VERSION ""

NS_ :

BS_:

BU_: ETH

BO_ 1825 VCFRONT_debugThermal1Hz: 8 Vector__XXX
 SG_ VCFRONT_debugThermal1HzIndex M : 0|4@1+ (1,0) [0|0] "" Vector__XXX
 SG_ VCFRONT_coolantPumpTypeConfig m8 : 4|4@1+ (1,0) [0|0] "" Vector__XXX
 SG_ VCFRONT_mdotRefEvap m6 : 4|10@1+ (0.1,0) [0|0] "" Vector__XXX
 SG_ VCFRONT_modeDesiredPrevious m2 : 4|2@1+ (1,0) [0|0] "" Vector__XXX
 SG_ VCFRONT_pumpBatOverCurrentError m4 : 4|1@1+ (1,0) [0|0] "" Vector__XXX
 SG_ VCFRONT_pumpBatVsUnderVoltage m4 : 5|1@1+ (1,0) [0|0] "" Vector__XXX
 SG_ VCFRONT_modeHysteresisActive m2 : 6|1@1+ (1,0) [0|0] "" Vector__XXX
 SG_ VCFRONT_pumpBatVsOverVoltage m4 : 6|1@1+ (1,0) [0|0] "" Vector__XXX
 SG_ VCFRONT_modeSeriesAttainable m2 : 7|1@1+ (1,0) [0|0] "" Vector__XXX
 SG_ VCFRONT_pumpBatChpUnderVoltage m4 : 7|1@1+ (1,0) [0|0] "" Vector__XXX
 SG_ VCFRONT_activeLouverSpeedCmd m1 : 8|7@1+ (1,0) [0|0] "" Vector__XXX
 SG_ VCFRONT_activeSeriesReg m0 : 8|7@1+ (1,0) [0|0] "" Vector__XXX
 SG_ VCFRONT_condenserTempLimit m5 : 8|6@1+ (1,80) [0|0] "" Vector__XXX
 SG_ VCFRONT_modeParallelAttainable m2 : 8|1@1+ (1,0) [0|0] "" Vector__XXX
 SG_ VCFRONT_passiveSeriesReg m3 : 8|8@1- (1,0) [0|0] "" Vector__XXX
 SG_ VCFRONT_pumpBatVglUnderVoltage m4 : 8|1@1+ (1,0) [0|0] "" Vector__XXX
 SG_ VCFRONT_refrigerantTypeConfig m8 : 8|4@1+ (1,0) [0|0] "" Vector__XXX
 SG_ VCFRONT_subcoolCabinCondenser m7 : 8|6@1+ (1,0) [0|0] "" Vector__XXX
 SG_ VCFRONT_modeAmbientSourceAttainable m2 : 9|1@1+ (1,0) [0|0] "" Vector__XXX
 SG_ VCFRONT_pumpBatFetShortCircuit m4 : 9|1@1+ (1,0) [0|0] "" Vector__XXX
 SG_ VCFRONT_modeCop1Attainable m2 : 10|1@1+ (1,0) [0|0] "" Vector__XXX
 SG_ VCFRONT_pumpBatThOverTemperature m4 : 10|1@1+ (1,0) [0|0] "" Vector__XXX
 SG_ VCFRONT_copEvapActiveSinceLastDrive m2 : 11|1@1+ (1,0) [0|0] "" Vector__XXX
 SG_ VCFRONT_pumpBatLockedRotor m4 : 11|1@1+ (1,0) [0|0] "" Vector__XXX
 SG_ VCFRONT_compressorTypeConfig m8 : 12|4@1+ (1,0) [0|0] "" Vector__XXX
 SG_ VCFRONT_pumpBatJunctionTempWarn m4 : 12|1@1+ (1,0) [0|0] "" Vector__XXX
 SG_ VCFRONT_pumpBatJunctionOverTemp m4 : 13|1@1+ (1,0) [0|0] "" Vector__XXX
 SG_ VCFRONT_condenserActivePID m5 : 14|1@1+ (1,0) [0|0] "" Vector__XXX
 SG_ VCFRONT_mdotRefChiller m6 : 14|10@1+ (0.1,0) [0|0] "" Vector__XXX
 SG_ VCFRONT_pumpBatWatchdogTimeout m4 : 14|1@1+ (1,0) [0|0] "" Vector__XXX
 SG_ VCFRONT_activeLouverDirection m1 : 15|1@1+ (1,0) [0|0] "" Vector__XXX
 SG_ VCFRONT_condenserFeedfwdForChiller m5 : 15|1@1+ (1,0) [0|0] "" Vector__XXX
 SG_ VCFRONT_pumpBatStartUpOperation m4 : 15|1@1+ (1,0) [0|0] "" Vector__XXX
 SG_ VCFRONT_activeLouverBrakeEngaged m1 : 16|1@1+ (1,0) [0|0] "" Vector__XXX
 SG_ VCFRONT_activeParallelPTReg m0 : 16|7@1+ (1,0) [0|0] "" Vector__XXX
 SG_ VCFRONT_condenserFeedfwdForEvap m5 : 16|1@1+ (1,0) [0|0] "" Vector__XXX
 SG_ VCFRONT_passiveParallelPTReg m3 : 16|7@1+ (1,0) [0|0] "" Vector__XXX
 SG_ VCFRONT_pumpBatLossOfSpeedLock m4 : 16|1@1+ (1,0) [0|0] "" Vector__XXX
 SG_ VCFRONT_pumpBattPolePairConfig m8 : 16|4@1+ (1,0) [0|0] "" Vector__XXX
 SG_ VCFRONT_subcoolLcc m7 : 16|6@1+ (1,0) [0|0] "" Vector__XXX
 SG_ VCFRONT_burnInState m1 : 17|3@1+ (1,0) [0|0] "" Vector__XXX
 SG_ VCFRONT_condenserRegDemand m5 : 17|7@1+ (1,0) [0|0] "" Vector__XXX
 SG_ VCFRONT_pumpBatVccUnderVoltage m4 : 17|1@1+ (1,0) [0|0] "" Vector__XXX
 SG_ VCFRONT_pumpBatPwmInputFault m4 : 18|1@1+ (1,0) [0|0] "" Vector__XXX
 SG_ VCFRONT_pumpBatStatMode m4 : 19|2@1+ (1,0) [0|0] "" Vector__XXX
 SG_ VCFRONT_pumpPtPolePairConfig m8 : 20|4@1+ (1,0) [0|0] "" Vector__XXX
 SG_ VCFRONT_pumpBatStatOTPAny m4 : 21|1@1+ (1,0) [0|0] "" Vector__XXX
 SG_ VCFRONT_pumpBatStatSPIFail m4 : 22|1@1+ (1,0) [0|0] "" Vector__XXX
 SG_ VCFRONT_passiveParallelPTRegOn m3 : 23|1@1+ (1,0) [0|0] "" Vector__XXX
 SG_ VCFRONT_pumpBatStatDiagFail m4 : 23|1@1+ (1,0) [0|0] "" Vector__XXX
 SG_ VCFRONT_activeParallelBattReg m0 : 24|7@1+ (1,0) [0|0] "" Vector__XXX
 SG_ VCFRONT_condenserMinFanReq m5 : 24|7@1+ (1,0) [0|0] "" Vector__XXX
 SG_ VCFRONT_mdotRefCabinCondenser m6 : 24|10@1+ (0.1,0) [0|0] "" Vector__XXX
 SG_ VCFRONT_passiveSeriesRegMaxd m3 : 24|1@1+ (1,0) [0|0] "" Vector__XXX
 SG_ VCFRONT_pumpPtOverCurrentError m4 : 24|1@1+ (1,0) [0|0] "" Vector__XXX
 SG_ VCFRONT_superheatEvap m7 : 24|6@1+ (1,0) [0|0] "" Vector__XXX
 SG_ VCFRONT_supermanifoldTypeConfig m8 : 24|4@1+ (1,0) [0|0] "" Vector__XXX
 SG_ VCFRONT_passiveParallelPTRegMaxd m3 : 25|1@1+ (1,0) [0|0] "" Vector__XXX
 SG_ VCFRONT_pumpPtVsUnderVoltage m4 : 25|1@1+ (1,0) [0|0] "" Vector__XXX
 SG_ VCFRONT_pumpPtVsOverVoltage m4 : 26|1@1+ (1,0) [0|0] "" Vector__XXX
 SG_ VCFRONT_pumpPtChpUnderVoltage m4 : 27|1@1+ (1,0) [0|0] "" Vector__XXX
 SG_ VCFRONT_pumpPtVglUnderVoltage m4 : 28|1@1+ (1,0) [0|0] "" Vector__XXX
 SG_ VCFRONT_refrigFilterTypeConfig m8 : 28|2@1+ (1,0) [0|0] "" Vector__XXX
 SG_ VCFRONT_pumpPtFetShortCircuit m4 : 29|1@1+ (1,0) [0|0] "" Vector__XXX
 SG_ VCFRONT_pumpPtThOverTemperature m4 : 30|1@1+ (1,0) [0|0] "" Vector__XXX
 SG_ VCFRONT_refrigLccTypeConfig m8 : 30|2@1+ (1,0) [0|0] "" Vector__XXX
 SG_ VCFRONT_activeSeriesRegOn m0 : 31|1@1+ (1,0) [0|0] "" Vector__XXX
 SG_ VCFRONT_pumpPtLockedRotor m4 : 31|1@1+ (1,0) [0|0] "" Vector__XXX
 SG_ VCFRONT_activeParallelPTRegOn m0 : 32|1@1+ (1,0) [0|0] "" Vector__XXX
 SG_ VCFRONT_condenserMinLouverReq m5 : 32|7@1+ (1,0) [0|0] "" Vector__XXX
 SG_ VCFRONT_passiveDemandPumpPT m3 : 32|7@1+ (1,0) [0|0] "" Vector__XXX
 SG_ VCFRONT_pumpPtJunctionTempWarn m4 : 32|1@1+ (1,0) [0|0] "" Vector__XXX
 SG_ VCFRONT_superheatChiller m7 : 32|6@1+ (1,0) [0|0] "" Vector__XXX
 SG_ VCFRONT_activeParallelBattRegOn m0 : 33|1@1+ (1,0) [0|0] "" Vector__XXX
 SG_ VCFRONT_pumpPtJunctionOverTemp m4 : 33|1@1+ (1,0) [0|0] "" Vector__XXX
 SG_ VCFRONT_activeDemandPumpPT m0 : 34|7@1+ (1,0) [0|0] "" Vector__XXX
 SG_ VCFRONT_mdotRefLcc m6 : 34|10@1+ (0.1,0) [0|0] "" Vector__XXX
 SG_ VCFRONT_pumpPtWatchdogTimeout m4 : 34|1@1+ (1,0) [0|0] "" Vector__XXX
 SG_ VCFRONT_pumpPtStartUpOperation m4 : 35|1@1+ (1,0) [0|0] "" Vector__XXX
 SG_ VCFRONT_pumpPtLossOfSpeedLock m4 : 36|1@1+ (1,0) [0|0] "" Vector__XXX
 SG_ VCFRONT_pumpPtVccUnderVoltage m4 : 37|1@1+ (1,0) [0|0] "" Vector__XXX
 SG_ VCFRONT_pumpPtPwmInputFault m4 : 38|1@1+ (1,0) [0|0] "" Vector__XXX
 SG_ VCFRONT_pumpPtStatMode m4 : 39|2@1+ (1,0) [0|0] "" Vector__XXX
 SG_ VCFRONT_passiveDemandPumpBatt m3 : 40|7@1+ (1,0) [0|0] "" Vector__XXX
 SG_ VCFRONT_activeDemandPumpBatt m0 : 41|7@1+ (1,0) [0|0] "" Vector__XXX
 SG_ VCFRONT_pumpPtStatOTPAny m4 : 41|1@1+ (1,0) [0|0] "" Vector__XXX
 SG_ VCFRONT_pumpPtStatSPIFail m4 : 42|1@1+ (1,0) [0|0] "" Vector__XXX
 SG_ VCFRONT_pumpPtStatDiagFail m4 : 43|1@1+ (1,0) [0|0] "" Vector__XXX
 SG_ VCFRONT_fanRadOverCurrentError m4 : 44|1@1+ (1,0) [0|0] "" Vector__XXX
 SG_ VCFRONT_fanRadVsUnderVoltage m4 : 45|1@1+ (1,0) [0|0] "" Vector__XXX
 SG_ VCFRONT_fanRadVsOverVoltage m4 : 46|1@1+ (1,0) [0|0] "" Vector__XXX
 SG_ VCFRONT_fanRadChpUnderVoltage m4 : 47|1@1+ (1,0) [0|0] "" Vector__XXX
 SG_ VCFRONT_activeDemandFanRad m0 : 48|7@1+ (1,0) [0|0] "" Vector__XXX
 SG_ VCFRONT_fanRadVglUnderVoltage m4 : 48|1@1+ (1,0) [0|0] "" Vector__XXX
 SG_ VCFRONT_passiveDemandLouver m3 : 48|7@1+ (1,0) [0|0] "" Vector__XXX
 SG_ VCFRONT_fanRadFetShortCircuit m4 : 49|1@1+ (1,0) [0|0] "" Vector__XXX
 SG_ VCFRONT_fanRadThOverTemperature m4 : 50|1@1+ (1,0) [0|0] "" Vector__XXX
 SG_ VCFRONT_fanRadLockedRotor m4 : 51|1@1+ (1,0) [0|0] "" Vector__XXX
 SG_ VCFRONT_fanRadJunctionTempWarn m4 : 52|1@1+ (1,0) [0|0] "" Vector__XXX
 SG_ VCFRONT_fanRadJunctionOverTemp m4 : 53|1@1+ (1,0) [0|0] "" Vector__XXX
 SG_ VCFRONT_fanRadWatchdogTimeout m4 : 54|1@1+ (1,0) [0|0] "" Vector__XXX
 SG_ VCFRONT_activeDemandChiller m0 : 55|7@1+ (1,0) [0|0] "" Vector__XXX
 SG_ VCFRONT_fanRadStartUpOperation m4 : 55|1@1+ (1,0) [0|0] "" Vector__XXX
 SG_ VCFRONT_fanRadLossOfSpeedLock m4 : 56|1@1+ (1,0) [0|0] "" Vector__XXX
 SG_ VCFRONT_fanRadVccUnderVoltage m4 : 57|1@1+ (1,0) [0|0] "" Vector__XXX
 SG_ VCFRONT_fanRadPwmInputFault m4 : 58|1@1+ (1,0) [0|0] "" Vector__XXX
 SG_ VCFRONT_fanRadStatMode m4 : 59|2@1+ (1,0) [0|0] "" Vector__XXX
 SG_ VCFRONT_fanRadStatOTPAny m4 : 61|1@1+ (1,0) [0|0] "" Vector__XXX
 SG_ VCFRONT_fanRadStatSPIFail m4 : 62|1@1+ (1,0) [0|0] "" Vector__XXX
 SG_ VCFRONT_fanRadStatDiagFail m4 : 63|1@1+ (1,0) [0|0] "" Vector__XXX

BO_ 1828 VCFRONT_loadShedDebugStatus: 8 Vector__XXX
 SG_ VCFRONT_loadShedDebugStatusIndex M : 0|4@1+ (1,0) [0|0] "" Vector__XXX
 SG_ VCFRONT_loadShedReasonAPHeater m0 : 4|9@1+ (1,0) [0|0] "" Vector__XXX
 SG_ VCFRONT_loadShedReasonAutopilot m5 : 4|9@1+ (1,0) [0|0] "" Vector__XXX
 SG_ VCFRONT_loadShedReasonBatteryPump m1 : 4|9@1+ (1,0) [0|0] "" Vector__XXX
 SG_ VCFRONT_loadShedReasonCondenserFan m2 : 4|9@1+ (1,0) [0|0] "" Vector__XXX
 SG_ VCFRONT_loadShedReasonMCUAudio m8 : 4|9@1+ (1,0) [0|0] "" Vector__XXX
 SG_ VCFRONT_loadShedReasonMCUGraphic m7 : 4|9@1+ (1,0) [0|0] "" Vector__XXX
 SG_ VCFRONT_loadShedReasonPCS m9 : 4|9@1+ (1,0) [0|0] "" Vector__XXX
 SG_ VCFRONT_loadShedReasonPTPump m3 : 4|9@1+ (1,0) [0|0] "" Vector__XXX
 SG_ VCFRONT_loadShedReasonTAS m4 : 4|9@1+ (1,0) [0|0] "" Vector__XXX
 SG_ VCFRONT_loadShedReasonUI m6 : 4|9@1+ (1,0) [0|0] "" Vector__XXX
 SG_ VCFRONT_loadShedStsBatteryPump_duty m1 : 16|7@1+ (1,0) [0|0] "" Vector__XXX
 SG_ VCFRONT_loadShedStsCondenserFan_duty m2 : 16|7@1+ (1,0) [0|0] "" Vector__XXX
 SG_ VCFRONT_loadShedStsPTPump_duty m3 : 16|7@1+ (1,0) [0|0] "" Vector__XXX

BO_ 1829 VCBATT2_loadShedDebugStatus: 8 Vector__XXX
 SG_ VCBATT2_loadShedDebugStatusIndex M : 0|4@1+ (1,0) [0|0] "" Vector__XXX
 SG_ VCBATT2_loadShedReasonAPHeater m0 : 4|9@1+ (1,0) [0|0] "" Vector__XXX
 SG_ VCBATT2_loadShedReasonAutopilot m5 : 4|9@1+ (1,0) [0|0] "" Vector__XXX
 SG_ VCBATT2_loadShedReasonBatteryPump m1 : 4|9@1+ (1,0) [0|0] "" Vector__XXX
 SG_ VCBATT2_loadShedReasonCondenserFan m2 : 4|9@1+ (1,0) [0|0] "" Vector__XXX
 SG_ VCBATT2_loadShedReasonMCUAudio m8 : 4|9@1+ (1,0) [0|0] "" Vector__XXX
 SG_ VCBATT2_loadShedReasonMCUGraphic m7 : 4|9@1+ (1,0) [0|0] "" Vector__XXX
 SG_ VCBATT2_loadShedReasonPCS m9 : 4|9@1+ (1,0) [0|0] "" Vector__XXX
 SG_ VCBATT2_loadShedReasonPTPump m3 : 4|9@1+ (1,0) [0|0] "" Vector__XXX
 SG_ VCBATT2_loadShedReasonTAS m4 : 4|9@1+ (1,0) [0|0] "" Vector__XXX
 SG_ VCBATT2_loadShedReasonUI m6 : 4|9@1+ (1,0) [0|0] "" Vector__XXX
 SG_ VCBATT2_loadShedStsBatteryPump_duty m1 : 16|7@1+ (1,0) [0|0] "" Vector__XXX
 SG_ VCBATT2_loadShedStsCondenserFan_duty m2 : 16|7@1+ (1,0) [0|0] "" Vector__XXX
 SG_ VCBATT2_loadShedStsPTPump_duty m3 : 16|7@1+ (1,0) [0|0] "" Vector__XXX

BO_ 1830 VCLEFT_loadShedDebugStatus: 8 Vector__XXX
 SG_ VCLEFT_loadShedDebugStatusIndex M : 0|4@1+ (1,0) [0|0] "" Vector__XXX
 SG_ VCLEFT_loadShedReason12VAuxLoads m0 : 8|7@1+ (1,0) [0|0] "" Vector__XXX
 SG_ VCLEFT_loadShedReasonHVACBlower m1 : 8|7@1+ (1,0) [0|0] "" Vector__XXX
 SG_ VCLEFT_loadShedReasonLiftgate m2 : 8|7@1+ (1,0) [0|0] "" Vector__XXX
 SG_ VCLEFT_loadShedReasonMirrorHeater m3 : 8|7@1+ (1,0) [0|0] "" Vector__XXX
 SG_ VCLEFT_loadShedReasonMotorEncoders m4 : 8|7@1+ (1,0) [0|0] "" Vector__XXX
 SG_ VCLEFT_loadShedReasonSTWInOut m10 : 8|7@1+ (1,0) [0|0] "" Vector__XXX
 SG_ VCLEFT_loadShedReasonSTWUpDown m11 : 8|7@1+ (1,0) [0|0] "" Vector__XXX
 SG_ VCLEFT_loadShedReasonSeatBackrest m5 : 8|7@1+ (1,0) [0|0] "" Vector__XXX
 SG_ VCLEFT_loadShedReasonSeatHeaters m7 : 8|7@1+ (1,0) [0|0] "" Vector__XXX
 SG_ VCLEFT_loadShedReasonSeatLift m6 : 8|7@1+ (1,0) [0|0] "" Vector__XXX
 SG_ VCLEFT_loadShedReasonSeatTilt m8 : 8|7@1+ (1,0) [0|0] "" Vector__XXX
 SG_ VCLEFT_loadShedReasonSeatTrack m9 : 8|7@1+ (1,0) [0|0] "" Vector__XXX
 SG_ VCLEFT_loadShedReasonUSBPorts m12 : 8|7@1+ (1,0) [0|0] "" Vector__XXX
 SG_ VCLEFT_loadShedReasonWindowMotorsFront m13 : 8|7@1+ (1,0) [0|0] "" Vector__XXX
 SG_ VCLEFT_loadShedReasonWindowMotorsRear m14 : 8|7@1+ (1,0) [0|0] "" Vector__XXX
 SG_ VCLEFT_loadShedStsHVACBlower_duty m1 : 16|7@1+ (1,0) [0|0] "" Vector__XXX

BO_ 1831 VCRIGHT_loadShedDebugStatus: 8 Vector__XXX
 SG_ VCRIGHT_loadShedDebugStatusIndex M : 0|4@1+ (1,0) [0|0] "" Vector__XXX
 SG_ VCRIGHT_loadShedReasonMirrorHeater m0 : 8|7@1+ (1,0) [0|0] "" Vector__XXX
 SG_ VCRIGHT_loadShedReasonMotorEncoders m1 : 8|7@1+ (1,0) [0|0] "" Vector__XXX
 SG_ VCRIGHT_loadShedReasonPremAudio m2 : 8|7@1+ (1,0) [0|0] "" Vector__XXX
 SG_ VCRIGHT_loadShedReasonRearDefroster m3 : 8|7@1+ (1,0) [0|0] "" Vector__XXX
 SG_ VCRIGHT_loadShedReasonSeatBackrest m4 : 8|7@1+ (1,0) [0|0] "" Vector__XXX
 SG_ VCRIGHT_loadShedReasonSeatHeaters m5 : 8|7@1+ (1,0) [0|0] "" Vector__XXX
 SG_ VCRIGHT_loadShedReasonSeatLift m6 : 8|7@1+ (1,0) [0|0] "" Vector__XXX
 SG_ VCRIGHT_loadShedReasonSeatTilt m7 : 8|7@1+ (1,0) [0|0] "" Vector__XXX
 SG_ VCRIGHT_loadShedReasonSeatTrack m8 : 8|7@1+ (1,0) [0|0] "" Vector__XXX
 SG_ VCRIGHT_loadShedReasonUSBPorts m9 : 8|7@1+ (1,0) [0|0] "" Vector__XXX
 SG_ VCRIGHT_loadShedReasonWindowMotorsFront m10 : 8|7@1+ (1,0) [0|0] "" Vector__XXX
 SG_ VCRIGHT_loadShedReasonWindowMotorsRear m11 : 8|7@1+ (1,0) [0|0] "" Vector__XXX

BO_ 1834 BMS_serialNumber: 8 Vector__XXX
 SG_ BMS_serialNumberMultiplexer M : 0|2@1+ (1,0) [0|0] "" Vector__XXX
 SG_ BMS_packSerialBirthDateBinned m2 : 8|32@1+ (1,0) [0|0] "" Vector__XXX
 SG_ BMS_packSerialNumberByte01 m0 : 8|8@1+ (1,0) [0|0] "" Vector__XXX
 SG_ BMS_packSerialNumberByte08 m1 : 8|8@1+ (1,0) [0|0] "" Vector__XXX
 SG_ BMS_packSerialNumberByte02 m0 : 16|8@1+ (1,0) [0|0] "" Vector__XXX
 SG_ BMS_packSerialNumberByte09 m1 : 16|8@1+ (1,0) [0|0] "" Vector__XXX
 SG_ BMS_packSerialNumberByte03 m0 : 24|8@1+ (1,0) [0|0] "" Vector__XXX
 SG_ BMS_packSerialNumberByte10 m1 : 24|8@1+ (1,0) [0|0] "" Vector__XXX
 SG_ BMS_packSerialNumberByte04 m0 : 32|8@1+ (1,0) [0|0] "" Vector__XXX
 SG_ BMS_packSerialNumberByte11 m1 : 32|8@1+ (1,0) [0|0] "" Vector__XXX
 SG_ BMS_packSerialNumberByte05 m0 : 40|8@1+ (1,0) [0|0] "" Vector__XXX
 SG_ BMS_packSerialNumberByte12 m1 : 40|8@1+ (1,0) [0|0] "" Vector__XXX
 SG_ BMS_packSerialNumberByte06 m0 : 48|8@1+ (1,0) [0|0] "" Vector__XXX
 SG_ BMS_packSerialNumberByte13 m1 : 48|8@1+ (1,0) [0|0] "" Vector__XXX
 SG_ BMS_packSerialNumberByte07 m0 : 56|8@1+ (1,0) [0|0] "" Vector__XXX
 SG_ BMS_packSerialNumberByte14 m1 : 56|8@1+ (1,0) [0|0] "" Vector__XXX

BO_ 1835 XCP_tasRequest: 12 Vector__XXX
 SG_ XCP_tasRequest : 7|64@0+ (1,0) [0|0] "" Vector__XXX

BO_ 1842 XCP_bmsRequest: 12 Vector__XXX
 SG_ XCP_bmsRequestData : 7|64@0+ (1,0) [0|0] "" Vector__XXX

BO_ 1847 VCFRONT_LVBMS_info: 8 Vector__XXX
 SG_ VCFRONT_LVBMS_InfoIndex M : 0|8@1+ (1,0) [0|0] "" Vector__XXX
 SG_ VCFRONT_LVBMS_FWBuildType m3 : 8|8@1+ (1,0) [0|0] "" Vector__XXX
 SG_ VCFRONT_LVBMS_GitHash m2 : 8|16@1+ (1,0) [0|0] "" Vector__XXX
 SG_ VCFRONT_LVBMS_PcbaId m0 : 8|16@1+ (1,0) [0|0] "" Vector__XXX
 SG_ VCFRONT_LVBMS_UsageId m1 : 8|16@1+ (1,0) [0|0] "" Vector__XXX
 SG_ VCFRONT_LVBMS_serialNumber m4 : 8|24@1+ (1,0) [0|0] "" Vector__XXX
 SG_ VCFRONT_LVBMS_AppCRC m1 : 24|32@1+ (1,0) [0|0] "" Vector__XXX
 SG_ VCFRONT_LVBMS_AssemblyId m0 : 24|16@1+ (1,0) [0|0] "" Vector__XXX
 SG_ VCFRONT_LVBMS_mfgDay m4 : 32|5@1+ (1,0) [0|0] "" Vector__XXX
 SG_ VCFRONT_LVBMS_SubUsageId m0 : 40|16@1+ (1,0) [0|0] "" Vector__XXX
 SG_ VCFRONT_LVBMS_mfgMonth m4 : 40|4@1+ (1,0) [0|0] "" Vector__XXX
 SG_ VCFRONT_LVBMS_mfgYear m4 : 48|7@1+ (1,2011) [0|0] "" Vector__XXX

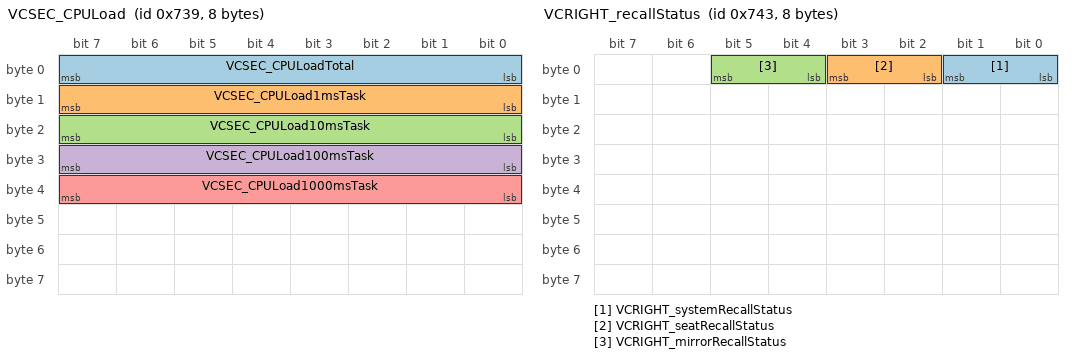
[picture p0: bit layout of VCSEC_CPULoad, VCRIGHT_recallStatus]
BO_ 1849 VCSEC_CPULoad: 8 Vector__XXX
 SG_ VCSEC_CPULoadTotal : 0|8@1+ (1,0) [0|0] "" Vector__XXX
 SG_ VCSEC_CPULoad1msTask : 8|8@1+ (1,0) [0|0] "" Vector__XXX
 SG_ VCSEC_CPULoad10msTask : 16|8@1+ (1,0) [0|0] "" Vector__XXX
 SG_ VCSEC_CPULoad100msTask : 24|8@1+ (1,0) [0|0] "" Vector__XXX
 SG_ VCSEC_CPULoad1000msTask : 32|8@1+ (1,0) [0|0] "" Vector__XXX

BO_ 1850 VC_LVBMS_brickMeasurements: 8 Vector__XXX
 SG_ VC_LVBMS_brickMeasurementsMultiplexer M : 0|6@1+ (1,0) [0|0] "" Vector__XXX
 SG_ VC_LVBMS_brickBalancingAh1 m1 : 8|24@1+ (0.001,0) [0|0] "" Vector__XXX
 SG_ VC_LVBMS_brickBalancingAh3 m2 : 8|24@1+ (0.001,0) [0|0] "" Vector__XXX
 SG_ VC_LVBMS_brickVoltage1 m0 : 8|13@1+ (0.001,0) [0|0] "" Vector__XXX
 SG_ VC_LVBMS_brickVoltage2 m0 : 24|13@1+ (0.001,0) [0|0] "" Vector__XXX
 SG_ VC_LVBMS_brickBalancingAh2 m1 : 32|24@1+ (0.001,0) [0|0] "" Vector__XXX
 SG_ VC_LVBMS_brickBalancingAh4 m2 : 32|24@1+ (0.001,0) [0|0] "" Vector__XXX
 SG_ VC_LVBMS_brickVoltage3 m0 : 37|13@1+ (0.001,0) [0|0] "" Vector__XXX
 SG_ VC_LVBMS_brickVoltage4 m0 : 50|13@1+ (0.001,0) [0|0] "" Vector__XXX
 SG_ VC_LVBMS_brickBalancingState1 m1 : 56|1@1+ (1,0) [0|0] "" Vector__XXX
 SG_ VC_LVBMS_brickBalancingState3 m2 : 56|1@1+ (1,0) [0|0] "" Vector__XXX
 SG_ VC_LVBMS_brickBalancingState2 m1 : 57|1@1+ (1,0) [0|0] "" Vector__XXX
 SG_ VC_LVBMS_brickBalancingState4 m2 : 57|1@1+ (1,0) [0|0] "" Vector__XXX

BO_ 1851 TAS_xcpResponse: 12 Vector__XXX
 SG_ TAS_xcpResponse : 7|64@0+ (1,0) [0|0] "" Vector__XXX

BO_ 1853 SDCR_debug: 8 Vector__XXX
 SG_ SDCR_debugOutputIndex M : 0|3@1+ (1,0) [0|0] "" Vector__XXX
 SG_ SDCR_cpuUsageCumulative m4 : 3|10@1+ (0.1,0) [0|0] "" Vector__XXX
 SG_ SDCR_vPhaseA m2 : 3|12@1+ (0.4,0) [0|0] "" Vector__XXX
 SG_ SDCR_busBarTempC m3 : 8|8@1+ (1,-40) [0|0] "" Vector__XXX
 SG_ SDCR_elcSpeed m1 : 8|16@1- (0.1,0) [0|0] "" Vector__XXX
 SG_ SDCR_pyroSenseV m0 : 8|8@1+ (0.02,0) [0|0] "" Vector__XXX
 SG_ SDCR_cpuUsage1MS m4 : 13|10@1+ (0.1,0) [0|0] "" Vector__XXX
 SG_ SDCR_busBarTempA m3 : 16|8@1+ (1,-40) [0|0] "" Vector__XXX
 SG_ SDCR_vPhaseB m2 : 16|12@1+ (0.4,0) [0|0] "" Vector__XXX
 SG_ SDCR_vref m0 : 16|8@1+ (0.02,0) [0|0] "" Vector__XXX
 SG_ SDCR_cpuUsage10MS m4 : 24|10@1+ (0.1,0) [0|0] "" Vector__XXX
 SG_ SDCR_lastMaxAbsSpeed m1 : 24|16@1- (0.1,0) [0|0] "" Vector__XXX
 SG_ SDCR_magI2 m0 : 24|16@1+ (34.33279926756695,0) [0|0] "" Vector__XXX
 SG_ SDCR_vPhaseC m2 : 28|12@1+ (0.4,0) [0|0] "" Vector__XXX
 SG_ SDCR_cpuUsage100MS m4 : 34|10@1+ (0.1,0) [0|0] "" Vector__XXX
 SG_ SDCR_maxSampleTime m1 : 40|12@1+ (0.1,0) [0|0] "" Vector__XXX
 SG_ SDCR_cpuUsageISR m4 : 44|10@1+ (0.1,0) [0|0] "" Vector__XXX
 SG_ SDCR_accumulatedSampleTime m1 : 52|12@1+ (0.1,0) [0|0] "" Vector__XXX

BO_ 1854 GB_vehLogData: 8 Vector__XXX
 SG_ GB_vehLogDataSelect M : 0|4@1+ (1,0) [0|0] "" Vector__XXX
 SG_ VEH_GB_Chg_Allowed m7 : 4|1@1+ (1,0) [0|0] "" Vector__XXX
 SG_ VEH_GB_Chg_ID_00_Tmt m11 : 4|2@1+ (1,0) [0|0] "" Vector__XXX
 SG_ VEH_GB_Chg_Stop_Rsn_SOC m9 : 4|2@1+ (1,0) [0|0] "" Vector__XXX
 SG_ VEH_GB_kwhChargeTotal_sent m8 : 4|1@1+ (1,0) [0|0] "" Vector__XXX
 SG_ VEH_teslaVin_muxSent m14 : 4|2@1+ (1,0) [0|0] "" Vector__XXX
 SG_ VEH_GB_Chg_ID_AA_Tmt m11 : 6|2@1+ (1,0) [0|0] "" Vector__XXX
 SG_ VEH_GB_Chg_Stop_Rsn_Pack_V m9 : 6|2@1+ (1,0) [0|0] "" Vector__XXX
 SG_ VEH_GB_BAT_Max_V_BHM m0 : 8|16@1+ (0.1,0) [0|0] "" Vector__XXX
 SG_ VEH_GB_BAT_Mfr_Name m2 : 8|32@1+ (1,0) [0|0] "" Vector__XXX
 SG_ VEH_GB_Chg_Max_I m3 : 8|16@1+ (0.1,-400) [0|0] "" Vector__XXX
 SG_ VEH_GB_Chg_Max_Output_Tmt m11 : 8|2@1+ (1,0) [0|0] "" Vector__XXX
 SG_ VEH_GB_Chg_Stop_Rsn_Cell_V m9 : 8|2@1+ (1,0) [0|0] "" Vector__XXX
 SG_ VEH_GB_Current_Demand m5 : 8|16@1+ (0.1,-400) [0|0] "" Vector__XXX
 SG_ VEH_GB_Final_SOC m10 : 8|8@1+ (1,0) [0|0] "" Vector__XXX
 SG_ VEH_GB_Meas_V m6 : 8|16@1+ (0.1,0) [0|0] "" Vector__XXX
 SG_ VEH_GB_Protocol_Ver_log m1 : 8|24@1+ (1,0) [0|0] "" Vector__XXX
 SG_ VEH_GB_Status m4 : 8|8@1+ (1,0) [0|0] "" Vector__XXX
 SG_ VEH_currentDemand_value_log m13 : 8|16@1- (1,0) [0|0] "" Vector__XXX
 SG_ VEH_teslaGbProtocolVersion_log m12 : 8|8@1+ (1,0) [0|0] "" Vector__XXX
 SG_ VEH_GB_CHG_Readiness_Tmt m11 : 10|2@1+ (1,0) [0|0] "" Vector__XXX
 SG_ VEH_GB_Chg_Stop_Rsn_CST m9 : 10|2@1+ (1,0) [0|0] "" Vector__XXX
 SG_ VEH_GB_Chg_Status_Tmt m11 : 12|2@1+ (1,0) [0|0] "" Vector__XXX
 SG_ VEH_GB_Chg_Stop_Rsn_Insul_Fault m9 : 12|2@1+ (1,0) [0|0] "" Vector__XXX
 SG_ VEH_GB_Chg_Stop_Rsn_Conn_OT_FLT m9 : 14|2@1+ (1,0) [0|0] "" Vector__XXX
 SG_ VEH_GB_Chg_Stop_Tmt m11 : 14|2@1+ (1,0) [0|0] "" Vector__XXX
 SG_ VEH_GB_Chg_Statistics_Tmt m11 : 16|2@1+ (1,0) [0|0] "" Vector__XXX
 SG_ VEH_GB_Chg_Stop_Rsn_BMS_OT_FLT m9 : 16|2@1+ (1,0) [0|0] "" Vector__XXX
 SG_ VEH_GB_Chg_Other_Tmt m11 : 18|6@1+ (1,0) [0|0] "" Vector__XXX
 SG_ VEH_GB_Chg_Stop_Rsn_Conn_FLT m9 : 18|2@1+ (1,0) [0|0] "" Vector__XXX
 SG_ VEH_GB_Chg_Stop_Rsn_Pack_OT_FLT m9 : 20|2@1+ (1,0) [0|0] "" Vector__XXX
 SG_ VEH_GB_Chg_Stop_Rsn_HVRelay_FLT m9 : 22|2@1+ (1,0) [0|0] "" Vector__XXX
 SG_ VEH_GB_BAT_SOC m3 : 24|16@1+ (0.1,0) [0|0] "" Vector__XXX
 SG_ VEH_GB_Chg_Stop_Rsn_VPt2_FLT m9 : 24|2@1+ (1,0) [0|0] "" Vector__XXX
 SG_ VEH_GB_Meas_I m6 : 24|16@1+ (0.1,-400) [0|0] "" Vector__XXX
 SG_ VEH_chargeCurrent_value_log m13 : 24|16@1- (1,0) [0|0] "" Vector__XXX
 SG_ VEH_GB_Chg_Stop_Rsn_Other_FLT m9 : 26|2@1+ (1,0) [0|0] "" Vector__XXX
 SG_ VEH_GB_Chg_Stop_Rsn_OC_ERR m9 : 28|2@1+ (1,0) [0|0] "" Vector__XXX
 SG_ VEH_GB_Chg_Stop_Rsn_V_ERR m9 : 30|2@1+ (1,0) [0|0] "" Vector__XXX
 SG_ VEH_GB_BAT_Cap_Ah m1 : 32|16@1+ (0.1,0) [0|0] "" Vector__XXX
 SG_ VEH_GB_Chg_Stop_Rsn_Param_Mismatch m9 : 32|2@1+ (1,0) [0|0] "" Vector__XXX
 SG_ VEH_GB_BAT_V m3 : 40|16@1+ (0.1,0) [0|0] "" Vector__XXX
 SG_ VEH_GB_SOC m6 : 40|8@1+ (1,0) [0|0] "" Vector__XXX
 SG_ VEH_currentDemand_exp_log m13 : 40|3@1- (1,0) [0|0] "" Vector__XXX
 SG_ VEH_chargeCurrent_exp_log m13 : 43|3@1- (1,0) [0|0] "" Vector__XXX
 SG_ VEH_GB_BAT_Max_V_BRM m1 : 48|16@1+ (0.1,0) [0|0] "" Vector__XXX
 SG_ VEH_GB_Rem_Chg_Time_Mins m6 : 48|16@1+ (1,0) [0|0] "" Vector__XXX

BO_ 1858 VCBATT1_LVBMS_statusHigh: 8 Vector__XXX
 SG_ VCBATT1_lvbmsStatusHighIndex M : 0|3@1+ (1,0) [0|0] "" Vector__XXX
 SG_ VCBATT1_LVBMS_MOSCommand m4 : 3|1@1+ (1,0) [0|0] "" Vector__XXX
 SG_ VCBATT1_LVBMS_packCurrent m0 : 3|22@1+ (0.001,-2000) [0|0] "" Vector__XXX
 SG_ VCBATT1_LVBMS_voltageTarget m3 : 3|16@1+ (0.001,0) [0|0] "" Vector__XXX
 SG_ VCBATT1_LVBMS_ClearErrorCntrCommand m4 : 4|1@1+ (1,0) [0|0] "" Vector__XXX
 SG_ VCBATT1_LVBMS_ClearHistoricFaultCommand m4 : 5|1@1+ (1,0) [0|0] "" Vector__XXX
 SG_ VCBATT1_LVBMS_ResetLVBMSCommand m4 : 6|1@1+ (1,0) [0|0] "" Vector__XXX
 SG_ VCBATT1_LVBMS_EnterHibernationCommand m4 : 7|1@1+ (1,0) [0|0] "" Vector__XXX
 SG_ VCBATT1_LVBMS_ECPAState m4 : 8|2@1+ (1,0) [0|0] "" Vector__XXX
 SG_ VCBATT1_LVBMS_sumCellVoltage m1 : 8|16@1+ (0.001,0) [0|0] "" Vector__XXX
 SG_ VCBATT1_totalLVLoadCurrent m2 : 8|14@1- (0.1,0) [0|0] "" Vector__XXX
 SG_ VCBATT1_LVBMS_MOSState m4 : 10|2@1+ (1,0) [0|0] "" Vector__XXX
 SG_ VCBATT1_LVBMS_VehicleState m4 : 12|2@1+ (1,0) [0|0] "" Vector__XXX
 SG_ VCBATT1_LVBMS_LINWakeDisabled m4 : 14|1@1+ (1,0) [0|0] "" Vector__XXX
 SG_ VCBATT1_LVBMS_chargeType m4 : 16|3@1+ (1,0) [0|0] "" Vector__XXX
 SG_ VCBATT1_LVBMS_cellAndArcProtEnabled m4 : 19|1@1+ (1,0) [0|0] "" Vector__XXX
 SG_ VCBATT1_LVBMS_currentTarget m3 : 19|18@1+ (0.001,-122) [0|0] "" Vector__XXX
 SG_ VCBATT1_LVPackChargeCurrentLimit m2 : 22|12@1+ (0.1,0) [0|0] "" Vector__XXX
 SG_ VCBATT1_LVBMS_avgBrickVoltage m4 : 24|13@1+ (0.001,0) [0|0] "" Vector__XXX
 SG_ VCBATT1_LVBMS_maxBrickVoltage m1 : 24|13@1+ (0.001,0) [0|0] "" Vector__XXX
 SG_ VCBATT1_LVBMS_packVoltage m0 : 25|16@1+ (0.001,0) [0|0] "" Vector__XXX
 SG_ VCBATT1_LVPackCurrent m2 : 34|14@1- (0.1,0) [0|0] "" Vector__XXX
 SG_ VCBATT1_LVBMS_maxAllowedChargeCurrent m3 : 37|13@1+ (0.1,0) [0|0] "" Vector__XXX
 SG_ VCBATT1_LVBMS_maxBrickVoltageIndex m1 : 40|8@1+ (1,0) [0|0] "" Vector__XXX
 SG_ VCBATT1_LVBMS_minBrickVoltage m4 : 40|13@1+ (0.001,0) [0|0] "" Vector__XXX
 SG_ VCBATT1_LVBMS_packTemperature m0 : 41|9@1+ (0.5,-50) [0|0] "" Vector__XXX
 SG_ VCBATT1_LVBMS_estimatedPackOcv m2 : 48|16@1+ (0.001,0) [0|0] "" Vector__XXX
 SG_ VCBATT1_LVBMS_MOSTemperature m0 : 50|12@1+ (0.5,-50) [0|0] "" Vector__XXX
 SG_ VCBATT1_LVBMS_maxAllowedDischargeCurrent m3 : 50|13@1+ (0.1,0) [0|0] "" Vector__XXX
 SG_ VCBATT1_LVBMS_minBrickVoltageIndex m4 : 56|8@1+ (1,0) [0|0] "" Vector__XXX

BO_ 1859 VCRIGHT_recallStatus: 8 Vector__XXX
 SG_ VCRIGHT_systemRecallStatus : 0|2@1+ (1,0) [0|0] "" Vector__XXX
 SG_ VCRIGHT_seatRecallStatus : 2|2@1+ (1,0) [0|0] "" Vector__XXX
 SG_ VCRIGHT_mirrorRecallStatus : 4|2@1+ (1,0) [0|0] "" Vector__XXX

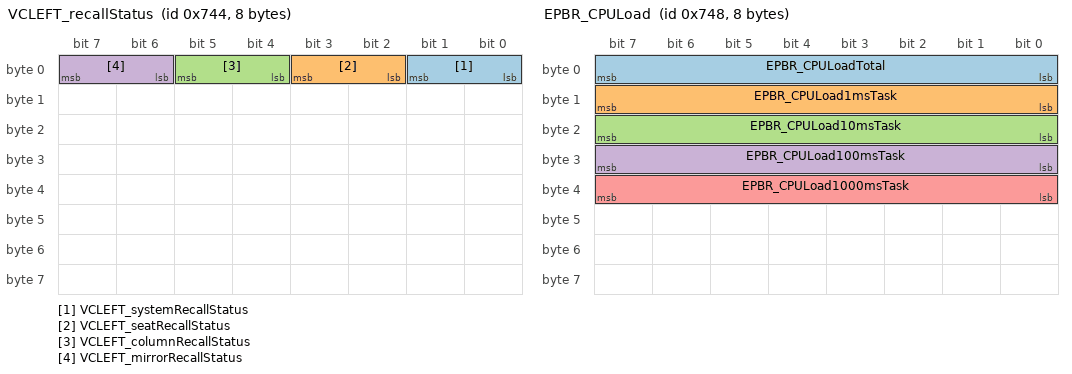
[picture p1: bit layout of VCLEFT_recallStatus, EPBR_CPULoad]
BO_ 1860 VCLEFT_recallStatus: 8 Vector__XXX
 SG_ VCLEFT_systemRecallStatus : 0|2@1+ (1,0) [0|0] "" Vector__XXX
 SG_ VCLEFT_seatRecallStatus : 2|2@1+ (1,0) [0|0] "" Vector__XXX
 SG_ VCLEFT_columnRecallStatus : 4|2@1+ (1,0) [0|0] "" Vector__XXX
 SG_ VCLEFT_mirrorRecallStatus : 6|2@1+ (1,0) [0|0] "" Vector__XXX

BO_ 1863 DBG_vdcControl: 8 Vector__XXX
 SG_ DBG_vdcDebugEnable : 0|1@1+ (1,0) [0|0] "" Vector__XXX

BO_ 1864 EPBR_CPULoad: 8 Vector__XXX
 SG_ EPBR_CPULoadTotal : 0|8@1+ (1,0) [0|0] "" Vector__XXX
 SG_ EPBR_CPULoad1msTask : 8|8@1+ (1,0) [0|0] "" Vector__XXX
 SG_ EPBR_CPULoad10msTask : 16|8@1+ (1,0) [0|0] "" Vector__XXX
 SG_ EPBR_CPULoad100msTask : 24|8@1+ (1,0) [0|0] "" Vector__XXX
 SG_ EPBR_CPULoad1000msTask : 32|8@1+ (1,0) [0|0] "" Vector__XXX

BO_ 1870 XCP_pmRequest: 12 Vector__XXX
 SG_ XCP_pmRequestData : 7|64@0+ (1,0) [0|0] "" Vector__XXX

BO_ 1871 PM_xcpResponse: 12 Vector__XXX
 SG_ PM_xcpResponseData : 7|64@0+ (1,0) [0|0] "" Vector__XXX

BO_ 1872 XCP_vcbattRequest: 8 Vector__XXX
 SG_ XCP_vcbattRequestData : 0|64@1+ (1,0) [0|0] "" Vector__XXX

BO_ 1873 XCP_vcbatt1Request: 8 Vector__XXX
 SG_ XCP_vcbatt1RequestData : 0|64@1+ (1,0) [0|0] "" Vector__XXX

BO_ 1874 BMS_debugInfo_100Hz: 8 Vector__XXX
 SG_ BMS_100HzDebug_Id M : 0|6@1+ (1,0) [0|0] "" Vector__XXX
 SG_ BMS_dbgLoadReg_output m2 : 6|11@1- (0.1,0) [0|0] "" Vector__XXX
 SG_ BMS_dbgSmWeldRequest m3 : 6|1@1+ (1,0) [0|0] "" Vector__XXX
 SG_ BMS_energyVoltageFloorReached m4 : 6|1@1+ (1,0) [0|0] "" Vector__XXX
 SG_ BMS_dbgSmChgModuleBlockingTrans m3 : 7|1@1+ (1,0) [0|0] "" Vector__XXX
 SG_ BMS_energyPowerTargetReached m4 : 7|1@1+ (1,0) [0|0] "" Vector__XXX
 SG_ BMS_brickOcvAvg m9 : 8|12@1+ (0.002,0) [0|0] "" Vector__XXX
 SG_ BMS_dbgCurrentReg_outIntegral m1 : 8|14@1- (0.1,0) [0|0] "" Vector__XXX
 SG_ BMS_dbgHvsTxErrorCount m6 : 8|8@1+ (1,0) [0|0] "" Vector__XXX
 SG_ BMS_dbgSmChargeCablePresent m3 : 8|1@1+ (1,0) [0|0] "" Vector__XXX
 SG_ BMS_dbgVoltageReg_Kp m0 : 8|9@1+ (5,0) [0|0] "" Vector__XXX
 SG_ BMS_energySimulationWalk m11 : 8|3@1+ (1,0) [0|0] "" Vector__XXX
 SG_ BMS_energySimulationWalkTime m10 : 8|14@1+ (0.1,0) [0|0] "" Vector__XXX
 SG_ BMS_energyWalkDone m4 : 8|1@1+ (1,0) [0|0] "" Vector__XXX
 SG_ BMS_energyWalkLoadedPackV m5 : 8|9@1+ (1,0) [0|0] "" Vector__XXX
 SG_ BMS_maxDeviationBrickId m12 : 8|8@1+ (1,1) [0|0] "" Vector__XXX
 SG_ BMS_measuredImpedanceNoise m13 : 8|12@1+ (0.001,0) [0|0] "" Vector__XXX
 SG_ BMS_socByDvStartPtInitialized m7 : 8|1@1+ (1,0) [0|0] "" Vector__XXX
 SG_ BMS_voltageInstabilityPresent m8 : 8|1@1+ (1,0) [0|0] "" Vector__XXX
 SG_ BMS_dbgSmChargeRequestActive m3 : 9|1@1+ (1,0) [0|0] "" Vector__XXX
 SG_ BMS_energySocLimitReached m4 : 9|1@1+ (1,0) [0|0] "" Vector__XXX
 SG_ BMS_socByDvStartCcv m7 : 9|12@1+ (0.002,0) [0|0] "" Vector__XXX
 SG_ BMS_voltageInstabilityFiltMedianCnts m8 : 9|12@1+ (0.1,0) [0|0] "" Vector__XXX
 SG_ BMS_dbgSmChargerActive m3 : 10|1@1+ (1,0) [0|0] "" Vector__XXX
 SG_ BMS_energyNotEnoughPower m4 : 10|1@1+ (1,0) [0|0] "" Vector__XXX
 SG_ BMS_dbgSmBmsWantsToCharge m3 : 11|1@1+ (1,0) [0|0] "" Vector__XXX
 SG_ BMS_energyTargetReached m4 : 11|1@1+ (1,0) [0|0] "" Vector__XXX
 SG_ BMS_dbgChargeState m3 : 12|4@1+ (1,0) [0|0] "" Vector__XXX
 SG_ BMS_energyWalkTimedOut m4 : 12|1@1+ (1,0) [0|0] "" Vector__XXX
 SG_ BMS_energyWalkId m4 : 13|3@1+ (1,0) [0|0] "" Vector__XXX
 SG_ BMS_dbgChargeNeeded m3 : 16|1@1+ (1,0) [0|0] "" Vector__XXX
 SG_ BMS_dbgHvsRxErrorCount m6 : 16|8@1+ (1,0) [0|0] "" Vector__XXX
 SG_ BMS_energyWalkTime m4 : 16|10@1+ (0.01,0) [0|0] "" Vector__XXX
 SG_ BMS_maxDeviationBrickImpedance m12 : 16|12@1+ (0.01,0) [0|0] "" Vector__XXX
 SG_ BMS_dbgOffsetReg_output m2 : 17|14@1- (0.1,0) [0|0] "" Vector__XXX
 SG_ BMS_dbgSmStateSupportRequired m3 : 17|1@1+ (1,0) [0|0] "" Vector__XXX
 SG_ BMS_dbgVoltageReg_Ki m0 : 17|11@1+ (1,0) [0|0] "" Vector__XXX
 SG_ BMS_energyWalkPackCurrent m5 : 17|15@1- (0.1,1000) [0|0] "" Vector__XXX
 SG_ BMS_dbgSmDriveActive m3 : 18|1@1+ (1,0) [0|0] "" Vector__XXX
 SG_ BMS_dbgFeimBlocking m3 : 19|1@1+ (1,0) [0|0] "" Vector__XXX
 SG_ BMS_brickOcvMax m9 : 20|12@1+ (0.002,0) [0|0] "" Vector__XXX
 SG_ BMS_dbgUdsCtrControlActive m3 : 20|1@1+ (1,0) [0|0] "" Vector__XXX
 SG_ BMS_normalizedDcrNoise m13 : 20|10@1+ (0.001,0) [0|0] "" Vector__XXX
 SG_ BMS_dbgEnoughPowerForSupport m3 : 21|1@1+ (1,0) [0|0] "" Vector__XXX
 SG_ BMS_socByDvStartCurrent m7 : 21|10@1- (1,0) [0|0] "" Vector__XXX
 SG_ BMS_voltageDiffPerSMax m8 : 21|11@1+ (0.00244140625,-2.5) [0|0] "" Vector__XXX
 SG_ BMS_chargeEnergyPackCurrent m10 : 24|13@1- (1,1000) [0|0] "" Vector__XXX
 SG_ BMS_dbgCurrentReg_outProp m1 : 24|14@1- (0.1,0) [0|0] "" Vector__XXX
 SG_ BMS_dbgHvsFaultConfinement m6 : 24|2@1+ (1,0) [0|0] "" Vector__XXX
 SG_ BMS_fcLinkLeakageTestStatus m3 : 24|3@1+ (1,0) [0|0] "" Vector__XXX
 SG_ BMS_dbgHvsBusIsOff m6 : 26|1@1+ (1,0) [0|0] "" Vector__XXX
 SG_ BMS_walkEnergy m4 : 26|11@1+ (0.1,0) [0|0] "" Vector__XXX
 SG_ BMS_dbgHvsGoToSleep m6 : 27|1@1+ (1,0) [0|0] "" Vector__XXX
 SG_ BMS_minTetheredLoadPresent m3 : 27|1@1+ (1,0) [0|0] "" Vector__XXX
 SG_ BMS_avgBrickImpedance m12 : 28|12@1+ (0.01,0) [0|0] "" Vector__XXX
 SG_ BMS_dbgVoltageReg_error m0 : 28|12@1- (0.00122,0) [0|0] "" Vector__XXX
 SG_ BMS_smHvUpRequestAllowed m3 : 28|1@1+ (1,0) [0|0] "" Vector__XXX
 SG_ BMS_fcCtrCleaningDesired m3 : 29|1@1+ (1,0) [0|0] "" Vector__XXX
 SG_ BMS_fcCtrCleaningAllowed m3 : 30|1@1+ (1,0) [0|0] "" Vector__XXX
 SG_ BMS_rawImpedanceDeviation m13 : 30|10@1+ (0.001,0) [0|0] "" Vector__XXX
 SG_ BMS_fcCtrCleaningActive m3 : 31|1@1+ (1,0) [0|0] "" Vector__XXX
 SG_ BMS_socByDvNetAh m7 : 31|9@1+ (0.002,0) [0|0] "" Vector__XXX
 SG_ BMS_brickOcvMin m9 : 32|12@1+ (0.002,0) [0|0] "" Vector__XXX
 SG_ BMS_dbgChargeNeededState m2 : 32|3@1+ (1,0) [0|0] "" Vector__XXX
 SG_ BMS_dbgHviTxErrorCount m6 : 32|8@1+ (1,0) [0|0] "" Vector__XXX
 SG_ BMS_energyWalkPackResistance m5 : 32|10@1+ (0.1,0) [0|0] "" Vector__XXX
 SG_ BMS_fcCtrCleaningPosCount m3 : 32|6@1+ (1,0) [0|0] "" Vector__XXX
 SG_ BMS_voltageInstabilityFltExcessNoise m8 : 32|12@1+ (0.1,0) [0|0] "" Vector__XXX
 SG_ BMS_dbgMaxDcCurrentAvailable m2 : 35|11@1+ (0.5,0) [0|0] "" Vector__XXX
 SG_ BMS_energyMaxBrickTemp m10 : 37|9@1+ (0.25,-25) [0|0] "" Vector__XXX
 SG_ BMS_energyWalkAhRemaining m4 : 37|12@1+ (0.1,0) [0|0] "" Vector__XXX
 SG_ BMS_dbgCurrentReg_error m1 : 40|12@1- (0.1,0) [0|0] "" Vector__XXX
 SG_ BMS_dbgHviRxErrorCount m6 : 40|8@1+ (1,0) [0|0] "" Vector__XXX
 SG_ BMS_dbgPeakRegenCurrentLimitMode m7 : 40|4@1+ (1,0) [0|0] "" Vector__XXX
 SG_ BMS_dbgVoltageReg_output m0 : 40|12@1- (0.5,0) [0|0] "" Vector__XXX
 SG_ BMS_fcCtrCleaningNegCount m3 : 40|6@1+ (1,0) [0|0] "" Vector__XXX
 SG_ BMS_missingCellExcessCurrentGain m13 : 40|8@1+ (0.05,0) [0|0] "" Vector__XXX
 SG_ BMS_snapshot1MaxVoltage m12 : 40|10@1+ (0.005,0) [0|0] "" Vector__XXX
 SG_ BMS_brickOcvSum m9 : 44|10@1+ (0.5,0) [0|0] "" Vector__XXX
 SG_ BMS_dbgDischargeCurrentLimitMode m7 : 44|4@1+ (1,0) [0|0] "" Vector__XXX
 SG_ BMS_voltageInstabilityMaxRawCnts m8 : 44|12@1+ (1,0) [0|0] "" Vector__XXX
 SG_ BMS_brickVoltagesClean m3 : 46|1@1+ (1,0) [0|0] "" Vector__XXX
 SG_ BMS_dbgCurrentReg_targetI m2 : 46|11@1+ (0.5,0) [0|0] "" Vector__XXX
 SG_ BMS_energyMinBrickTemp m10 : 46|9@1+ (0.25,-25) [0|0] "" Vector__XXX
 SG_ BMS_chargeSourcePresent m3 : 47|1@1+ (1,0) [0|0] "" Vector__XXX
 SG_ BMS_dbgHviFaultConfinement m6 : 48|2@1+ (1,0) [0|0] "" Vector__XXX
 SG_ BMS_energyWalkPackTemp m5 : 48|8@1- (1,40) [0|0] "" Vector__XXX
 SG_ BMS_missingCellImpedanceDeviation m13 : 48|10@1+ (0.001,0) [0|0] "" Vector__XXX
 SG_ BMS_energyWalkPackSoc m4 : 49|10@1+ (0.1,0) [0|0] "" Vector__XXX
 SG_ BMS_dbgHviBusIsOff m6 : 50|1@1+ (1,0) [0|0] "" Vector__XXX
 SG_ BMS_impedanceDevDeltaCurrent m12 : 50|12@1+ (1,-3000) [0|0] "" Vector__XXX
 SG_ BMS_instantPowerDissipation m9 : 54|10@1+ (0.25,0) [0|0] "" Vector__XXX
 SG_ BMS_energyCoolantOutletTemp m10 : 56|8@1+ (1,-50) [0|0] "" Vector__XXX
 SG_ BMS_voltageInstabilityMaxBrickVNumber m8 : 56|7@1+ (1,0) [0|0] "" Vector__XXX
 SG_ BMS_dbgCpUserChargeStatus m2 : 57|3@1+ (1,0) [0|0] "" Vector__XXX
 SG_ BMS_energyCounter m4 : 59|4@1+ (1,0) [0|0] "" Vector__XXX

BO_ 1875 XCP_vcrightRequest: 12 Vector__XXX
 SG_ XCP_vcrightRequestData : 7|64@0+ (1,0) [0|0] "" Vector__XXX

BO_ 1876 XCP_vcfrontRequest: 12 Vector__XXX
 SG_ XCP_vcfrontRequestData : 7|64@0+ (1,0) [0|0] "" Vector__XXX

BO_ 1877 XCP_vcsecRequest: 12 Vector__XXX
 SG_ XCP_vcsecRequestData : 7|64@0+ (1,0) [0|0] "" Vector__XXX

BO_ 1878 XCP_vcleftRequest: 12 Vector__XXX
 SG_ XCP_vcleftRequestData : 7|64@0+ (1,0) [0|0] "" Vector__XXX

BO_ 1879 DIF_debug: 8 Vector__XXX
 SG_ DIF_debugSelector M : 0|8@1+ (1,0) [0|0] "" Vector__XXX
 SG_ DIF_cpu10HzMin m66 : 8|8@1+ (0.4,0) [0|0] "" Vector__XXX
 SG_ DIF_cpu1HzMin m128 : 8|8@1+ (0.4,0) [0|0] "" Vector__XXX
 SG_ DIF_cpu1kHzMin m67 : 8|8@1+ (0.4,0) [0|0] "" Vector__XXX
 SG_ DIF_dcCapTemp m64 : 8|8@1+ (1,-40) [0|0] "" Vector__XXX
 SG_ DIF_gainScale m37 : 8|8@1+ (0.01,0) [0|0] "" Vector__XXX
 SG_ DIF_hwFaultCount m69 : 8|4@1+ (1,0) [0|0] "" Vector__XXX
 SG_ DIF_latchFeedback m50 : 8|1@1+ (1,0) [0|0] "" Vector__XXX
 SG_ DIF_lmScale m36 : 8|8@1+ (0.004,0) [0|0] "" Vector__XXX
 SG_ DIF_motorIA m32 : 8|16@1+ (0.1,0) [0|0] "" Vector__XXX
 SG_ DIF_offsetA m44 : 8|6@1- (0.763,0) [0|0] "" Vector__XXX
 SG_ DIF_oilPumpMotorSpeed m46 : 8|8@1+ (40,0) [0|0] "" Vector__XXX
 SG_ DIF_phaseOutBusbarTemp m70 : 8|8@1+ (1,-40) [0|0] "" Vector__XXX
 SG_ DIF_resolverOffsetCos m48 : 8|8@1+ (0.015,0) [0|0] "" Vector__XXX
 SG_ DIF_rotorOffsetEst m43 : 8|12@1- (0.01,0) [0|0] "" Vector__XXX
 SG_ DIF_rsScale m34 : 8|8@1+ (0.01,0) [0|0] "" Vector__XXX
 SG_ DIF_soptTimeToTrip m49 : 8|8@1+ (0.05,0) [0|0] "" Vector__XXX
 SG_ DIF_statorEndWindingTemp m72 : 8|8@1+ (1,-40) [0|0] "" Vector__XXX
 SG_ DIF_statorIDref m33 : 8|16@1- (0.1,0) [0|0] "" Vector__XXX
 SG_ DIF_systemStack m68 : 8|8@1+ (0.4,0) [0|0] "" Vector__XXX
 SG_ DIF_tqSatThermal m39 : 8|8@1+ (0.4,0) [0|0] "" Vector__XXX
 SG_ DIF_tqScaleDifferential m35 : 8|8@1+ (0.4,0) [0|0] "" Vector__XXX
 SG_ DIF_mechssLatchesActive m50 : 9|1@1+ (1,0) [0|0] "" Vector__XXX
 SG_ DIF_usmState m38 : 12|3@1+ (1,0) [0|0] "" Vector__XXX
 SG_ DIF_busbarTemp m64 : 16|8@1+ (1,-40) [0|0] "" Vector__XXX
 SG_ DIF_cpu10HzAvg m66 : 16|8@1+ (0.4,0) [0|0] "" Vector__XXX
 SG_ DIF_cpu1HzAvg m128 : 16|8@1+ (0.4,0) [0|0] "" Vector__XXX
 SG_ DIF_cpu1kHzAvg m67 : 16|8@1+ (0.4,0) [0|0] "" Vector__XXX
 SG_ DIF_cpuIDWord0 m131 : 16|16@1+ (1,0) [0|0] "" Vector__XXX
 SG_ DIF_cpuIDWord1 m132 : 16|16@1+ (1,0) [0|0] "" Vector__XXX
 SG_ DIF_idleStack m68 : 16|8@1+ (0.4,0) [0|0] "" Vector__XXX
 SG_ DIF_lvBoostedRail m50 : 16|8@1+ (0.08,0) [0|0] "" Vector__XXX
 SG_ DIF_offsetB m44 : 16|6@1- (0.763,0) [0|0] "" Vector__XXX
 SG_ DIF_oilPumpPhaseVoltage m46 : 16|8@1+ (0.3,0) [0|0] "" Vector__XXX
 SG_ DIF_peakIQref m38 : 16|16@1+ (0.1,0) [0|0] "" Vector__XXX
 SG_ DIF_phaseOutBusbarWeldTemp m70 : 16|8@1+ (1,-40) [0|0] "" Vector__XXX
 SG_ DIF_resolverCosRmsSquared m52 : 16|8@1+ (0.005,0) [0|0] "" Vector__XXX
 SG_ DIF_resolverOffsetSin m48 : 16|8@1+ (0.015,0) [0|0] "" Vector__XXX
 SG_ DIF_rotorFlux m47 : 16|16@1+ (0.0001,0) [0|0] "" Vector__XXX
 SG_ DIF_rotorMaxMagnetTemp m72 : 16|8@1+ (1,-40) [0|0] "" Vector__XXX
 SG_ DIF_soptTripDelay m49 : 16|8@1+ (0.05,0) [0|0] "" Vector__XXX
 SG_ DIF_statorFluxRef m35 : 16|16@1+ (0.0001,0) [0|0] "" Vector__XXX
 SG_ DIF_statorIQref m34 : 16|16@1- (0.1,0) [0|0] "" Vector__XXX
 SG_ DIF_statorVDFiltered m63 : 16|16@1- (4e-05,0) [0|0] "" Vector__XXX
 SG_ DIF_statorVQ m36 : 16|16@1- (4e-05,0) [0|0] "" Vector__XXX
 SG_ DIF_tcMaxRequest m40 : 16|8@1+ (5,0) [0|0] "" Vector__XXX
 SG_ DIF_rotorOffsetMean m43 : 20|12@1- (0.01,0) [0|0] "" Vector__XXX
 SG_ DIF_activeDischargeRail m50 : 24|8@1+ (0.3,0) [0|0] "" Vector__XXX
 SG_ DIF_cpu100HzMin m66 : 24|8@1+ (0.4,0) [0|0] "" Vector__XXX
 SG_ DIF_cpu20kHzMin m67 : 24|8@1+ (0.4,0) [0|0] "" Vector__XXX
 SG_ DIF_decodeHardwareStack m68 : 24|8@1+ (0.4,0) [0|0] "" Vector__XXX
 SG_ DIF_lightSenseV m72 : 24|6@1+ (0.1,0) [0|0] "" Vector__XXX
 SG_ DIF_llsScale m42 : 24|8@1+ (0.004,0) [0|0] "" Vector__XXX
 SG_ DIF_motorIB m32 : 24|16@1+ (0.1,0) [0|0] "" Vector__XXX
 SG_ DIF_oilPumpPressureEstimateMax m46 : 24|8@1+ (2,0) [0|0] "" Vector__XXX
 SG_ DIF_pcsTemp m64 : 24|8@1+ (1,-40) [0|0] "" Vector__XXX
 SG_ DIF_phaseOutLugTemp m70 : 24|8@1+ (1,-40) [0|0] "" Vector__XXX
 SG_ DIF_resolverPhaseOffset m48 : 24|8@1+ (0.4,0) [0|0] "" Vector__XXX
 SG_ DIF_resolverSinRmsSquared m52 : 24|8@1+ (0.005,0) [0|0] "" Vector__XXX
 SG_ DIF_soptTimeToOff m49 : 24|11@1+ (0.05,0) [0|0] "" Vector__XXX
 SG_ DIF_statorIDfdb m33 : 24|16@1- (0.1,0) [0|0] "" Vector__XXX
 SG_ DIF_tcMinRequest m40 : 24|8@1+ (5,0) [0|0] "" Vector__XXX
 SG_ DIF_pyroSenseV m72 : 30|8@1+ (0.02,0) [0|0] "" Vector__XXX
 SG_ DIF_cpu100HzAvg m66 : 32|8@1+ (0.4,0) [0|0] "" Vector__XXX
 SG_ DIF_cpu20kHzAvg m67 : 32|8@1+ (0.4,0) [0|0] "" Vector__XXX
 SG_ DIF_cpuIDWord2 m132 : 32|16@1+ (1,0) [0|0] "" Vector__XXX
 SG_ DIF_crc m131 : 32|32@1+ (1,0) [0|0] "" Vector__XXX
 SG_ DIF_dcCableHeat m47 : 32|16@1+ (0.001,0) [0|0] "" Vector__XXX
 SG_ DIF_dcLinkCapTemp m70 : 32|8@1+ (1,-40) [0|0] "" Vector__XXX
 SG_ DIF_driveUnitOdometer m69 : 32|32@1+ (10,0) [0|0] "" Vector__XXX
 SG_ DIF_eepromStack m68 : 32|8@1+ (0.4,0) [0|0] "" Vector__XXX
 SG_ DIF_llrScale m42 : 32|8@1+ (0.015,0) [0|0] "" Vector__XXX
 SG_ DIF_loadAngleMargin m37 : 32|16@1- (0.0003,0) [0|0] "" Vector__XXX
 SG_ DIF_motorIAavg m38 : 32|16@1- (0.1,0) [0|0] "" Vector__XXX
 SG_ DIF_oilPumpPressureExpectedMin m46 : 32|8@1+ (2,0) [0|0] "" Vector__XXX
 SG_ DIF_preregulatorRail m50 : 32|8@1+ (0.15,0) [0|0] "" Vector__XXX
 SG_ DIF_resolverCommonGain m48 : 32|8@1+ (0.025,0) [0|0] "" Vector__XXX
 SG_ DIF_resolverCosFiltered m52 : 32|8@1- (0.01,0) [0|0] "" Vector__XXX
 SG_ DIF_statorFluxFdb m35 : 32|16@1+ (0.0001,0) [0|0] "" Vector__XXX
 SG_ DIF_statorIQfdb m34 : 32|16@1- (0.1,0) [0|0] "" Vector__XXX
 SG_ DIF_statorTemp1 m64 : 32|8@1+ (1,-40) [0|0] "" Vector__XXX
 SG_ DIF_statorVD m36 : 32|16@1- (4e-05,0) [0|0] "" Vector__XXX
 SG_ DIF_statorVQFiltered m63 : 32|16@1- (4e-05,0) [0|0] "" Vector__XXX
 SG_ DIF_tqSatMotorVoltage m39 : 32|8@1+ (0.4,0) [0|0] "" Vector__XXX
 SG_ DIF_wasteCurrentLimit m41 : 32|16@1+ (0.1,0) [0|0] "" Vector__XXX
 SG_ DIF_controlStack m67 : 40|8@1+ (0.4,0) [0|0] "" Vector__XXX
 SG_ DIF_cpu10msMin m66 : 40|8@1+ (0.4,0) [0|0] "" Vector__XXX
 SG_ DIF_hvDcCableTemp m70 : 40|8@1+ (1,-40) [0|0] "" Vector__XXX
 SG_ DIF_loadAngle m42 : 40|16@1- (0.0003,0) [0|0] "" Vector__XXX
 SG_ DIF_motorIC m32 : 40|16@1+ (0.1,0) [0|0] "" Vector__XXX
 SG_ DIF_resolverReady m48 : 40|1@1+ (1,0) [0|0] "" Vector__XXX
 SG_ DIF_resolverSinFiltered m52 : 40|8@1- (0.01,0) [0|0] "" Vector__XXX
 SG_ DIF_soptMaxCurrentMagSqrd m49 : 40|16@1+ (100,0) [0|0] "" Vector__XXX
 SG_ DIF_statorTemp2 m64 : 40|8@1+ (1,-40) [0|0] "" Vector__XXX
 SG_ DIF_torquePerAmp m33 : 40|16@1+ (0.0001,0) [0|0] "" Vector__XXX
 SG_ DIF_tqSatMotorCurrent m39 : 40|8@1+ (0.4,0) [0|0] "" Vector__XXX
 SG_ DIF_udsStack m68 : 40|8@1+ (0.4,0) [0|0] "" Vector__XXX
 SG_ DIF_resolverNoCarrier m48 : 41|1@1+ (1,0) [0|0] "" Vector__XXX
 SG_ DIF_resolverNoPhaseLock m48 : 42|1@1+ (1,0) [0|0] "" Vector__XXX
 SG_ DIF_resolverClaMIA m48 : 43|1@1+ (1,0) [0|0] "" Vector__XXX
 SG_ DIF_statorSlotWindingTemp m72 : 46|8@1+ (1,-40) [0|0] "" Vector__XXX
 SG_ DIF_cpuIDWord3 m132 : 48|16@1+ (1,0) [0|0] "" Vector__XXX
 SG_ DIF_internalAngleFilt m37 : 48|16@1+ (0.0003,0) [0|0] "" Vector__XXX
 SG_ DIF_magnetTempEst m47 : 48|8@1+ (1,-40) [0|0] "" Vector__XXX
 SG_ DIF_module10HzStack m66 : 48|8@1+ (0.4,0) [0|0] "" Vector__XXX
 SG_ DIF_motorIBavg m38 : 48|16@1- (0.1,0) [0|0] "" Vector__XXX
 SG_ DIF_motorV m34 : 48|16@1+ (2e-05,0) [0|0] "" Vector__XXX
 SG_ DIF_negDcBusbarTemp m70 : 48|8@1+ (1,-40) [0|0] "" Vector__XXX
 SG_ DIF_peakFlux m36 : 48|16@1+ (0.0001,0) [0|0] "" Vector__XXX
 SG_ DIF_phaseImbalanceFactor m35 : 48|16@1+ (0.0001,0) [0|0] "" Vector__XXX
 SG_ DIF_pwmState m63 : 48|2@1+ (1,0) [0|0] "" Vector__XXX
 SG_ DIF_resolverErrorRmsSquared m52 : 48|8@1+ (0.005,0) [0|0] "" Vector__XXX
 SG_ DIF_tqScaleMaxMotorSpeed m40 : 48|8@1+ (0.4,0) [0|0] "" Vector__XXX
 SG_ DIF_xcpStack m68 : 48|8@1+ (0.4,0) [0|0] "" Vector__XXX
 SG_ DIF_intervalMaxHvBusV m72 : 54|10@1+ (1,0) [0|0] "" Vector__XXX
 SG_ DIF_immobilizerStack m68 : 56|8@1+ (0.4,0) [0|0] "" Vector__XXX
 SG_ DIF_posDcBusbarTemp m70 : 56|8@1+ (1,-40) [0|0] "" Vector__XXX

BO_ 1881 XCP_vcfront1Request: 8 Vector__XXX
 SG_ XCP_vcfront1RequestData : 0|64@1+ (1,0) [0|0] "" Vector__XXX

BO_ 1882 XCP_vcfront2Request: 8 Vector__XXX
 SG_ XCP_vcfront2RequestData : 0|64@1+ (1,0) [0|0] "" Vector__XXX

BO_ 1883 XCP_vcbatt2Request: 8 Vector__XXX
 SG_ XCP_vcbatt2RequestData : 0|64@1+ (1,0) [0|0] "" Vector__XXX

BO_ 1885 CP_loggingFast: 8 Vector__XXX
 SG_ CP_loggingFastSelect M : 0|4@1+ (1,0) [0|0] "" Vector__XXX
 SG_ CP_UHF_controlState m2 : 4|4@1+ (1,0) [0|0] "" Vector__XXX
 SG_ CP_doorPresenceSensorV m3 : 4|12@1+ (0.001221,0) [0|0] "" Vector__XXX
 SG_ CP_inductiveSensor_raw m0 : 4|28@1+ (1,0) [0|0] "" Vector__XXX
 SG_ CP_latchLastEngageRequestMaxV m4 : 4|10@1+ (0.017595307917888565,0) [0|0] "" Vector__XXX
 SG_ CP_latchPot m1 : 4|12@1+ (0.025,0) [0|0] "" Vector__XXX
 SG_ CP_v2xState m5 : 4|3@1+ (1,0) [0|0] "" Vector__XXX
 SG_ CP_proximityV m2 : 8|16@1+ (0.0001,0) [0|0] "" Vector__XXX
 SG_ CP_v2xCommsState m5 : 8|3@1+ (1,0) [0|0] "" Vector__XXX
 SG_ CP_v2xRetryAttempts m5 : 11|4@1+ (1,0) [0|0] "" Vector__XXX
 SG_ CP_latchLastEngageRequestMaxI m4 : 14|10@1+ (0.004887585532746823,0) [0|0] "" Vector__XXX
 SG_ CP_activeV2xBlocker m5 : 16|5@1+ (1,0) [0|0] "" Vector__XXX
 SG_ CP_doorLastRequestMaxI m1 : 16|12@1+ (0.0025,0) [0|0] "" Vector__XXX
 SG_ CP_doorOpenRequest m3 : 16|4@1+ (1,0) [0|0] "" Vector__XXX
 SG_ CP_doorOpenEndOfDriveReason m3 : 20|3@1+ (1,0) [0|0] "" Vector__XXX
 SG_ CP_lastV2xShutdownTrigger m5 : 21|5@1+ (1,0) [0|0] "" Vector__XXX
 SG_ CP_coverClosed m3 : 23|1@1+ (1,0) [0|0] "" Vector__XXX
 SG_ CP_doorCloseEndOfDriveReason m3 : 24|3@1+ (1,0) [0|0] "" Vector__XXX
 SG_ CP_latchLastDisengageRequestMaxV m4 : 24|10@1+ (0.017595307917888565,0) [0|0] "" Vector__XXX
 SG_ CP_proximityV_GBCC1 m2 : 24|14@1+ (0.001,0) [0|0] "" Vector__XXX
 SG_ CP_doorCloseRequest m3 : 27|5@1+ (1,0) [0|0] "" Vector__XXX
 SG_ CP_doorLastRequestMaxV m1 : 28|10@1+ (0.017595307917888565,0) [0|0] "" Vector__XXX
 SG_ CP_doorOpenActuationTime m0 : 32|14@1+ (1,0) [0|0] "" Vector__XXX
 SG_ CP_latchDisengagingTime m3 : 32|10@1+ (1,0) [0|0] "" Vector__XXX
 SG_ CP_latchLastDisengageRequestMaxI m4 : 34|10@1+ (0.004887585532746823,0) [0|0] "" Vector__XXX
 SG_ CP_digitalCommsAttempts m5 : 37|3@1+ (1,0) [0|0] "" Vector__XXX
 SG_ CP_pilotPulseWidth m1 : 38|12@1+ (1,0) [0|0] "" Vector__XXX
 SG_ CP_proximityV_GBCC2 m2 : 38|14@1+ (0.001,0) [0|0] "" Vector__XXX
 SG_ CP_evseGridFormRequestVersion m5 : 40|2@1+ (1,0) [0|0] "" Vector__XXX
 SG_ CP_evseGridFormState m5 : 42|3@1+ (1,0) [0|0] "" Vector__XXX
 SG_ CP_latchEngagingTime m3 : 42|10@1+ (1,0) [0|0] "" Vector__XXX
 SG_ CP_latchLastEngageMaxVelocity m4 : 44|10@1- (8.013698630136986,0) [0|0] "" Vector__XXX
 SG_ CP_evsePilotPowerNeeded m5 : 45|1@1+ (1,0) [0|0] "" Vector__XXX
 SG_ CP_doorCloseActuationTime m0 : 46|14@1+ (1,0) [0|0] "" Vector__XXX
 SG_ CP_v2xAccessoryUpdateWithoutExternalPower m5 : 46|1@1+ (1,0) [0|0] "" Vector__XXX
 SG_ CP_doorPotObserverEstimated m5 : 47|12@1+ (0.025,0) [0|0] "" Vector__XXX
 SG_ CP_pilotPeriod m1 : 50|12@1+ (1,0) [0|0] "" Vector__XXX
 SG_ CP_doorPot m2 : 52|12@1+ (0.025,0) [0|0] "" Vector__XXX
 SG_ CP_latchDisengagingStopReason m3 : 52|3@1+ (1,0) [0|0] "" Vector__XXX
 SG_ CP_latchLastDisengageMaxVelocity m4 : 54|10@1- (8.013698630136986,0) [0|0] "" Vector__XXX
 SG_ CP_latchEngagingStopReason m3 : 55|3@1+ (1,0) [0|0] "" Vector__XXX
 SG_ CP_pilotUnlatchRequestActive m3 : 58|1@1+ (1,0) [0|0] "" Vector__XXX
 SG_ CP_doorIdDetectionState m3 : 59|2@1+ (1,0) [0|0] "" Vector__XXX
 SG_ CP_doorObserverEstimationIsActive m5 : 59|1@1+ (1,0) [0|0] "" Vector__XXX
 SG_ CP_chargeCableSecured m0 : 60|1@1+ (1,0) [0|0] "" Vector__XXX
 SG_ CP_doorPositionSource m5 : 60|2@1+ (1,0) [0|0] "" Vector__XXX
 SG_ CP_chargeCablePresent m0 : 61|1@1+ (1,0) [0|0] "" Vector__XXX
 SG_ CP_doorIdDetectedBin m3 : 61|2@1+ (1,0) [0|0] "" Vector__XXX
 SG_ CP_latchCheckAvailable m0 : 62|1@1+ (1,0) [0|0] "" Vector__XXX
 SG_ CP_proxConn1Sense m1 : 62|1@1+ (1,0) [0|0] "" Vector__XXX
 SG_ CP_proxEn m1 : 63|1@1+ (1,0) [0|0] "" Vector__XXX
 SG_ CP_semiV2LatchNonLinear m3 : 63|1@1+ (1,0) [0|0] "" Vector__XXX

BO_ 1886 CHADA_status_2: 8 Vector__XXX
 SG_ CA_status2DataSelect M : 0|7@1+ (1,0) [0|0] "" Vector__XXX
 SG_ CA_status2DummySig : 7|1@1+ (1,0) [0|0] "" Vector__XXX
 SG_ CA_EVSE_Ext_Avail_I_Out m4 : 8|16@1+ (1,0) [0|0] "" Vector__XXX
 SG_ CA_EVSE_Threshold_V m1 : 8|16@1+ (1,0) [0|0] "" Vector__XXX
 SG_ CA_VEH_Ext_Protocol_Ver m0 : 8|8@1+ (1,0) [0|0] "" Vector__XXX
 SG_ CA_vehConnTempDegC m2 : 8|16@1- (0.00457770657,0) [0|0] "" Vector__XXX
 SG_ CA_vehConnTempV m3 : 8|16@1+ (5.035477e-05,0) [0|0] "" Vector__XXX
 SG_ CA_EVSE_Ext_Protocol_Ver m0 : 16|8@1+ (1,0) [0|0] "" Vector__XXX
 SG_ CA_EVSE_Avail_V_Out m1 : 24|16@1+ (1,0) [0|0] "" Vector__XXX
 SG_ CA_EVSE_Eff_Avail_I_Out m4 : 24|16@1+ (1,0) [0|0] "" Vector__XXX
 SG_ CA_FC_protocolVersion m0 : 24|8@1+ (1,0) [0|0] "" Vector__XXX
 SG_ CA_evseConnTempDegC m2 : 24|16@1- (0.00457770657,0) [0|0] "" Vector__XXX
 SG_ CA_evseConnTempV m3 : 24|16@1+ (5.035477e-05,0) [0|0] "" Vector__XXX
 SG_ CA_BMS_protocolVersion m0 : 32|8@1+ (1,0) [0|0] "" Vector__XXX
 SG_ CA_EVSE_Avail_I_Out m1 : 40|8@1+ (1,0) [0|0] "" Vector__XXX
 SG_ CA_VEH_BAT_V_Target m0 : 40|16@1+ (1,0) [0|0] "" Vector__XXX
 SG_ CA_pcbaTempDegC m2 : 40|16@1- (0.01007110813,25) [0|0] "" Vector__XXX
 SG_ CA_pcbaTempV m3 : 40|16@1+ (5.035477e-05,0) [0|0] "" Vector__XXX
 SG_ CA_flybackVoltageLimit m1 : 48|16@1+ (0.01283327338,0) [0|0] "" Vector__XXX
 SG_ CA_VEH_BAT_SOC m0 : 56|8@1+ (0.39215686275,0) [0|0] "" Vector__XXX
 SG_ CA_disableVehicleLimiting m2 : 56|1@1+ (1,0) [0|0] "" Vector__XXX

BO_ 1889 PMF_debug: 8 Vector__XXX
 SG_ PMF_debugSelector M : 0|8@1+ (1,0) [0|0] "" Vector__XXX
 SG_ PMF_Ia m3 : 8|16@1- (0.0939,0) [0|0] "" Vector__XXX
 SG_ PMF_cpu100HzAvg m65 : 8|8@1+ (0.4,0) [0|0] "" Vector__XXX
 SG_ PMF_cpu10kHzMin m66 : 8|8@1+ (0.4,0) [0|0] "" Vector__XXX
 SG_ PMF_cpu1kHzMax m64 : 8|8@1+ (0.4,0) [0|0] "" Vector__XXX
 SG_ PMF_idleStackSize m67 : 8|16@1+ (1,0) [0|0] "" Vector__XXX
 SG_ PMF_offsetIa m5 : 8|12@1- (0.1,0) [0|0] "" Vector__XXX
 SG_ PMF_resolverPhaseAngle m17 : 8|9@1+ (0.001537,0) [0|0] "" Vector__XXX
 SG_ PMF_resolverSpeedError m16 : 8|16@1- (0.75,0) [0|0] "" Vector__XXX
 SG_ PMF_slipFrequency m4 : 8|16@1- (0.005,0) [0|0] "" Vector__XXX
 SG_ PMF_sysStackSize m70 : 8|16@1+ (1,0) [0|0] "" Vector__XXX
 SG_ PMF_torqueDecelWindow m2 : 8|13@1- (2,0) [0|0] "" Vector__XXX
 SG_ PMF_torqueSignError m1 : 8|13@1- (2,0) [0|0] "" Vector__XXX
 SG_ PMF_udsStackSize m68 : 8|16@1+ (1,0) [0|0] "" Vector__XXX
 SG_ PMF_xcpStackSize m69 : 8|16@1+ (1,0) [0|0] "" Vector__XXX
 SG_ PMF_cpu10HzMax m65 : 16|8@1+ (0.4,0) [0|0] "" Vector__XXX
 SG_ PMF_cpu20kHzAvg m64 : 16|8@1+ (0.4,0) [0|0] "" Vector__XXX
 SG_ PMF_resolverCommonGain m17 : 17|7@1+ (0.063,0) [0|0] "" Vector__XXX
 SG_ PMF_offsetIb m5 : 20|12@1- (0.1,0) [0|0] "" Vector__XXX
 SG_ PMF_Ib m3 : 24|16@1- (0.0939,0) [0|0] "" Vector__XXX
 SG_ PMF_cpu10HzAvg m65 : 24|8@1+ (0.4,0) [0|0] "" Vector__XXX
 SG_ PMF_cpu1kHzMin m64 : 24|8@1+ (0.4,0) [0|0] "" Vector__XXX
 SG_ PMF_idleStackMax m67 : 24|16@1+ (1,0) [0|0] "" Vector__XXX
 SG_ PMF_resolverExcitationGain m17 : 24|7@1+ (0.063,0) [0|0] "" Vector__XXX
 SG_ PMF_sysStackMax m70 : 24|16@1+ (1,0) [0|0] "" Vector__XXX
 SG_ PMF_torqueAccelWindow m1 : 24|13@1- (2,0) [0|0] "" Vector__XXX
 SG_ PMF_torqueDecelAvg m2 : 24|13@1- (2,0) [0|0] "" Vector__XXX
 SG_ PMF_udsStackMax m68 : 24|16@1+ (1,0) [0|0] "" Vector__XXX
 SG_ PMF_xcpStackMax m69 : 24|16@1+ (1,0) [0|0] "" Vector__XXX
 SG_ PMF_cpu10HzMin m65 : 32|8@1+ (0.4,0) [0|0] "" Vector__XXX
 SG_ PMF_cpu10kHzAvg m64 : 32|8@1+ (0.4,0) [0|0] "" Vector__XXX
 SG_ PMF_resolverOffsetCos m17 : 32|6@1+ (0.053,0) [0|0] "" Vector__XXX
 SG_ PMF_cpu100HzMax m64 : 40|8@1+ (0.4,0) [0|0] "" Vector__XXX
 SG_ PMF_cpu20kHzMax m65 : 40|8@1+ (0.4,0) [0|0] "" Vector__XXX
 SG_ PMF_iDQmagnitude m3 : 40|16@1- (0.0939,0) [0|0] "" Vector__XXX
 SG_ PMF_motorRPM m4 : 40|16@1- (1,0) [0|0] "" Vector__XXX
 SG_ PMF_resolverOffsetSin m17 : 40|6@1+ (0.053,0) [0|0] "" Vector__XXX
 SG_ PMF_torqueAccelAvg m1 : 40|13@1- (2,0) [0|0] "" Vector__XXX
 SG_ PMF_torqueReversalWindow m2 : 40|13@1- (2,0) [0|0] "" Vector__XXX
 SG_ PMF_switchingActive m5 : 46|1@1+ (1,0) [0|0] "" Vector__XXX
 SG_ PMF_torqueOutOfMap m5 : 47|1@1+ (1,0) [0|0] "" Vector__XXX
 SG_ PMF_cpu1kHzAvg m64 : 48|8@1+ (0.4,0) [0|0] "" Vector__XXX
 SG_ PMF_cpu20kHzMin m65 : 48|8@1+ (0.4,0) [0|0] "" Vector__XXX
 SG_ PMF_resolverOffsetExt m17 : 48|6@1+ (0.053,0) [0|0] "" Vector__XXX
 SG_ PMF_resolverNoCarrier m17 : 54|1@1+ (1,0) [0|0] "" Vector__XXX
 SG_ PMF_resolverPhaseOutOfSpec m17 : 55|1@1+ (1,0) [0|0] "" Vector__XXX
 SG_ PMF_cpu100HzMin m64 : 56|8@1+ (0.4,0) [0|0] "" Vector__XXX
 SG_ PMF_cpu10kHzMax m65 : 56|8@1+ (0.4,0) [0|0] "" Vector__XXX
 SG_ PMF_lmSatCoeff m3 : 56|8@1+ (0.00391,0) [0|0] "" Vector__XXX
 SG_ PMF_resolverClaMIA m17 : 56|1@1+ (1,0) [0|0] "" Vector__XXX
 SG_ PMF_statorT m4 : 56|8@1+ (1,-40) [0|0] "" Vector__XXX
 SG_ PMF_resolverDiMIA m17 : 57|1@1+ (1,0) [0|0] "" Vector__XXX

BO_ 1890 VCLEFT_xcpResponse: 8 Vector__XXX
 SG_ VCLEFT_xcpResponseData : 0|64@1+ (1,0) [0|0] "" Vector__XXX

BO_ 1891 VCRIGHT_xcpResponse: 8 Vector__XXX
 SG_ VCRIGHT_xcpResponseData : 0|64@1+ (1,0) [0|0] "" Vector__XXX

BO_ 1892 VCFRONT_xcpResponse: 8 Vector__XXX
 SG_ VCFRONT_xcpResponseData : 0|64@1+ (1,0) [0|0] "" Vector__XXX

BO_ 1894 DIF_dlogData: 8 Vector__XXX
 SG_ DIF_dlogData : 0|64@1+ (1,0) [0|0] "" Vector__XXX

BO_ 1896 VCBATT_xcpResponse: 8 Vector__XXX
 SG_ VCBATT_xcpResponseData : 0|64@1+ (1,0) [0|0] "" Vector__XXX

BO_ 1897 VCBATT1_xcpResponse: 8 Vector__XXX
 SG_ VCBATT1_xcpResponseData : 0|64@1+ (1,0) [0|0] "" Vector__XXX

BO_ 1898 VCFRONT1_xcpResponse: 8 Vector__XXX
 SG_ VCFRONT1_xcpResponseData : 0|64@1+ (1,0) [0|0] "" Vector__XXX

BO_ 1899 VCFRONT2_xcpResponse: 8 Vector__XXX
 SG_ VCFRONT2_xcpResponseData : 0|64@1+ (1,0) [0|0] "" Vector__XXX

BO_ 1904 VCBATT2_xcpResponse: 8 Vector__XXX
 SG_ VCBATT2_xcpResponseData : 0|64@1+ (1,0) [0|0] "" Vector__XXX

BO_ 1910 XCP_difRequest: 12 Vector__XXX
 SG_ XCP_difRequestData : 7|64@0+ (1,0) [0|0] "" Vector__XXX

BO_ 1911 XCP_diRequest: 12 Vector__XXX
 SG_ XCP_diRequestData : 7|64@0+ (1,0) [0|0] "" Vector__XXX

BO_ 1914 HVP_log1hz: 8 Vector__XXX
 SG_ HVP_log1HzIndex M : 0|3@1+ (1,0) [0|0] "" Vector__XXX
 SG_ HVP_bmbAsicType m0 : 3|2@1+ (1,0) [0|0] "" Vector__XXX
 SG_ HVP_hvilCalType m1 : 3|2@1+ (1,0) [0|0] "" Vector__XXX
 SG_ HVP_gpioPcsDcdcPwmEnable m1 : 5|1@1+ (1,0) [0|0] "" Vector__XXX
 SG_ HVP_gpioPcsChargePwmEnable m1 : 6|1@1+ (1,0) [0|0] "" Vector__XXX
 SG_ HVP_gpioPcsEnable m1 : 7|1@1+ (1,0) [0|0] "" Vector__XXX
 SG_ HVP_shuntAsicChipWaferNumber m1 : 8|8@1+ (1,0) [0|0] "" Vector__XXX
 SG_ HVP_shuntCurrentAuxLog m0 : 8|24@1- (0.001,0) [0|0] "" Vector__XXX
 SG_ HVP_energyReserveMin m1 : 16|16@1- (0.001,0) [0|0] "" Vector__XXX
 SG_ HVP_energyReserveMax m1 : 32|16@1- (0.001,0) [0|0] "" Vector__XXX
 SG_ HVP_pyroSquibResistance m0 : 32|16@1+ (0.001,0) [0|0] "" Vector__XXX
 SG_ HVP_energyReserveAvg m1 : 48|16@1- (0.001,0) [0|0] "" Vector__XXX
 SG_ HVP_shuntAsicChipXCoordinate m0 : 48|8@1+ (1,0) [0|0] "" Vector__XXX
 SG_ HVP_shuntAsicChipYCoordinate m0 : 56|8@1+ (1,0) [0|0] "" Vector__XXX

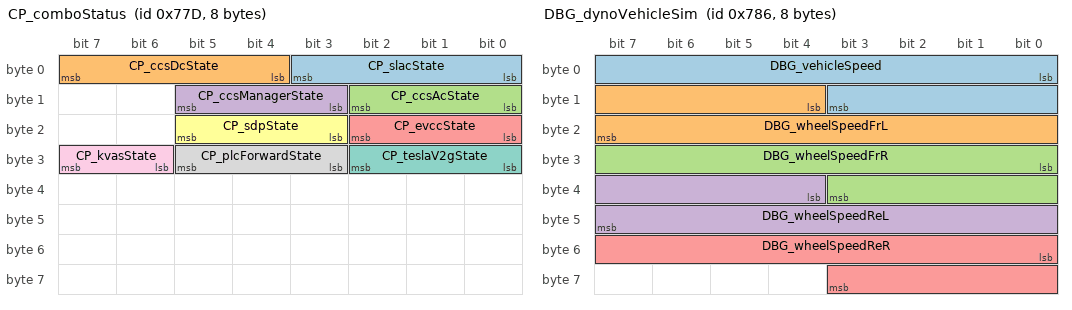
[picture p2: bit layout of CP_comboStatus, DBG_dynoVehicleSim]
BO_ 1917 CP_comboStatus: 8 Vector__XXX
 SG_ CP_slacState : 0|4@1+ (1,0) [0|0] "" Vector__XXX
 SG_ CP_ccsDcState : 4|4@1+ (1,0) [0|0] "" Vector__XXX
 SG_ CP_ccsAcState : 8|3@1+ (1,0) [0|0] "" Vector__XXX
 SG_ CP_ccsManagerState : 11|3@1+ (1,0) [0|0] "" Vector__XXX
 SG_ CP_evccState : 16|3@1+ (1,0) [0|0] "" Vector__XXX
 SG_ CP_sdpState : 19|3@1+ (1,0) [0|0] "" Vector__XXX
 SG_ CP_teslaV2gState : 24|3@1+ (1,0) [0|0] "" Vector__XXX
 SG_ CP_plcForwardState : 27|3@1+ (1,0) [0|0] "" Vector__XXX
 SG_ CP_kvasState : 30|2@1+ (1,0) [0|0] "" Vector__XXX

BO_ 1922 BMS_log3: 8 Vector__XXX
 SG_ BMS_log3MuxId M : 0|8@1+ (1,0) [0|0] "" Vector__XXX
 SG_ BMS_dSocAlphaBrick1 m0 : 8|14@1- (0.0030517578125,0) [0|0] "" Vector__XXX
 SG_ BMS_dSocAlphaBrick10 m9 : 8|14@1- (0.0030517578125,0) [0|0] "" Vector__XXX
 SG_ BMS_dSocAlphaBrick100 m99 : 8|14@1- (0.0030517578125,0) [0|0] "" Vector__XXX
 SG_ BMS_dSocAlphaBrick101 m100 : 8|14@1- (0.0030517578125,0) [0|0] "" Vector__XXX
 SG_ BMS_dSocAlphaBrick102 m101 : 8|14@1- (0.0030517578125,0) [0|0] "" Vector__XXX
 SG_ BMS_dSocAlphaBrick103 m102 : 8|14@1- (0.0030517578125,0) [0|0] "" Vector__XXX
 SG_ BMS_dSocAlphaBrick104 m103 : 8|14@1- (0.0030517578125,0) [0|0] "" Vector__XXX
 SG_ BMS_dSocAlphaBrick105 m104 : 8|14@1- (0.0030517578125,0) [0|0] "" Vector__XXX
 SG_ BMS_dSocAlphaBrick106 m105 : 8|14@1- (0.0030517578125,0) [0|0] "" Vector__XXX
 SG_ BMS_dSocAlphaBrick107 m106 : 8|14@1- (0.0030517578125,0) [0|0] "" Vector__XXX
 SG_ BMS_dSocAlphaBrick108 m107 : 8|14@1- (0.0030517578125,0) [0|0] "" Vector__XXX
 SG_ BMS_dSocAlphaBrick11 m10 : 8|14@1- (0.0030517578125,0) [0|0] "" Vector__XXX
 SG_ BMS_dSocAlphaBrick12 m11 : 8|14@1- (0.0030517578125,0) [0|0] "" Vector__XXX
 SG_ BMS_dSocAlphaBrick13 m12 : 8|14@1- (0.0030517578125,0) [0|0] "" Vector__XXX
 SG_ BMS_dSocAlphaBrick14 m13 : 8|14@1- (0.0030517578125,0) [0|0] "" Vector__XXX
 SG_ BMS_dSocAlphaBrick15 m14 : 8|14@1- (0.0030517578125,0) [0|0] "" Vector__XXX
 SG_ BMS_dSocAlphaBrick16 m15 : 8|14@1- (0.0030517578125,0) [0|0] "" Vector__XXX
 SG_ BMS_dSocAlphaBrick17 m16 : 8|14@1- (0.0030517578125,0) [0|0] "" Vector__XXX
 SG_ BMS_dSocAlphaBrick18 m17 : 8|14@1- (0.0030517578125,0) [0|0] "" Vector__XXX
 SG_ BMS_dSocAlphaBrick19 m18 : 8|14@1- (0.0030517578125,0) [0|0] "" Vector__XXX
 SG_ BMS_dSocAlphaBrick2 m1 : 8|14@1- (0.0030517578125,0) [0|0] "" Vector__XXX
 SG_ BMS_dSocAlphaBrick20 m19 : 8|14@1- (0.0030517578125,0) [0|0] "" Vector__XXX
 SG_ BMS_dSocAlphaBrick21 m20 : 8|14@1- (0.0030517578125,0) [0|0] "" Vector__XXX
 SG_ BMS_dSocAlphaBrick22 m21 : 8|14@1- (0.0030517578125,0) [0|0] "" Vector__XXX
 SG_ BMS_dSocAlphaBrick23 m22 : 8|14@1- (0.0030517578125,0) [0|0] "" Vector__XXX
 SG_ BMS_dSocAlphaBrick24 m23 : 8|14@1- (0.0030517578125,0) [0|0] "" Vector__XXX
 SG_ BMS_dSocAlphaBrick25 m24 : 8|14@1- (0.0030517578125,0) [0|0] "" Vector__XXX
 SG_ BMS_dSocAlphaBrick26 m25 : 8|14@1- (0.0030517578125,0) [0|0] "" Vector__XXX
 SG_ BMS_dSocAlphaBrick27 m26 : 8|14@1- (0.0030517578125,0) [0|0] "" Vector__XXX
 SG_ BMS_dSocAlphaBrick28 m27 : 8|14@1- (0.0030517578125,0) [0|0] "" Vector__XXX
 SG_ BMS_dSocAlphaBrick29 m28 : 8|14@1- (0.0030517578125,0) [0|0] "" Vector__XXX
 SG_ BMS_dSocAlphaBrick3 m2 : 8|14@1- (0.0030517578125,0) [0|0] "" Vector__XXX
 SG_ BMS_dSocAlphaBrick30 m29 : 8|14@1- (0.0030517578125,0) [0|0] "" Vector__XXX
 SG_ BMS_dSocAlphaBrick31 m30 : 8|14@1- (0.0030517578125,0) [0|0] "" Vector__XXX
 SG_ BMS_dSocAlphaBrick32 m31 : 8|14@1- (0.0030517578125,0) [0|0] "" Vector__XXX
 SG_ BMS_dSocAlphaBrick33 m32 : 8|14@1- (0.0030517578125,0) [0|0] "" Vector__XXX
 SG_ BMS_dSocAlphaBrick34 m33 : 8|14@1- (0.0030517578125,0) [0|0] "" Vector__XXX
 SG_ BMS_dSocAlphaBrick35 m34 : 8|14@1- (0.0030517578125,0) [0|0] "" Vector__XXX
 SG_ BMS_dSocAlphaBrick36 m35 : 8|14@1- (0.0030517578125,0) [0|0] "" Vector__XXX
 SG_ BMS_dSocAlphaBrick37 m36 : 8|14@1- (0.0030517578125,0) [0|0] "" Vector__XXX
 SG_ BMS_dSocAlphaBrick38 m37 : 8|14@1- (0.0030517578125,0) [0|0] "" Vector__XXX
 SG_ BMS_dSocAlphaBrick39 m38 : 8|14@1- (0.0030517578125,0) [0|0] "" Vector__XXX
 SG_ BMS_dSocAlphaBrick4 m3 : 8|14@1- (0.0030517578125,0) [0|0] "" Vector__XXX
 SG_ BMS_dSocAlphaBrick40 m39 : 8|14@1- (0.0030517578125,0) [0|0] "" Vector__XXX
 SG_ BMS_dSocAlphaBrick41 m40 : 8|14@1- (0.0030517578125,0) [0|0] "" Vector__XXX
 SG_ BMS_dSocAlphaBrick42 m41 : 8|14@1- (0.0030517578125,0) [0|0] "" Vector__XXX
 SG_ BMS_dSocAlphaBrick43 m42 : 8|14@1- (0.0030517578125,0) [0|0] "" Vector__XXX
 SG_ BMS_dSocAlphaBrick44 m43 : 8|14@1- (0.0030517578125,0) [0|0] "" Vector__XXX
 SG_ BMS_dSocAlphaBrick45 m44 : 8|14@1- (0.0030517578125,0) [0|0] "" Vector__XXX
 SG_ BMS_dSocAlphaBrick46 m45 : 8|14@1- (0.0030517578125,0) [0|0] "" Vector__XXX
 SG_ BMS_dSocAlphaBrick47 m46 : 8|14@1- (0.0030517578125,0) [0|0] "" Vector__XXX
 SG_ BMS_dSocAlphaBrick48 m47 : 8|14@1- (0.0030517578125,0) [0|0] "" Vector__XXX
 SG_ BMS_dSocAlphaBrick49 m48 : 8|14@1- (0.0030517578125,0) [0|0] "" Vector__XXX
 SG_ BMS_dSocAlphaBrick5 m4 : 8|14@1- (0.0030517578125,0) [0|0] "" Vector__XXX
 SG_ BMS_dSocAlphaBrick50 m49 : 8|14@1- (0.0030517578125,0) [0|0] "" Vector__XXX
 SG_ BMS_dSocAlphaBrick51 m50 : 8|14@1- (0.0030517578125,0) [0|0] "" Vector__XXX
 SG_ BMS_dSocAlphaBrick52 m51 : 8|14@1- (0.0030517578125,0) [0|0] "" Vector__XXX
 SG_ BMS_dSocAlphaBrick53 m52 : 8|14@1- (0.0030517578125,0) [0|0] "" Vector__XXX
 SG_ BMS_dSocAlphaBrick54 m53 : 8|14@1- (0.0030517578125,0) [0|0] "" Vector__XXX
 SG_ BMS_dSocAlphaBrick55 m54 : 8|14@1- (0.0030517578125,0) [0|0] "" Vector__XXX
 SG_ BMS_dSocAlphaBrick56 m55 : 8|14@1- (0.0030517578125,0) [0|0] "" Vector__XXX
 SG_ BMS_dSocAlphaBrick57 m56 : 8|14@1- (0.0030517578125,0) [0|0] "" Vector__XXX
 SG_ BMS_dSocAlphaBrick58 m57 : 8|14@1- (0.0030517578125,0) [0|0] "" Vector__XXX
 SG_ BMS_dSocAlphaBrick59 m58 : 8|14@1- (0.0030517578125,0) [0|0] "" Vector__XXX
 SG_ BMS_dSocAlphaBrick6 m5 : 8|14@1- (0.0030517578125,0) [0|0] "" Vector__XXX
 SG_ BMS_dSocAlphaBrick60 m59 : 8|14@1- (0.0030517578125,0) [0|0] "" Vector__XXX
 SG_ BMS_dSocAlphaBrick61 m60 : 8|14@1- (0.0030517578125,0) [0|0] "" Vector__XXX
 SG_ BMS_dSocAlphaBrick62 m61 : 8|14@1- (0.0030517578125,0) [0|0] "" Vector__XXX
 SG_ BMS_dSocAlphaBrick63 m62 : 8|14@1- (0.0030517578125,0) [0|0] "" Vector__XXX
 SG_ BMS_dSocAlphaBrick64 m63 : 8|14@1- (0.0030517578125,0) [0|0] "" Vector__XXX
 SG_ BMS_dSocAlphaBrick65 m64 : 8|14@1- (0.0030517578125,0) [0|0] "" Vector__XXX
 SG_ BMS_dSocAlphaBrick66 m65 : 8|14@1- (0.0030517578125,0) [0|0] "" Vector__XXX
 SG_ BMS_dSocAlphaBrick67 m66 : 8|14@1- (0.0030517578125,0) [0|0] "" Vector__XXX
 SG_ BMS_dSocAlphaBrick68 m67 : 8|14@1- (0.0030517578125,0) [0|0] "" Vector__XXX
 SG_ BMS_dSocAlphaBrick69 m68 : 8|14@1- (0.0030517578125,0) [0|0] "" Vector__XXX
 SG_ BMS_dSocAlphaBrick7 m6 : 8|14@1- (0.0030517578125,0) [0|0] "" Vector__XXX
 SG_ BMS_dSocAlphaBrick70 m69 : 8|14@1- (0.0030517578125,0) [0|0] "" Vector__XXX
 SG_ BMS_dSocAlphaBrick71 m70 : 8|14@1- (0.0030517578125,0) [0|0] "" Vector__XXX
 SG_ BMS_dSocAlphaBrick72 m71 : 8|14@1- (0.0030517578125,0) [0|0] "" Vector__XXX
 SG_ BMS_dSocAlphaBrick73 m72 : 8|14@1- (0.0030517578125,0) [0|0] "" Vector__XXX
 SG_ BMS_dSocAlphaBrick74 m73 : 8|14@1- (0.0030517578125,0) [0|0] "" Vector__XXX
 SG_ BMS_dSocAlphaBrick75 m74 : 8|14@1- (0.0030517578125,0) [0|0] "" Vector__XXX
 SG_ BMS_dSocAlphaBrick76 m75 : 8|14@1- (0.0030517578125,0) [0|0] "" Vector__XXX
 SG_ BMS_dSocAlphaBrick77 m76 : 8|14@1- (0.0030517578125,0) [0|0] "" Vector__XXX
 SG_ BMS_dSocAlphaBrick78 m77 : 8|14@1- (0.0030517578125,0) [0|0] "" Vector__XXX
 SG_ BMS_dSocAlphaBrick79 m78 : 8|14@1- (0.0030517578125,0) [0|0] "" Vector__XXX
 SG_ BMS_dSocAlphaBrick8 m7 : 8|14@1- (0.0030517578125,0) [0|0] "" Vector__XXX
 SG_ BMS_dSocAlphaBrick80 m79 : 8|14@1- (0.0030517578125,0) [0|0] "" Vector__XXX
 SG_ BMS_dSocAlphaBrick81 m80 : 8|14@1- (0.0030517578125,0) [0|0] "" Vector__XXX
 SG_ BMS_dSocAlphaBrick82 m81 : 8|14@1- (0.0030517578125,0) [0|0] "" Vector__XXX
 SG_ BMS_dSocAlphaBrick83 m82 : 8|14@1- (0.0030517578125,0) [0|0] "" Vector__XXX
 SG_ BMS_dSocAlphaBrick84 m83 : 8|14@1- (0.0030517578125,0) [0|0] "" Vector__XXX
 SG_ BMS_dSocAlphaBrick85 m84 : 8|14@1- (0.0030517578125,0) [0|0] "" Vector__XXX
 SG_ BMS_dSocAlphaBrick86 m85 : 8|14@1- (0.0030517578125,0) [0|0] "" Vector__XXX
 SG_ BMS_dSocAlphaBrick87 m86 : 8|14@1- (0.0030517578125,0) [0|0] "" Vector__XXX
 SG_ BMS_dSocAlphaBrick88 m87 : 8|14@1- (0.0030517578125,0) [0|0] "" Vector__XXX
 SG_ BMS_dSocAlphaBrick89 m88 : 8|14@1- (0.0030517578125,0) [0|0] "" Vector__XXX
 SG_ BMS_dSocAlphaBrick9 m8 : 8|14@1- (0.0030517578125,0) [0|0] "" Vector__XXX
 SG_ BMS_dSocAlphaBrick90 m89 : 8|14@1- (0.0030517578125,0) [0|0] "" Vector__XXX
 SG_ BMS_dSocAlphaBrick91 m90 : 8|14@1- (0.0030517578125,0) [0|0] "" Vector__XXX
 SG_ BMS_dSocAlphaBrick92 m91 : 8|14@1- (0.0030517578125,0) [0|0] "" Vector__XXX
 SG_ BMS_dSocAlphaBrick93 m92 : 8|14@1- (0.0030517578125,0) [0|0] "" Vector__XXX
 SG_ BMS_dSocAlphaBrick94 m93 : 8|14@1- (0.0030517578125,0) [0|0] "" Vector__XXX
 SG_ BMS_dSocAlphaBrick95 m94 : 8|14@1- (0.0030517578125,0) [0|0] "" Vector__XXX
 SG_ BMS_dSocAlphaBrick96 m95 : 8|14@1- (0.0030517578125,0) [0|0] "" Vector__XXX
 SG_ BMS_dSocAlphaBrick97 m96 : 8|14@1- (0.0030517578125,0) [0|0] "" Vector__XXX
 SG_ BMS_dSocAlphaBrick98 m97 : 8|14@1- (0.0030517578125,0) [0|0] "" Vector__XXX
 SG_ BMS_dSocAlphaBrick99 m98 : 8|14@1- (0.0030517578125,0) [0|0] "" Vector__XXX
 SG_ BMS_cacBrick1 m0 : 22|13@1+ (0.1,0) [0|0] "" Vector__XXX
 SG_ BMS_cacBrick10 m9 : 22|13@1+ (0.1,0) [0|0] "" Vector__XXX
 SG_ BMS_cacBrick100 m99 : 22|13@1+ (0.1,0) [0|0] "" Vector__XXX
 SG_ BMS_cacBrick101 m100 : 22|13@1+ (0.1,0) [0|0] "" Vector__XXX
 SG_ BMS_cacBrick102 m101 : 22|13@1+ (0.1,0) [0|0] "" Vector__XXX
 SG_ BMS_cacBrick103 m102 : 22|13@1+ (0.1,0) [0|0] "" Vector__XXX
 SG_ BMS_cacBrick104 m103 : 22|13@1+ (0.1,0) [0|0] "" Vector__XXX
 SG_ BMS_cacBrick105 m104 : 22|13@1+ (0.1,0) [0|0] "" Vector__XXX
 SG_ BMS_cacBrick106 m105 : 22|13@1+ (0.1,0) [0|0] "" Vector__XXX
 SG_ BMS_cacBrick107 m106 : 22|13@1+ (0.1,0) [0|0] "" Vector__XXX
 SG_ BMS_cacBrick108 m107 : 22|13@1+ (0.1,0) [0|0] "" Vector__XXX
 SG_ BMS_cacBrick11 m10 : 22|13@1+ (0.1,0) [0|0] "" Vector__XXX
 SG_ BMS_cacBrick12 m11 : 22|13@1+ (0.1,0) [0|0] "" Vector__XXX
 SG_ BMS_cacBrick13 m12 : 22|13@1+ (0.1,0) [0|0] "" Vector__XXX
 SG_ BMS_cacBrick14 m13 : 22|13@1+ (0.1,0) [0|0] "" Vector__XXX
 SG_ BMS_cacBrick15 m14 : 22|13@1+ (0.1,0) [0|0] "" Vector__XXX
 SG_ BMS_cacBrick16 m15 : 22|13@1+ (0.1,0) [0|0] "" Vector__XXX
 SG_ BMS_cacBrick17 m16 : 22|13@1+ (0.1,0) [0|0] "" Vector__XXX
 SG_ BMS_cacBrick18 m17 : 22|13@1+ (0.1,0) [0|0] "" Vector__XXX
 SG_ BMS_cacBrick19 m18 : 22|13@1+ (0.1,0) [0|0] "" Vector__XXX
 SG_ BMS_cacBrick2 m1 : 22|13@1+ (0.1,0) [0|0] "" Vector__XXX
 SG_ BMS_cacBrick20 m19 : 22|13@1+ (0.1,0) [0|0] "" Vector__XXX
 SG_ BMS_cacBrick21 m20 : 22|13@1+ (0.1,0) [0|0] "" Vector__XXX
 SG_ BMS_cacBrick22 m21 : 22|13@1+ (0.1,0) [0|0] "" Vector__XXX
 SG_ BMS_cacBrick23 m22 : 22|13@1+ (0.1,0) [0|0] "" Vector__XXX
 SG_ BMS_cacBrick24 m23 : 22|13@1+ (0.1,0) [0|0] "" Vector__XXX
 SG_ BMS_cacBrick25 m24 : 22|13@1+ (0.1,0) [0|0] "" Vector__XXX
 SG_ BMS_cacBrick26 m25 : 22|13@1+ (0.1,0) [0|0] "" Vector__XXX
 SG_ BMS_cacBrick27 m26 : 22|13@1+ (0.1,0) [0|0] "" Vector__XXX
 SG_ BMS_cacBrick28 m27 : 22|13@1+ (0.1,0) [0|0] "" Vector__XXX
 SG_ BMS_cacBrick29 m28 : 22|13@1+ (0.1,0) [0|0] "" Vector__XXX
 SG_ BMS_cacBrick3 m2 : 22|13@1+ (0.1,0) [0|0] "" Vector__XXX
 SG_ BMS_cacBrick30 m29 : 22|13@1+ (0.1,0) [0|0] "" Vector__XXX
 SG_ BMS_cacBrick31 m30 : 22|13@1+ (0.1,0) [0|0] "" Vector__XXX
 SG_ BMS_cacBrick32 m31 : 22|13@1+ (0.1,0) [0|0] "" Vector__XXX
 SG_ BMS_cacBrick33 m32 : 22|13@1+ (0.1,0) [0|0] "" Vector__XXX
 SG_ BMS_cacBrick34 m33 : 22|13@1+ (0.1,0) [0|0] "" Vector__XXX
 SG_ BMS_cacBrick35 m34 : 22|13@1+ (0.1,0) [0|0] "" Vector__XXX
 SG_ BMS_cacBrick36 m35 : 22|13@1+ (0.1,0) [0|0] "" Vector__XXX
 SG_ BMS_cacBrick37 m36 : 22|13@1+ (0.1,0) [0|0] "" Vector__XXX
 SG_ BMS_cacBrick38 m37 : 22|13@1+ (0.1,0) [0|0] "" Vector__XXX
 SG_ BMS_cacBrick39 m38 : 22|13@1+ (0.1,0) [0|0] "" Vector__XXX
 SG_ BMS_cacBrick4 m3 : 22|13@1+ (0.1,0) [0|0] "" Vector__XXX
 SG_ BMS_cacBrick40 m39 : 22|13@1+ (0.1,0) [0|0] "" Vector__XXX
 SG_ BMS_cacBrick41 m40 : 22|13@1+ (0.1,0) [0|0] "" Vector__XXX
 SG_ BMS_cacBrick42 m41 : 22|13@1+ (0.1,0) [0|0] "" Vector__XXX
 SG_ BMS_cacBrick43 m42 : 22|13@1+ (0.1,0) [0|0] "" Vector__XXX
 SG_ BMS_cacBrick44 m43 : 22|13@1+ (0.1,0) [0|0] "" Vector__XXX
 SG_ BMS_cacBrick45 m44 : 22|13@1+ (0.1,0) [0|0] "" Vector__XXX
 SG_ BMS_cacBrick46 m45 : 22|13@1+ (0.1,0) [0|0] "" Vector__XXX
 SG_ BMS_cacBrick47 m46 : 22|13@1+ (0.1,0) [0|0] "" Vector__XXX
 SG_ BMS_cacBrick48 m47 : 22|13@1+ (0.1,0) [0|0] "" Vector__XXX
 SG_ BMS_cacBrick49 m48 : 22|13@1+ (0.1,0) [0|0] "" Vector__XXX
 SG_ BMS_cacBrick5 m4 : 22|13@1+ (0.1,0) [0|0] "" Vector__XXX
 SG_ BMS_cacBrick50 m49 : 22|13@1+ (0.1,0) [0|0] "" Vector__XXX
 SG_ BMS_cacBrick51 m50 : 22|13@1+ (0.1,0) [0|0] "" Vector__XXX
 SG_ BMS_cacBrick52 m51 : 22|13@1+ (0.1,0) [0|0] "" Vector__XXX
 SG_ BMS_cacBrick53 m52 : 22|13@1+ (0.1,0) [0|0] "" Vector__XXX
 SG_ BMS_cacBrick54 m53 : 22|13@1+ (0.1,0) [0|0] "" Vector__XXX
 SG_ BMS_cacBrick55 m54 : 22|13@1+ (0.1,0) [0|0] "" Vector__XXX
 SG_ BMS_cacBrick56 m55 : 22|13@1+ (0.1,0) [0|0] "" Vector__XXX
 SG_ BMS_cacBrick57 m56 : 22|13@1+ (0.1,0) [0|0] "" Vector__XXX
 SG_ BMS_cacBrick58 m57 : 22|13@1+ (0.1,0) [0|0] "" Vector__XXX
 SG_ BMS_cacBrick59 m58 : 22|13@1+ (0.1,0) [0|0] "" Vector__XXX
 SG_ BMS_cacBrick6 m5 : 22|13@1+ (0.1,0) [0|0] "" Vector__XXX
 SG_ BMS_cacBrick60 m59 : 22|13@1+ (0.1,0) [0|0] "" Vector__XXX
 SG_ BMS_cacBrick61 m60 : 22|13@1+ (0.1,0) [0|0] "" Vector__XXX
 SG_ BMS_cacBrick62 m61 : 22|13@1+ (0.1,0) [0|0] "" Vector__XXX
 SG_ BMS_cacBrick63 m62 : 22|13@1+ (0.1,0) [0|0] "" Vector__XXX
 SG_ BMS_cacBrick64 m63 : 22|13@1+ (0.1,0) [0|0] "" Vector__XXX
 SG_ BMS_cacBrick65 m64 : 22|13@1+ (0.1,0) [0|0] "" Vector__XXX
 SG_ BMS_cacBrick66 m65 : 22|13@1+ (0.1,0) [0|0] "" Vector__XXX
 SG_ BMS_cacBrick67 m66 : 22|13@1+ (0.1,0) [0|0] "" Vector__XXX
 SG_ BMS_cacBrick68 m67 : 22|13@1+ (0.1,0) [0|0] "" Vector__XXX
 SG_ BMS_cacBrick69 m68 : 22|13@1+ (0.1,0) [0|0] "" Vector__XXX
 SG_ BMS_cacBrick7 m6 : 22|13@1+ (0.1,0) [0|0] "" Vector__XXX
 SG_ BMS_cacBrick70 m69 : 22|13@1+ (0.1,0) [0|0] "" Vector__XXX
 SG_ BMS_cacBrick71 m70 : 22|13@1+ (0.1,0) [0|0] "" Vector__XXX
 SG_ BMS_cacBrick72 m71 : 22|13@1+ (0.1,0) [0|0] "" Vector__XXX
 SG_ BMS_cacBrick73 m72 : 22|13@1+ (0.1,0) [0|0] "" Vector__XXX
 SG_ BMS_cacBrick74 m73 : 22|13@1+ (0.1,0) [0|0] "" Vector__XXX
 SG_ BMS_cacBrick75 m74 : 22|13@1+ (0.1,0) [0|0] "" Vector__XXX
 SG_ BMS_cacBrick76 m75 : 22|13@1+ (0.1,0) [0|0] "" Vector__XXX
 SG_ BMS_cacBrick77 m76 : 22|13@1+ (0.1,0) [0|0] "" Vector__XXX
 SG_ BMS_cacBrick78 m77 : 22|13@1+ (0.1,0) [0|0] "" Vector__XXX
 SG_ BMS_cacBrick79 m78 : 22|13@1+ (0.1,0) [0|0] "" Vector__XXX
 SG_ BMS_cacBrick8 m7 : 22|13@1+ (0.1,0) [0|0] "" Vector__XXX
 SG_ BMS_cacBrick80 m79 : 22|13@1+ (0.1,0) [0|0] "" Vector__XXX
 SG_ BMS_cacBrick81 m80 : 22|13@1+ (0.1,0) [0|0] "" Vector__XXX
 SG_ BMS_cacBrick82 m81 : 22|13@1+ (0.1,0) [0|0] "" Vector__XXX
 SG_ BMS_cacBrick83 m82 : 22|13@1+ (0.1,0) [0|0] "" Vector__XXX
 SG_ BMS_cacBrick84 m83 : 22|13@1+ (0.1,0) [0|0] "" Vector__XXX
 SG_ BMS_cacBrick85 m84 : 22|13@1+ (0.1,0) [0|0] "" Vector__XXX
 SG_ BMS_cacBrick86 m85 : 22|13@1+ (0.1,0) [0|0] "" Vector__XXX
 SG_ BMS_cacBrick87 m86 : 22|13@1+ (0.1,0) [0|0] "" Vector__XXX
 SG_ BMS_cacBrick88 m87 : 22|13@1+ (0.1,0) [0|0] "" Vector__XXX
 SG_ BMS_cacBrick89 m88 : 22|13@1+ (0.1,0) [0|0] "" Vector__XXX
 SG_ BMS_cacBrick9 m8 : 22|13@1+ (0.1,0) [0|0] "" Vector__XXX
 SG_ BMS_cacBrick90 m89 : 22|13@1+ (0.1,0) [0|0] "" Vector__XXX
 SG_ BMS_cacBrick91 m90 : 22|13@1+ (0.1,0) [0|0] "" Vector__XXX
 SG_ BMS_cacBrick92 m91 : 22|13@1+ (0.1,0) [0|0] "" Vector__XXX
 SG_ BMS_cacBrick93 m92 : 22|13@1+ (0.1,0) [0|0] "" Vector__XXX
 SG_ BMS_cacBrick94 m93 : 22|13@1+ (0.1,0) [0|0] "" Vector__XXX
 SG_ BMS_cacBrick95 m94 : 22|13@1+ (0.1,0) [0|0] "" Vector__XXX
 SG_ BMS_cacBrick96 m95 : 22|13@1+ (0.1,0) [0|0] "" Vector__XXX
 SG_ BMS_cacBrick97 m96 : 22|13@1+ (0.1,0) [0|0] "" Vector__XXX
 SG_ BMS_cacBrick98 m97 : 22|13@1+ (0.1,0) [0|0] "" Vector__XXX
 SG_ BMS_cacBrick99 m98 : 22|13@1+ (0.1,0) [0|0] "" Vector__XXX
 SG_ BMS_cacLowerBoundBrick1 m0 : 35|13@1+ (0.1,0) [0|0] "" Vector__XXX
 SG_ BMS_cacLowerBoundBrick10 m9 : 35|13@1+ (0.1,0) [0|0] "" Vector__XXX
 SG_ BMS_cacLowerBoundBrick100 m99 : 35|13@1+ (0.1,0) [0|0] "" Vector__XXX
 SG_ BMS_cacLowerBoundBrick101 m100 : 35|13@1+ (0.1,0) [0|0] "" Vector__XXX
 SG_ BMS_cacLowerBoundBrick102 m101 : 35|13@1+ (0.1,0) [0|0] "" Vector__XXX
 SG_ BMS_cacLowerBoundBrick103 m102 : 35|13@1+ (0.1,0) [0|0] "" Vector__XXX
 SG_ BMS_cacLowerBoundBrick104 m103 : 35|13@1+ (0.1,0) [0|0] "" Vector__XXX
 SG_ BMS_cacLowerBoundBrick105 m104 : 35|13@1+ (0.1,0) [0|0] "" Vector__XXX
 SG_ BMS_cacLowerBoundBrick106 m105 : 35|13@1+ (0.1,0) [0|0] "" Vector__XXX
 SG_ BMS_cacLowerBoundBrick107 m106 : 35|13@1+ (0.1,0) [0|0] "" Vector__XXX
 SG_ BMS_cacLowerBoundBrick108 m107 : 35|13@1+ (0.1,0) [0|0] "" Vector__XXX
 SG_ BMS_cacLowerBoundBrick11 m10 : 35|13@1+ (0.1,0) [0|0] "" Vector__XXX
 SG_ BMS_cacLowerBoundBrick12 m11 : 35|13@1+ (0.1,0) [0|0] "" Vector__XXX
 SG_ BMS_cacLowerBoundBrick13 m12 : 35|13@1+ (0.1,0) [0|0] "" Vector__XXX
 SG_ BMS_cacLowerBoundBrick14 m13 : 35|13@1+ (0.1,0) [0|0] "" Vector__XXX
 SG_ BMS_cacLowerBoundBrick15 m14 : 35|13@1+ (0.1,0) [0|0] "" Vector__XXX
 SG_ BMS_cacLowerBoundBrick16 m15 : 35|13@1+ (0.1,0) [0|0] "" Vector__XXX
 SG_ BMS_cacLowerBoundBrick17 m16 : 35|13@1+ (0.1,0) [0|0] "" Vector__XXX
 SG_ BMS_cacLowerBoundBrick18 m17 : 35|13@1+ (0.1,0) [0|0] "" Vector__XXX
 SG_ BMS_cacLowerBoundBrick19 m18 : 35|13@1+ (0.1,0) [0|0] "" Vector__XXX
 SG_ BMS_cacLowerBoundBrick2 m1 : 35|13@1+ (0.1,0) [0|0] "" Vector__XXX
 SG_ BMS_cacLowerBoundBrick20 m19 : 35|13@1+ (0.1,0) [0|0] "" Vector__XXX
 SG_ BMS_cacLowerBoundBrick21 m20 : 35|13@1+ (0.1,0) [0|0] "" Vector__XXX
 SG_ BMS_cacLowerBoundBrick22 m21 : 35|13@1+ (0.1,0) [0|0] "" Vector__XXX
 SG_ BMS_cacLowerBoundBrick23 m22 : 35|13@1+ (0.1,0) [0|0] "" Vector__XXX
 SG_ BMS_cacLowerBoundBrick24 m23 : 35|13@1+ (0.1,0) [0|0] "" Vector__XXX
 SG_ BMS_cacLowerBoundBrick25 m24 : 35|13@1+ (0.1,0) [0|0] "" Vector__XXX
 SG_ BMS_cacLowerBoundBrick26 m25 : 35|13@1+ (0.1,0) [0|0] "" Vector__XXX
 SG_ BMS_cacLowerBoundBrick27 m26 : 35|13@1+ (0.1,0) [0|0] "" Vector__XXX
 SG_ BMS_cacLowerBoundBrick28 m27 : 35|13@1+ (0.1,0) [0|0] "" Vector__XXX
 SG_ BMS_cacLowerBoundBrick29 m28 : 35|13@1+ (0.1,0) [0|0] "" Vector__XXX
 SG_ BMS_cacLowerBoundBrick3 m2 : 35|13@1+ (0.1,0) [0|0] "" Vector__XXX
 SG_ BMS_cacLowerBoundBrick30 m29 : 35|13@1+ (0.1,0) [0|0] "" Vector__XXX
 SG_ BMS_cacLowerBoundBrick31 m30 : 35|13@1+ (0.1,0) [0|0] "" Vector__XXX
 SG_ BMS_cacLowerBoundBrick32 m31 : 35|13@1+ (0.1,0) [0|0] "" Vector__XXX
 SG_ BMS_cacLowerBoundBrick33 m32 : 35|13@1+ (0.1,0) [0|0] "" Vector__XXX
 SG_ BMS_cacLowerBoundBrick34 m33 : 35|13@1+ (0.1,0) [0|0] "" Vector__XXX
 SG_ BMS_cacLowerBoundBrick35 m34 : 35|13@1+ (0.1,0) [0|0] "" Vector__XXX
 SG_ BMS_cacLowerBoundBrick36 m35 : 35|13@1+ (0.1,0) [0|0] "" Vector__XXX
 SG_ BMS_cacLowerBoundBrick37 m36 : 35|13@1+ (0.1,0) [0|0] "" Vector__XXX
 SG_ BMS_cacLowerBoundBrick38 m37 : 35|13@1+ (0.1,0) [0|0] "" Vector__XXX
 SG_ BMS_cacLowerBoundBrick39 m38 : 35|13@1+ (0.1,0) [0|0] "" Vector__XXX
 SG_ BMS_cacLowerBoundBrick4 m3 : 35|13@1+ (0.1,0) [0|0] "" Vector__XXX
 SG_ BMS_cacLowerBoundBrick40 m39 : 35|13@1+ (0.1,0) [0|0] "" Vector__XXX
 SG_ BMS_cacLowerBoundBrick41 m40 : 35|13@1+ (0.1,0) [0|0] "" Vector__XXX
 SG_ BMS_cacLowerBoundBrick42 m41 : 35|13@1+ (0.1,0) [0|0] "" Vector__XXX
 SG_ BMS_cacLowerBoundBrick43 m42 : 35|13@1+ (0.1,0) [0|0] "" Vector__XXX
 SG_ BMS_cacLowerBoundBrick44 m43 : 35|13@1+ (0.1,0) [0|0] "" Vector__XXX
 SG_ BMS_cacLowerBoundBrick45 m44 : 35|13@1+ (0.1,0) [0|0] "" Vector__XXX
 SG_ BMS_cacLowerBoundBrick46 m45 : 35|13@1+ (0.1,0) [0|0] "" Vector__XXX
 SG_ BMS_cacLowerBoundBrick47 m46 : 35|13@1+ (0.1,0) [0|0] "" Vector__XXX
 SG_ BMS_cacLowerBoundBrick48 m47 : 35|13@1+ (0.1,0) [0|0] "" Vector__XXX
 SG_ BMS_cacLowerBoundBrick49 m48 : 35|13@1+ (0.1,0) [0|0] "" Vector__XXX
 SG_ BMS_cacLowerBoundBrick5 m4 : 35|13@1+ (0.1,0) [0|0] "" Vector__XXX
 SG_ BMS_cacLowerBoundBrick50 m49 : 35|13@1+ (0.1,0) [0|0] "" Vector__XXX
 SG_ BMS_cacLowerBoundBrick51 m50 : 35|13@1+ (0.1,0) [0|0] "" Vector__XXX
 SG_ BMS_cacLowerBoundBrick52 m51 : 35|13@1+ (0.1,0) [0|0] "" Vector__XXX
 SG_ BMS_cacLowerBoundBrick53 m52 : 35|13@1+ (0.1,0) [0|0] "" Vector__XXX
 SG_ BMS_cacLowerBoundBrick54 m53 : 35|13@1+ (0.1,0) [0|0] "" Vector__XXX
 SG_ BMS_cacLowerBoundBrick55 m54 : 35|13@1+ (0.1,0) [0|0] "" Vector__XXX
 SG_ BMS_cacLowerBoundBrick56 m55 : 35|13@1+ (0.1,0) [0|0] "" Vector__XXX
 SG_ BMS_cacLowerBoundBrick57 m56 : 35|13@1+ (0.1,0) [0|0] "" Vector__XXX
 SG_ BMS_cacLowerBoundBrick58 m57 : 35|13@1+ (0.1,0) [0|0] "" Vector__XXX
 SG_ BMS_cacLowerBoundBrick59 m58 : 35|13@1+ (0.1,0) [0|0] "" Vector__XXX
 SG_ BMS_cacLowerBoundBrick6 m5 : 35|13@1+ (0.1,0) [0|0] "" Vector__XXX
 SG_ BMS_cacLowerBoundBrick60 m59 : 35|13@1+ (0.1,0) [0|0] "" Vector__XXX
 SG_ BMS_cacLowerBoundBrick61 m60 : 35|13@1+ (0.1,0) [0|0] "" Vector__XXX
 SG_ BMS_cacLowerBoundBrick62 m61 : 35|13@1+ (0.1,0) [0|0] "" Vector__XXX
 SG_ BMS_cacLowerBoundBrick63 m62 : 35|13@1+ (0.1,0) [0|0] "" Vector__XXX
 SG_ BMS_cacLowerBoundBrick64 m63 : 35|13@1+ (0.1,0) [0|0] "" Vector__XXX
 SG_ BMS_cacLowerBoundBrick65 m64 : 35|13@1+ (0.1,0) [0|0] "" Vector__XXX
 SG_ BMS_cacLowerBoundBrick66 m65 : 35|13@1+ (0.1,0) [0|0] "" Vector__XXX
 SG_ BMS_cacLowerBoundBrick67 m66 : 35|13@1+ (0.1,0) [0|0] "" Vector__XXX
 SG_ BMS_cacLowerBoundBrick68 m67 : 35|13@1+ (0.1,0) [0|0] "" Vector__XXX
 SG_ BMS_cacLowerBoundBrick69 m68 : 35|13@1+ (0.1,0) [0|0] "" Vector__XXX
 SG_ BMS_cacLowerBoundBrick7 m6 : 35|13@1+ (0.1,0) [0|0] "" Vector__XXX
 SG_ BMS_cacLowerBoundBrick70 m69 : 35|13@1+ (0.1,0) [0|0] "" Vector__XXX
 SG_ BMS_cacLowerBoundBrick71 m70 : 35|13@1+ (0.1,0) [0|0] "" Vector__XXX
 SG_ BMS_cacLowerBoundBrick72 m71 : 35|13@1+ (0.1,0) [0|0] "" Vector__XXX
 SG_ BMS_cacLowerBoundBrick73 m72 : 35|13@1+ (0.1,0) [0|0] "" Vector__XXX
 SG_ BMS_cacLowerBoundBrick74 m73 : 35|13@1+ (0.1,0) [0|0] "" Vector__XXX
 SG_ BMS_cacLowerBoundBrick75 m74 : 35|13@1+ (0.1,0) [0|0] "" Vector__XXX
 SG_ BMS_cacLowerBoundBrick76 m75 : 35|13@1+ (0.1,0) [0|0] "" Vector__XXX
 SG_ BMS_cacLowerBoundBrick77 m76 : 35|13@1+ (0.1,0) [0|0] "" Vector__XXX
 SG_ BMS_cacLowerBoundBrick78 m77 : 35|13@1+ (0.1,0) [0|0] "" Vector__XXX
 SG_ BMS_cacLowerBoundBrick79 m78 : 35|13@1+ (0.1,0) [0|0] "" Vector__XXX
 SG_ BMS_cacLowerBoundBrick8 m7 : 35|13@1+ (0.1,0) [0|0] "" Vector__XXX
 SG_ BMS_cacLowerBoundBrick80 m79 : 35|13@1+ (0.1,0) [0|0] "" Vector__XXX
 SG_ BMS_cacLowerBoundBrick81 m80 : 35|13@1+ (0.1,0) [0|0] "" Vector__XXX
 SG_ BMS_cacLowerBoundBrick82 m81 : 35|13@1+ (0.1,0) [0|0] "" Vector__XXX
 SG_ BMS_cacLowerBoundBrick83 m82 : 35|13@1+ (0.1,0) [0|0] "" Vector__XXX
 SG_ BMS_cacLowerBoundBrick84 m83 : 35|13@1+ (0.1,0) [0|0] "" Vector__XXX
 SG_ BMS_cacLowerBoundBrick85 m84 : 35|13@1+ (0.1,0) [0|0] "" Vector__XXX
 SG_ BMS_cacLowerBoundBrick86 m85 : 35|13@1+ (0.1,0) [0|0] "" Vector__XXX
 SG_ BMS_cacLowerBoundBrick87 m86 : 35|13@1+ (0.1,0) [0|0] "" Vector__XXX
 SG_ BMS_cacLowerBoundBrick88 m87 : 35|13@1+ (0.1,0) [0|0] "" Vector__XXX
 SG_ BMS_cacLowerBoundBrick89 m88 : 35|13@1+ (0.1,0) [0|0] "" Vector__XXX
 SG_ BMS_cacLowerBoundBrick9 m8 : 35|13@1+ (0.1,0) [0|0] "" Vector__XXX
 SG_ BMS_cacLowerBoundBrick90 m89 : 35|13@1+ (0.1,0) [0|0] "" Vector__XXX
 SG_ BMS_cacLowerBoundBrick91 m90 : 35|13@1+ (0.1,0) [0|0] "" Vector__XXX
 SG_ BMS_cacLowerBoundBrick92 m91 : 35|13@1+ (0.1,0) [0|0] "" Vector__XXX
 SG_ BMS_cacLowerBoundBrick93 m92 : 35|13@1+ (0.1,0) [0|0] "" Vector__XXX
 SG_ BMS_cacLowerBoundBrick94 m93 : 35|13@1+ (0.1,0) [0|0] "" Vector__XXX
 SG_ BMS_cacLowerBoundBrick95 m94 : 35|13@1+ (0.1,0) [0|0] "" Vector__XXX
 SG_ BMS_cacLowerBoundBrick96 m95 : 35|13@1+ (0.1,0) [0|0] "" Vector__XXX
 SG_ BMS_cacLowerBoundBrick97 m96 : 35|13@1+ (0.1,0) [0|0] "" Vector__XXX
 SG_ BMS_cacLowerBoundBrick98 m97 : 35|13@1+ (0.1,0) [0|0] "" Vector__XXX
 SG_ BMS_cacLowerBoundBrick99 m98 : 35|13@1+ (0.1,0) [0|0] "" Vector__XXX
 SG_ BMS_cacRawEstimateBrick1 m0 : 48|13@1+ (0.1,0) [0|0] "" Vector__XXX
 SG_ BMS_cacRawEstimateBrick10 m9 : 48|13@1+ (0.1,0) [0|0] "" Vector__XXX
 SG_ BMS_cacRawEstimateBrick100 m99 : 48|13@1+ (0.1,0) [0|0] "" Vector__XXX
 SG_ BMS_cacRawEstimateBrick101 m100 : 48|13@1+ (0.1,0) [0|0] "" Vector__XXX
 SG_ BMS_cacRawEstimateBrick102 m101 : 48|13@1+ (0.1,0) [0|0] "" Vector__XXX
 SG_ BMS_cacRawEstimateBrick103 m102 : 48|13@1+ (0.1,0) [0|0] "" Vector__XXX
 SG_ BMS_cacRawEstimateBrick104 m103 : 48|13@1+ (0.1,0) [0|0] "" Vector__XXX
 SG_ BMS_cacRawEstimateBrick105 m104 : 48|13@1+ (0.1,0) [0|0] "" Vector__XXX
 SG_ BMS_cacRawEstimateBrick106 m105 : 48|13@1+ (0.1,0) [0|0] "" Vector__XXX
 SG_ BMS_cacRawEstimateBrick107 m106 : 48|13@1+ (0.1,0) [0|0] "" Vector__XXX
 SG_ BMS_cacRawEstimateBrick108 m107 : 48|13@1+ (0.1,0) [0|0] "" Vector__XXX
 SG_ BMS_cacRawEstimateBrick11 m10 : 48|13@1+ (0.1,0) [0|0] "" Vector__XXX
 SG_ BMS_cacRawEstimateBrick12 m11 : 48|13@1+ (0.1,0) [0|0] "" Vector__XXX
 SG_ BMS_cacRawEstimateBrick13 m12 : 48|13@1+ (0.1,0) [0|0] "" Vector__XXX
 SG_ BMS_cacRawEstimateBrick14 m13 : 48|13@1+ (0.1,0) [0|0] "" Vector__XXX
 SG_ BMS_cacRawEstimateBrick15 m14 : 48|13@1+ (0.1,0) [0|0] "" Vector__XXX
 SG_ BMS_cacRawEstimateBrick16 m15 : 48|13@1+ (0.1,0) [0|0] "" Vector__XXX
 SG_ BMS_cacRawEstimateBrick17 m16 : 48|13@1+ (0.1,0) [0|0] "" Vector__XXX
 SG_ BMS_cacRawEstimateBrick18 m17 : 48|13@1+ (0.1,0) [0|0] "" Vector__XXX
 SG_ BMS_cacRawEstimateBrick19 m18 : 48|13@1+ (0.1,0) [0|0] "" Vector__XXX
 SG_ BMS_cacRawEstimateBrick2 m1 : 48|13@1+ (0.1,0) [0|0] "" Vector__XXX
 SG_ BMS_cacRawEstimateBrick20 m19 : 48|13@1+ (0.1,0) [0|0] "" Vector__XXX
 SG_ BMS_cacRawEstimateBrick21 m20 : 48|13@1+ (0.1,0) [0|0] "" Vector__XXX
 SG_ BMS_cacRawEstimateBrick22 m21 : 48|13@1+ (0.1,0) [0|0] "" Vector__XXX
 SG_ BMS_cacRawEstimateBrick23 m22 : 48|13@1+ (0.1,0) [0|0] "" Vector__XXX
 SG_ BMS_cacRawEstimateBrick24 m23 : 48|13@1+ (0.1,0) [0|0] "" Vector__XXX
 SG_ BMS_cacRawEstimateBrick25 m24 : 48|13@1+ (0.1,0) [0|0] "" Vector__XXX
 SG_ BMS_cacRawEstimateBrick26 m25 : 48|13@1+ (0.1,0) [0|0] "" Vector__XXX
 SG_ BMS_cacRawEstimateBrick27 m26 : 48|13@1+ (0.1,0) [0|0] "" Vector__XXX
 SG_ BMS_cacRawEstimateBrick28 m27 : 48|13@1+ (0.1,0) [0|0] "" Vector__XXX
 SG_ BMS_cacRawEstimateBrick29 m28 : 48|13@1+ (0.1,0) [0|0] "" Vector__XXX
 SG_ BMS_cacRawEstimateBrick3 m2 : 48|13@1+ (0.1,0) [0|0] "" Vector__XXX
 SG_ BMS_cacRawEstimateBrick30 m29 : 48|13@1+ (0.1,0) [0|0] "" Vector__XXX
 SG_ BMS_cacRawEstimateBrick31 m30 : 48|13@1+ (0.1,0) [0|0] "" Vector__XXX
 SG_ BMS_cacRawEstimateBrick32 m31 : 48|13@1+ (0.1,0) [0|0] "" Vector__XXX
 SG_ BMS_cacRawEstimateBrick33 m32 : 48|13@1+ (0.1,0) [0|0] "" Vector__XXX
 SG_ BMS_cacRawEstimateBrick34 m33 : 48|13@1+ (0.1,0) [0|0] "" Vector__XXX
 SG_ BMS_cacRawEstimateBrick35 m34 : 48|13@1+ (0.1,0) [0|0] "" Vector__XXX
 SG_ BMS_cacRawEstimateBrick36 m35 : 48|13@1+ (0.1,0) [0|0] "" Vector__XXX
 SG_ BMS_cacRawEstimateBrick37 m36 : 48|13@1+ (0.1,0) [0|0] "" Vector__XXX
 SG_ BMS_cacRawEstimateBrick38 m37 : 48|13@1+ (0.1,0) [0|0] "" Vector__XXX
 SG_ BMS_cacRawEstimateBrick39 m38 : 48|13@1+ (0.1,0) [0|0] "" Vector__XXX
 SG_ BMS_cacRawEstimateBrick4 m3 : 48|13@1+ (0.1,0) [0|0] "" Vector__XXX
 SG_ BMS_cacRawEstimateBrick40 m39 : 48|13@1+ (0.1,0) [0|0] "" Vector__XXX
 SG_ BMS_cacRawEstimateBrick41 m40 : 48|13@1+ (0.1,0) [0|0] "" Vector__XXX
 SG_ BMS_cacRawEstimateBrick42 m41 : 48|13@1+ (0.1,0) [0|0] "" Vector__XXX
 SG_ BMS_cacRawEstimateBrick43 m42 : 48|13@1+ (0.1,0) [0|0] "" Vector__XXX
 SG_ BMS_cacRawEstimateBrick44 m43 : 48|13@1+ (0.1,0) [0|0] "" Vector__XXX
 SG_ BMS_cacRawEstimateBrick45 m44 : 48|13@1+ (0.1,0) [0|0] "" Vector__XXX
 SG_ BMS_cacRawEstimateBrick46 m45 : 48|13@1+ (0.1,0) [0|0] "" Vector__XXX
 SG_ BMS_cacRawEstimateBrick47 m46 : 48|13@1+ (0.1,0) [0|0] "" Vector__XXX
 SG_ BMS_cacRawEstimateBrick48 m47 : 48|13@1+ (0.1,0) [0|0] "" Vector__XXX
 SG_ BMS_cacRawEstimateBrick49 m48 : 48|13@1+ (0.1,0) [0|0] "" Vector__XXX
 SG_ BMS_cacRawEstimateBrick5 m4 : 48|13@1+ (0.1,0) [0|0] "" Vector__XXX
 SG_ BMS_cacRawEstimateBrick50 m49 : 48|13@1+ (0.1,0) [0|0] "" Vector__XXX
 SG_ BMS_cacRawEstimateBrick51 m50 : 48|13@1+ (0.1,0) [0|0] "" Vector__XXX
 SG_ BMS_cacRawEstimateBrick52 m51 : 48|13@1+ (0.1,0) [0|0] "" Vector__XXX
 SG_ BMS_cacRawEstimateBrick53 m52 : 48|13@1+ (0.1,0) [0|0] "" Vector__XXX
 SG_ BMS_cacRawEstimateBrick54 m53 : 48|13@1+ (0.1,0) [0|0] "" Vector__XXX
 SG_ BMS_cacRawEstimateBrick55 m54 : 48|13@1+ (0.1,0) [0|0] "" Vector__XXX
 SG_ BMS_cacRawEstimateBrick56 m55 : 48|13@1+ (0.1,0) [0|0] "" Vector__XXX
 SG_ BMS_cacRawEstimateBrick57 m56 : 48|13@1+ (0.1,0) [0|0] "" Vector__XXX
 SG_ BMS_cacRawEstimateBrick58 m57 : 48|13@1+ (0.1,0) [0|0] "" Vector__XXX
 SG_ BMS_cacRawEstimateBrick59 m58 : 48|13@1+ (0.1,0) [0|0] "" Vector__XXX
 SG_ BMS_cacRawEstimateBrick6 m5 : 48|13@1+ (0.1,0) [0|0] "" Vector__XXX
 SG_ BMS_cacRawEstimateBrick60 m59 : 48|13@1+ (0.1,0) [0|0] "" Vector__XXX
 SG_ BMS_cacRawEstimateBrick61 m60 : 48|13@1+ (0.1,0) [0|0] "" Vector__XXX
 SG_ BMS_cacRawEstimateBrick62 m61 : 48|13@1+ (0.1,0) [0|0] "" Vector__XXX
 SG_ BMS_cacRawEstimateBrick63 m62 : 48|13@1+ (0.1,0) [0|0] "" Vector__XXX
 SG_ BMS_cacRawEstimateBrick64 m63 : 48|13@1+ (0.1,0) [0|0] "" Vector__XXX
 SG_ BMS_cacRawEstimateBrick65 m64 : 48|13@1+ (0.1,0) [0|0] "" Vector__XXX
 SG_ BMS_cacRawEstimateBrick66 m65 : 48|13@1+ (0.1,0) [0|0] "" Vector__XXX
 SG_ BMS_cacRawEstimateBrick67 m66 : 48|13@1+ (0.1,0) [0|0] "" Vector__XXX
 SG_ BMS_cacRawEstimateBrick68 m67 : 48|13@1+ (0.1,0) [0|0] "" Vector__XXX
 SG_ BMS_cacRawEstimateBrick69 m68 : 48|13@1+ (0.1,0) [0|0] "" Vector__XXX
 SG_ BMS_cacRawEstimateBrick7 m6 : 48|13@1+ (0.1,0) [0|0] "" Vector__XXX
 SG_ BMS_cacRawEstimateBrick70 m69 : 48|13@1+ (0.1,0) [0|0] "" Vector__XXX
 SG_ BMS_cacRawEstimateBrick71 m70 : 48|13@1+ (0.1,0) [0|0] "" Vector__XXX
 SG_ BMS_cacRawEstimateBrick72 m71 : 48|13@1+ (0.1,0) [0|0] "" Vector__XXX
 SG_ BMS_cacRawEstimateBrick73 m72 : 48|13@1+ (0.1,0) [0|0] "" Vector__XXX
 SG_ BMS_cacRawEstimateBrick74 m73 : 48|13@1+ (0.1,0) [0|0] "" Vector__XXX
 SG_ BMS_cacRawEstimateBrick75 m74 : 48|13@1+ (0.1,0) [0|0] "" Vector__XXX
 SG_ BMS_cacRawEstimateBrick76 m75 : 48|13@1+ (0.1,0) [0|0] "" Vector__XXX
 SG_ BMS_cacRawEstimateBrick77 m76 : 48|13@1+ (0.1,0) [0|0] "" Vector__XXX
 SG_ BMS_cacRawEstimateBrick78 m77 : 48|13@1+ (0.1,0) [0|0] "" Vector__XXX
 SG_ BMS_cacRawEstimateBrick79 m78 : 48|13@1+ (0.1,0) [0|0] "" Vector__XXX
 SG_ BMS_cacRawEstimateBrick8 m7 : 48|13@1+ (0.1,0) [0|0] "" Vector__XXX
 SG_ BMS_cacRawEstimateBrick80 m79 : 48|13@1+ (0.1,0) [0|0] "" Vector__XXX
 SG_ BMS_cacRawEstimateBrick81 m80 : 48|13@1+ (0.1,0) [0|0] "" Vector__XXX
 SG_ BMS_cacRawEstimateBrick82 m81 : 48|13@1+ (0.1,0) [0|0] "" Vector__XXX
 SG_ BMS_cacRawEstimateBrick83 m82 : 48|13@1+ (0.1,0) [0|0] "" Vector__XXX
 SG_ BMS_cacRawEstimateBrick84 m83 : 48|13@1+ (0.1,0) [0|0] "" Vector__XXX
 SG_ BMS_cacRawEstimateBrick85 m84 : 48|13@1+ (0.1,0) [0|0] "" Vector__XXX
 SG_ BMS_cacRawEstimateBrick86 m85 : 48|13@1+ (0.1,0) [0|0] "" Vector__XXX
 SG_ BMS_cacRawEstimateBrick87 m86 : 48|13@1+ (0.1,0) [0|0] "" Vector__XXX
 SG_ BMS_cacRawEstimateBrick88 m87 : 48|13@1+ (0.1,0) [0|0] "" Vector__XXX
 SG_ BMS_cacRawEstimateBrick89 m88 : 48|13@1+ (0.1,0) [0|0] "" Vector__XXX
 SG_ BMS_cacRawEstimateBrick9 m8 : 48|13@1+ (0.1,0) [0|0] "" Vector__XXX
 SG_ BMS_cacRawEstimateBrick90 m89 : 48|13@1+ (0.1,0) [0|0] "" Vector__XXX
 SG_ BMS_cacRawEstimateBrick91 m90 : 48|13@1+ (0.1,0) [0|0] "" Vector__XXX
 SG_ BMS_cacRawEstimateBrick92 m91 : 48|13@1+ (0.1,0) [0|0] "" Vector__XXX
 SG_ BMS_cacRawEstimateBrick93 m92 : 48|13@1+ (0.1,0) [0|0] "" Vector__XXX
 SG_ BMS_cacRawEstimateBrick94 m93 : 48|13@1+ (0.1,0) [0|0] "" Vector__XXX
 SG_ BMS_cacRawEstimateBrick95 m94 : 48|13@1+ (0.1,0) [0|0] "" Vector__XXX
 SG_ BMS_cacRawEstimateBrick96 m95 : 48|13@1+ (0.1,0) [0|0] "" Vector__XXX
 SG_ BMS_cacRawEstimateBrick97 m96 : 48|13@1+ (0.1,0) [0|0] "" Vector__XXX
 SG_ BMS_cacRawEstimateBrick98 m97 : 48|13@1+ (0.1,0) [0|0] "" Vector__XXX
 SG_ BMS_cacRawEstimateBrick99 m98 : 48|13@1+ (0.1,0) [0|0] "" Vector__XXX

BO_ 1924 XCP_pmfRequest: 12 Vector__XXX
 SG_ XCP_pmfRequestData : 7|64@0+ (1,0) [0|0] "" Vector__XXX

BO_ 1926 DBG_dynoVehicleSim: 8 Vector__XXX
 SG_ DBG_vehicleSpeed : 0|12@1+ (0.08,-40) [0|0] "" Vector__XXX
 SG_ DBG_wheelSpeedFrL : 12|12@1+ (0.08,-40) [0|0] "" Vector__XXX
 SG_ DBG_wheelSpeedFrR : 24|12@1+ (0.08,-40) [0|0] "" Vector__XXX
 SG_ DBG_wheelSpeedReL : 36|12@1+ (0.08,-40) [0|0] "" Vector__XXX
 SG_ DBG_wheelSpeedReR : 48|12@1+ (0.08,-40) [0|0] "" Vector__XXX

BO_ 1928 EPBL_debugOutput: 8 Vector__XXX
 SG_ EPBL_debugOutputIndex M : 0|2@1+ (1,0) [0|0] "" Vector__XXX
 SG_ EPBL_12VFilt_SW m0 : 2|9@1+ (0.043549408784,0) [0|0] "" Vector__XXX
 SG_ EPBL_limpToDecelTimer m2 : 2|10@1+ (1,0) [0|0] "" Vector__XXX
 SG_ EPBL_pid_uP m1 : 2|10@1- (0.2,0) [0|0] "" Vector__XXX
 SG_ EPBL_nvFilt m0 : 11|9@1+ (0.043549408784,0) [0|0] "" Vector__XXX
 SG_ EPBL_emergencyOperationMode m2 : 12|2@1+ (1,0) [0|0] "" Vector__XXX
 SG_ EPBL_pid_uI m1 : 12|10@1- (0.2,0) [0|0] "" Vector__XXX
 SG_ EPBL_dynamicManagerReady m2 : 14|1@1+ (1,0) [0|0] "" Vector__XXX
 SG_ EPBL_driverLockedOut m2 : 15|1@1+ (1,0) [0|0] "" Vector__XXX
 SG_ EPBL_currentOffset m2 : 16|12@1+ (0.016997132,-37.55274262) [0|0] "" Vector__XXX
 SG_ EPBL_pvFilt m0 : 20|9@1+ (0.043549408784,0) [0|0] "" Vector__XXX
 SG_ EPBL_pid_duty m1 : 22|10@1- (0.2,0) [0|0] "" Vector__XXX
 SG_ EPBL_filteredCurrentPeak m2 : 28|12@1+ (0.01,0) [0|0] "" Vector__XXX
 SG_ EPBL_caliperState m0 : 29|3@1+ (1,0) [0|0] "" Vector__XXX
 SG_ EPBL_nFault m0 : 32|1@1+ (1,0) [0|0] "" Vector__XXX
 SG_ EPBL_ramp m1 : 32|8@1+ (0.392157,0) [0|0] "" Vector__XXX
 SG_ EPBL_oocViolation m0 : 33|1@1+ (1,0) [0|0] "" Vector__XXX
 SG_ EPBL_atEndStop m0 : 34|1@1+ (1,0) [0|0] "" Vector__XXX
 SG_ EPBL_currentVariance m0 : 35|14@1- (0.0007629394535064697,0) [0|0] "" Vector__XXX
 SG_ EPBL_lockoutOutputDI m2 : 40|1@1+ (1,0) [0|0] "" Vector__XXX
 SG_ EPBL_pid_error m1 : 40|12@1+ (0.016997132,-37.55274262) [0|0] "" Vector__XXX
 SG_ EPBL_lockoutCommandDI m2 : 41|1@1+ (1,0) [0|0] "" Vector__XXX
 SG_ EPBL_brakeDiscWipeAccumul m2 : 48|8@1+ (1,0) [0|0] "" Vector__XXX
 SG_ EPBL_lockoutUnlockCount m0 : 49|6@1+ (1,0) [0|0] "" Vector__XXX
 SG_ EPBL_12VFilt m1 : 52|9@1+ (0.043549408784,0) [0|0] "" Vector__XXX
 SG_ EPBL_esmCaliperRequest m0 : 55|3@1+ (1,0) [0|0] "" Vector__XXX
 SG_ EPBL_brakePressHeld m0 : 58|1@1+ (1,0) [0|0] "" Vector__XXX
 SG_ EPBL_epbOpenUnableToPark m0 : 59|1@1+ (1,0) [0|0] "" Vector__XXX
 SG_ EPBL_slopeParkable m0 : 60|1@1+ (1,0) [0|0] "" Vector__XXX
 SG_ EPBL_driverIsLeavingDisabled m0 : 61|1@1+ (1,0) [0|0] "" Vector__XXX
 SG_ EPBL_uiNotAvailable m0 : 62|1@1+ (1,0) [0|0] "" Vector__XXX

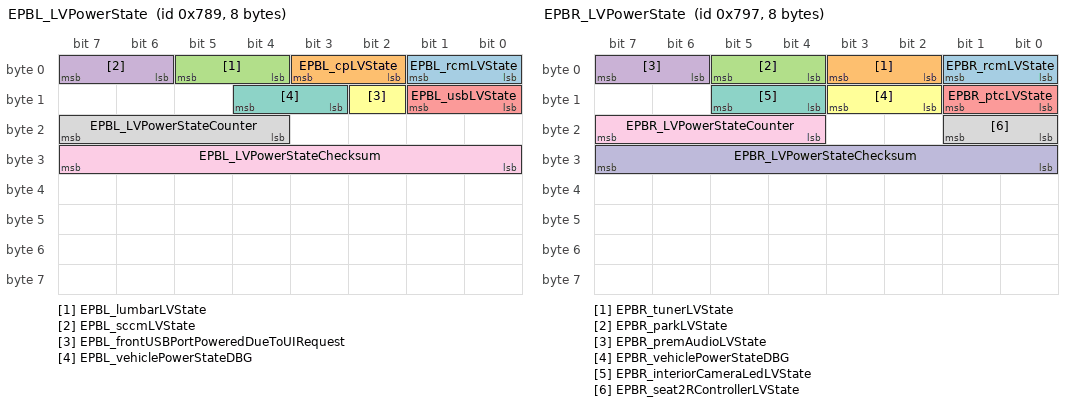
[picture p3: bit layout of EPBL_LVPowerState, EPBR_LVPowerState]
BO_ 1929 EPBL_LVPowerState: 8 Vector__XXX
 SG_ EPBL_rcmLVState : 0|2@1+ (1,0) [0|0] "" Vector__XXX
 SG_ EPBL_cpLVState : 2|2@1+ (1,0) [0|0] "" Vector__XXX
 SG_ EPBL_lumbarLVState : 4|2@1+ (1,0) [0|0] "" Vector__XXX
 SG_ EPBL_sccmLVState : 6|2@1+ (1,0) [0|0] "" Vector__XXX
 SG_ EPBL_usbLVState : 8|2@1+ (1,0) [0|0] "" Vector__XXX
 SG_ EPBL_frontUSBPortPoweredDueToUIRequest : 10|1@1+ (1,0) [0|0] "" Vector__XXX
 SG_ EPBL_vehiclePowerStateDBG : 11|2@1+ (1,0) [0|0] "" Vector__XXX
 SG_ EPBL_LVPowerStateCounter : 20|4@1+ (1,0) [0|0] "" Vector__XXX
 SG_ EPBL_LVPowerStateChecksum : 24|8@1+ (1,0) [0|0] "" Vector__XXX

BO_ 1930 HVP_pyroDeviceDbg: 8 Vector__XXX
 SG_ HVP_pyroStatus : 0|2@1+ (1,0) [0|0] "" Vector__XXX
 SG_ HVP_pyroTestRefCurrentFailed : 2|1@1+ (1,0) [0|0] "" Vector__XXX
 SG_ HVP_pyroTestSquibResFailed : 3|1@1+ (1,0) [0|0] "" Vector__XXX
 SG_ HVP_pyroTestErFailed : 4|1@1+ (1,0) [0|0] "" Vector__XXX
 SG_ HVP_pyroTestVstFailed : 5|1@1+ (1,0) [0|0] "" Vector__XXX
 SG_ HVP_pyroTestHighSideSwitchFailed : 6|1@1+ (1,0) [0|0] "" Vector__XXX
 SG_ HVP_pyroTestLowSideSwitchFailed : 7|1@1+ (1,0) [0|0] "" Vector__XXX
 SG_ HVP_pyroTestPyroLeakFailed : 8|1@1+ (1,0) [0|0] "" Vector__XXX
 SG_ HVP_pyroSquibFired : 9|1@1+ (1,0) [0|0] "" Vector__XXX
 SG_ HVP_pyroFiringHandle : 10|4@1+ (1,0) [0|0] "" Vector__XXX
 SG_ HVP_pyroAoutMultiplexer M : 16|3@1+ (1,0) [0|0] "" Vector__XXX
 SG_ HVP_pyroAoutEr1 m1 : 32|16@1+ (0.001,0) [0|0] "" Vector__XXX
 SG_ HVP_pyroAoutHighsideSwitchIgh1 m5 : 32|16@1+ (0.001,0) [0|0] "" Vector__XXX
 SG_ HVP_pyroAoutLeakIgh1 m2 : 32|16@1+ (0.001,0) [0|0] "" Vector__XXX
 SG_ HVP_pyroAoutLowsideSwitchIgl1 m6 : 32|16@1+ (0.001,0) [0|0] "" Vector__XXX
 SG_ HVP_pyroAoutRm m3 : 32|16@1+ (0.001,0) [0|0] "" Vector__XXX
 SG_ HVP_pyroAoutSquibResIgh1 m4 : 32|16@1+ (0.001,0) [0|0] "" Vector__XXX
 SG_ HVP_pyroAoutVst1 m0 : 32|16@1+ (0.001,0) [0|0] "" Vector__XXX
 SG_ HVP_pyroAoutEr2 m1 : 48|16@1+ (0.001,0) [0|0] "" Vector__XXX
 SG_ HVP_pyroAoutGnd m5 : 48|16@1+ (0.001,0) [0|0] "" Vector__XXX
 SG_ HVP_pyroAoutLeakIgl1 m2 : 48|16@1+ (0.001,0) [0|0] "" Vector__XXX
 SG_ HVP_pyroAoutRref m3 : 48|16@1+ (0.001,0) [0|0] "" Vector__XXX
 SG_ HVP_pyroAoutSquibResIgl1 m4 : 48|16@1+ (0.001,0) [0|0] "" Vector__XXX
 SG_ HVP_pyroAoutVst2 m0 : 48|16@1+ (0.001,0) [0|0] "" Vector__XXX

BO_ 1931 EPBL_xcpResponse: 12 Vector__XXX
 SG_ EPBL_xcpResponse : 7|64@0+ (1,0) [0|0] "" Vector__XXX

BO_ 1932 EPBR_xcpResponse: 12 Vector__XXX
 SG_ EPBR_xcpResponse : 7|64@0+ (1,0) [0|0] "" Vector__XXX

BO_ 1940 PMF_xcpResponse: 12 Vector__XXX
 SG_ PMF_xcpResponseData : 7|64@0+ (1,0) [0|0] "" Vector__XXX

BO_ 1942 DIF_xcpResponse: 12 Vector__XXX
 SG_ DIF_xcpResponseData : 7|64@0+ (1,0) [0|0] "" Vector__XXX

BO_ 1943 EPBR_LVPowerState: 8 Vector__XXX
 SG_ EPBR_rcmLVState : 0|2@1+ (1,0) [0|0] "" Vector__XXX
 SG_ EPBR_tunerLVState : 2|2@1+ (1,0) [0|0] "" Vector__XXX
 SG_ EPBR_parkLVState : 4|2@1+ (1,0) [0|0] "" Vector__XXX
 SG_ EPBR_premAudioLVState : 6|2@1+ (1,0) [0|0] "" Vector__XXX
 SG_ EPBR_ptcLVState : 8|2@1+ (1,0) [0|0] "" Vector__XXX
 SG_ EPBR_vehiclePowerStateDBG : 10|2@1+ (1,0) [0|0] "" Vector__XXX
 SG_ EPBR_interiorCameraLedLVState : 12|2@1+ (1,0) [0|0] "" Vector__XXX
 SG_ EPBR_seat2RControllerLVState : 16|2@1+ (1,0) [0|0] "" Vector__XXX
 SG_ EPBR_LVPowerStateCounter : 20|4@1+ (1,0) [0|0] "" Vector__XXX
 SG_ EPBR_LVPowerStateChecksum : 24|8@1+ (1,0) [0|0] "" Vector__XXX

BO_ 1944 EPBL_remoteADC: 8 Vector__XXX
 SG_ EPBL_remoteADCIndex M : 0|3@1+ (1,0) [0|0] "" Vector__XXX
 SG_ EPBL_PCBATemp m4 : 3|10@1+ (0.0009775171065493646,0) [0|0] "" Vector__XXX
 SG_ EPBL_efuseContinousMonitor m1 : 3|10@1+ (0.017595307917888565,0) [0|0] "" Vector__XXX
 SG_ EPBL_frontCushionTemp m3 : 3|10@1+ (0.0009775171065493646,0) [0|0] "" Vector__XXX
 SG_ EPBL_seatFrontBackRestUpMonitor m2 : 3|10@1+ (0.017595307917888565,0) [0|0] "" Vector__XXX
 SG_ EPBL_trailerAuxMonitor m6 : 3|10@1+ (0.017595307917888565,0) [0|0] "" Vector__XXX
 SG_ EPBL_windowLiftFrontUpMonitor m0 : 3|10@1+ (0.017595307917888565,0) [0|0] "" Vector__XXX
 SG_ EPBL_2ndRowRightCushionTemp m3 : 13|10@1+ (0.0009775171065493646,0) [0|0] "" Vector__XXX
 SG_ EPBL_BLEMonitor m4 : 13|10@1+ (0.017595307917888565,0) [0|0] "" Vector__XXX
 SG_ EPBL_efuseNonContinuousMonitor m1 : 13|10@1+ (0.017595307917888565,0) [0|0] "" Vector__XXX
 SG_ EPBL_mirrorDimMonitor m2 : 13|10@1+ (0.004887585532746823,0) [0|0] "" Vector__XXX
 SG_ EPBL_windowLiftRearDownMonitor m0 : 13|10@1+ (0.017595307917888565,0) [0|0] "" Vector__XXX
 SG_ EPBL_2ndRowCenterCushionTemp m3 : 24|10@1+ (0.0009775171065493646,0) [0|0] "" Vector__XXX
 SG_ EPBL_accessoryFeedAlwaysOnMonitor m2 : 24|10@1+ (0.017595307917888565,0) [0|0] "" Vector__XXX
 SG_ EPBL_liftGateStrutCloseMonitor m1 : 24|10@1+ (0.017595307917888565,0) [0|0] "" Vector__XXX
 SG_ EPBL_seatFrontLiftUpMonitor m0 : 24|10@1+ (0.017595307917888565,0) [0|0] "" Vector__XXX
 SG_ EPBL_securityControllerMonitor m4 : 24|10@1+ (0.017595307917888565,0) [0|0] "" Vector__XXX
 SG_ EPBL_2ndRowLeftCushionTemp m3 : 34|10@1+ (0.0009775171065493646,0) [0|0] "" Vector__XXX
 SG_ EPBL_chargePortMonitor m4 : 34|10@1+ (0.017595307917888565,0) [0|0] "" Vector__XXX
 SG_ EPBL_liftGateStrutOpenMonitor m1 : 34|10@1+ (0.017595307917888565,0) [0|0] "" Vector__XXX
 SG_ EPBL_seatFrontTiltUpMonitor m0 : 34|10@1+ (0.017595307917888565,0) [0|0] "" Vector__XXX
 SG_ EPBL_steeringColumnUpMonitor m2 : 34|10@1+ (0.017595307917888565,0) [0|0] "" Vector__XXX
 SG_ EPBL_remoteADCCounter : 52|4@1+ (1,0) [0|0] "" Vector__XXX
 SG_ EPBL_remoteADCChecksum : 56|8@1+ (1,0) [0|0] "" Vector__XXX

BO_ 1945 DI_xcpResponse: 12 Vector__XXX
 SG_ DI_xcpResponseData : 7|64@0+ (1,0) [0|0] "" Vector__XXX

BO_ 1947 XCP_epblRequest: 12 Vector__XXX
 SG_ XCP_epblRequest : 7|64@0+ (1,0) [0|0] "" Vector__XXX

BO_ 1948 XCP_epbrRequest: 12 Vector__XXX
 SG_ XCP_epbrRequest : 7|64@0+ (1,0) [0|0] "" Vector__XXX

BO_ 1949 V2G_evseLogData: 8 Vector__XXX
 SG_ V2G_evseLogDataSelect M : 0|5@1+ (1,0) [0|0] "" Vector__XXX
 SG_ V2G_currDemRes_isoState_val m13 : 5|1@1+ (1,0) [0|0] "" Vector__XXX
 SG_ V2G_currDemRes_respCode m11 : 5|5@1+ (1,0) [0|0] "" Vector__XXX
 SG_ V2G_suppAppProtocolRes_respCode m0 : 5|2@1+ (1,0) [0|0] "" Vector__XXX
 SG_ V2G_cableCheckRes_respCode m8 : 8|5@1+ (1,0) [0|0] "" Vector__XXX
 SG_ V2G_chargingStatusRes_respCode m12 : 8|5@1+ (1,0) [0|0] "" Vector__XXX
 SG_ V2G_chgParamRes_respCode m7 : 8|5@1+ (1,0) [0|0] "" Vector__XXX
 SG_ V2G_contractAuthRes_respCode m6 : 8|5@1+ (1,0) [0|0] "" Vector__XXX
 SG_ V2G_paymentDetailsRes_respCode m5 : 8|5@1+ (1,0) [0|0] "" Vector__XXX
 SG_ V2G_powerDelEndRes_respCode m13 : 8|5@1+ (1,0) [0|0] "" Vector__XXX
 SG_ V2G_powerDelStartRes_respCode m10 : 8|5@1+ (1,0) [0|0] "" Vector__XXX
 SG_ V2G_prechargeRes_respCode m9 : 8|5@1+ (1,0) [0|0] "" Vector__XXX
 SG_ V2G_serviceDetailRes_respCode m3 : 8|5@1+ (1,0) [0|0] "" Vector__XXX
 SG_ V2G_serviceDiscoveryRes_respCode m2 : 8|5@1+ (1,0) [0|0] "" Vector__XXX
 SG_ V2G_servicePaymntSelRes_respCode m4 : 8|5@1+ (1,0) [0|0] "" Vector__XXX
 SG_ V2G_sessionSetupRes_respCode m1 : 8|5@1+ (1,0) [0|0] "" Vector__XXX
 SG_ V2G_sessionStopRes_respCode m14 : 8|5@1+ (1,0) [0|0] "" Vector__XXX
 SG_ V2G_suppAppProtocolRes_schemaId m0 : 8|8@1+ (1,0) [0|0] "" Vector__XXX
 SG_ V2G_currDemRes_evseStatus m11 : 10|4@1+ (1,0) [0|0] "" Vector__XXX
 SG_ V2G_cableCheckRes_finished m8 : 13|1@1+ (1,0) [0|0] "" Vector__XXX
 SG_ V2G_chgParamRes_finished m7 : 13|1@1+ (1,0) [0|0] "" Vector__XXX
 SG_ V2G_contractAuthRes_finished m6 : 13|1@1+ (1,0) [0|0] "" Vector__XXX
 SG_ V2G_serviceDiscRes_extPayAvail m2 : 13|1@1+ (1,0) [0|0] "" Vector__XXX
 SG_ V2G_chgParamRes_evseStatus m7 : 14|4@1+ (1,0) [0|0] "" Vector__XXX
 SG_ V2G_currDemRes_outputV m11 : 14|10@1+ (1.171875,0) [0|0] "" Vector__XXX
 SG_ V2G_serviceDiscRes_pncAvail m2 : 14|1@1+ (1,0) [0|0] "" Vector__XXX
 SG_ V2G_serviceDiscRes_evChgAvail m2 : 15|1@1+ (1,0) [0|0] "" Vector__XXX
 SG_ V2G_cableCheckRes_evseStatus m8 : 16|4@1+ (1,0) [0|0] "" Vector__XXX
 SG_ V2G_chargingStatusRes_maxI m12 : 16|7@1+ (1,0) [0|0] "" Vector__XXX
 SG_ V2G_powerDelEndRes_evseStatus m13 : 16|4@1+ (1,0) [0|0] "" Vector__XXX
 SG_ V2G_powerDelStartRes_evseStatus m10 : 16|4@1+ (1,0) [0|0] "" Vector__XXX
 SG_ V2G_prechargeRes_evseStatus m9 : 16|4@1+ (1,0) [0|0] "" Vector__XXX
 SG_ V2G_serviceDiscRes_dcExtended m2 : 16|1@1+ (1,0) [0|0] "" Vector__XXX
 SG_ V2G_chgParamRes_evseMaxILim m7 : 18|8@1+ (7.032,0) [0|0] "" Vector__XXX
 SG_ V2G_cableCheckRes_isoState m8 : 20|3@1+ (1,0) [0|0] "" Vector__XXX
 SG_ V2G_prechargeRes_outputV m9 : 20|10@1+ (1.171875,0) [0|0] "" Vector__XXX
 SG_ V2G_pwrDelEndRes_isoState m13 : 20|3@1+ (1,0) [0|0] "" Vector__XXX
 SG_ V2G_pwrDelStartRes_isoState m10 : 20|3@1+ (1,0) [0|0] "" Vector__XXX
 SG_ V2G_cableCheckRes_isoState_val m8 : 23|1@1+ (1,0) [0|0] "" Vector__XXX
 SG_ V2G_chargingStatusRes_maxI_val m12 : 23|1@1+ (1,0) [0|0] "" Vector__XXX
 SG_ V2G_pwrDelEndRes_isoState_val m13 : 23|1@1+ (1,0) [0|0] "" Vector__XXX
 SG_ V2G_pwrDelStartRes_isoState_val m10 : 23|1@1+ (1,0) [0|0] "" Vector__XXX
 SG_ V2G_chargingStatusRes_rcd m12 : 24|1@1+ (1,0) [0|0] "" Vector__XXX
 SG_ V2G_currDemRes_outputI m11 : 24|10@1+ (1.7578125,0) [0|0] "" Vector__XXX
 SG_ V2G_chgParamRes_evseMaxVLim m7 : 26|8@1+ (4.688,0) [0|0] "" Vector__XXX
 SG_ V2G_prechargeRes_isoState m9 : 32|3@1+ (1,0) [0|0] "" Vector__XXX
 SG_ V2G_chgParamRes_evseMinILim m7 : 34|8@1+ (7.032,0) [0|0] "" Vector__XXX
 SG_ V2G_currDemRes_evseMaxILim m11 : 34|8@1+ (7.032,0) [0|0] "" Vector__XXX
 SG_ V2G_prechargeRes_isoState_val m9 : 35|1@1+ (1,0) [0|0] "" Vector__XXX
 SG_ V2G_chgParamRes_evseMinVLim m7 : 42|8@1+ (4.688,0) [0|0] "" Vector__XXX
 SG_ V2G_currDemRes_evseMaxILim_val m11 : 42|1@1+ (1,0) [0|0] "" Vector__XXX
 SG_ V2G_currDemRes_evseMaxVLim m11 : 43|8@1+ (4.688,0) [0|0] "" Vector__XXX
 SG_ V2G_chgParamRes_evseMaxPowerLim m7 : 50|8@1+ (5.9766,0) [0|0] "" Vector__XXX
 SG_ V2G_currDemRes_evseMaxVLim_val m11 : 51|1@1+ (1,0) [0|0] "" Vector__XXX
 SG_ V2G_currDemRes_evseMaxPowerLim m11 : 52|8@1+ (5.9766,0) [0|0] "" Vector__XXX
 SG_ V2G_chgParamRes_evseMaxPower_val m7 : 58|1@1+ (1,0) [0|0] "" Vector__XXX
 SG_ V2G_chgParamRes_isoState m7 : 59|3@1+ (1,0) [0|0] "" Vector__XXX
 SG_ V2G_currDemRes_evseMaxPower_val m11 : 60|1@1+ (1,0) [0|0] "" Vector__XXX
 SG_ V2G_currDemRes_isoState m11 : 61|3@1+ (1,0) [0|0] "" Vector__XXX
 SG_ V2G_chgParamRes_isoState_val m7 : 62|1@1+ (1,0) [0|0] "" Vector__XXX

BO_ 1951 ADSP_audioVisualizer: 8 Vector__XXX
 SG_ ADSP_audioVisualizerBrightness : 0|8@1+ (1,0) [0|0] "" Vector__XXX

BO_ 1960 EPBR_debugOutput: 8 Vector__XXX
 SG_ EPBR_debugOutputIndex M : 0|2@1+ (1,0) [0|0] "" Vector__XXX
 SG_ EPBR_12VFilt_SW m0 : 2|9@1+ (0.043549408784,0) [0|0] "" Vector__XXX
 SG_ EPBR_limpToDecelTimer m2 : 2|10@1+ (1,0) [0|0] "" Vector__XXX
 SG_ EPBR_pid_uP m1 : 2|10@1- (0.2,0) [0|0] "" Vector__XXX
 SG_ EPBR_nvFilt m0 : 11|9@1+ (0.043549408784,0) [0|0] "" Vector__XXX
 SG_ EPBR_emergencyOperationMode m2 : 12|2@1+ (1,0) [0|0] "" Vector__XXX
 SG_ EPBR_pid_uI m1 : 12|10@1- (0.2,0) [0|0] "" Vector__XXX
 SG_ EPBR_dynamicManagerReady m2 : 14|1@1+ (1,0) [0|0] "" Vector__XXX
 SG_ EPBR_driverLockedOut m2 : 15|1@1+ (1,0) [0|0] "" Vector__XXX
 SG_ EPBR_currentOffset m2 : 16|12@1+ (0.016997132,-37.55274262) [0|0] "" Vector__XXX
 SG_ EPBR_pvFilt m0 : 20|9@1+ (0.043549408784,0) [0|0] "" Vector__XXX
 SG_ EPBR_pid_duty m1 : 22|10@1- (0.2,0) [0|0] "" Vector__XXX
 SG_ EPBR_filteredCurrentPeak m2 : 28|12@1+ (0.01,0) [0|0] "" Vector__XXX
 SG_ EPBR_caliperState m0 : 29|3@1+ (1,0) [0|0] "" Vector__XXX
 SG_ EPBR_nFault m0 : 32|1@1+ (1,0) [0|0] "" Vector__XXX
 SG_ EPBR_ramp m1 : 32|8@1+ (0.392157,0) [0|0] "" Vector__XXX
 SG_ EPBR_oocViolation m0 : 33|1@1+ (1,0) [0|0] "" Vector__XXX
 SG_ EPBR_atEndStop m0 : 34|1@1+ (1,0) [0|0] "" Vector__XXX
 SG_ EPBR_currentVariance m0 : 35|14@1- (0.0007629394535064697,0) [0|0] "" Vector__XXX
 SG_ EPBR_lockoutOutContactor m2 : 40|1@1+ (1,0) [0|0] "" Vector__XXX
 SG_ EPBR_pid_error m1 : 40|12@1+ (0.016997132,-37.55274262) [0|0] "" Vector__XXX
 SG_ EPBR_lockoutCmdContactor m2 : 41|1@1+ (1,0) [0|0] "" Vector__XXX
 SG_ EPBR_lockoutOutputHVC m2 : 42|1@1+ (1,0) [0|0] "" Vector__XXX
 SG_ EPBR_lockoutCommandHVC m2 : 43|1@1+ (1,0) [0|0] "" Vector__XXX
 SG_ EPBR_brakeDiscWipeAccumul m2 : 48|8@1+ (1,0) [0|0] "" Vector__XXX
 SG_ EPBR_lockoutUnlockCount m0 : 49|6@1+ (1,0) [0|0] "" Vector__XXX
 SG_ EPBR_12VFilt m1 : 52|9@1+ (0.043549408784,0) [0|0] "" Vector__XXX
 SG_ EPBR_esmCaliperRequest m0 : 55|3@1+ (1,0) [0|0] "" Vector__XXX
 SG_ EPBR_brakePressHeld m0 : 58|1@1+ (1,0) [0|0] "" Vector__XXX
 SG_ EPBR_epbOpenUnableToPark m0 : 59|1@1+ (1,0) [0|0] "" Vector__XXX
 SG_ EPBR_slopeParkable m0 : 60|1@1+ (1,0) [0|0] "" Vector__XXX
 SG_ EPBR_driverIsLeavingDisabled m0 : 61|1@1+ (1,0) [0|0] "" Vector__XXX
 SG_ EPBR_uiNotAvailable m0 : 62|1@1+ (1,0) [0|0] "" Vector__XXX

BO_ 1962 HVP_debugMessage: 8 Vector__XXX
 SG_ HVP_debugMessageMultiplexer M : 0|4@1+ (1,0) [0|0] "" Vector__XXX
 SG_ HVP_bmbStaleFrameRate m8 : 4|10@1+ (0.1,0) [0|0] "" Vector__XXX
 SG_ HVP_ecuLogUploadRequest m1 : 4|2@1+ (1,0) [0|0] "" Vector__XXX
 SG_ HVP_fcContCoilCurrent m4 : 4|12@1+ (0.1,0) [0|0] "" Vector__XXX
 SG_ HVP_gpioPassivePyroDepl m0 : 4|1@1+ (1,0) [0|0] "" Vector__XXX
 SG_ HVP_packContVoltage m2 : 4|12@1+ (0.1,0) [0|0] "" Vector__XXX
 SG_ HVP_passivePyroRefVoltageMax m5 : 4|10@1+ (0.001,0.7) [0|0] "" Vector__XXX
 SG_ HVP_shuntAuxCurrentDbg m6 : 4|16@1- (0.1,0) [0|0] "" Vector__XXX
 SG_ HVP_shuntCompensationMode m3 : 4|2@1+ (1,0) [0|0] "" Vector__XXX
 SG_ HVP_gpioPyroIsoEn m0 : 5|1@1+ (1,0) [0|0] "" Vector__XXX
 SG_ HVP_gpioCpFaultIn m0 : 6|1@1+ (1,0) [0|0] "" Vector__XXX
 SG_ HVP_gpioPackContPowerEn m0 : 7|1@1+ (1,0) [0|0] "" Vector__XXX
 SG_ HVP_100HzTask_avgExecTime m11 : 8|16@1+ (10,0) [0|0] "" Vector__XXX
 SG_ HVP_10HzTask_maxExecTime m10 : 8|16@1+ (10,0) [0|0] "" Vector__XXX
 SG_ HVP_1HzTask_maxExecTime m9 : 8|16@1+ (10,0) [0|0] "" Vector__XXX
 SG_ HVP_bmbStaleFrameCount m12 : 8|16@1+ (1,0) [0|0] "" Vector__XXX
 SG_ HVP_dcLinkNegativeV m3 : 8|16@1- (0.1,0) [0|0] "" Vector__XXX
 SG_ HVP_dcLinkVoltage m1 : 8|16@1- (0.1,0) [0|0] "" Vector__XXX
 SG_ HVP_gpioHvCablesOk m0 : 8|1@1+ (1,0) [0|0] "" Vector__XXX
 SG_ HVP_shuntCurrentRawDbg m7 : 8|16@1- (0.1,0) [0|0] "" Vector__XXX
 SG_ HVP_gpioHvpSelfEnable m0 : 9|1@1+ (1,0) [0|0] "" Vector__XXX
 SG_ HVP_gpioLed m0 : 10|1@1+ (1,0) [0|0] "" Vector__XXX
 SG_ HVP_gpioCrashSignal m0 : 11|1@1+ (1,0) [0|0] "" Vector__XXX
 SG_ HVP_gpioShuntDataReady m0 : 12|1@1+ (1,0) [0|0] "" Vector__XXX
 SG_ HVP_gpioFcContPosAux m0 : 13|1@1+ (1,0) [0|0] "" Vector__XXX
 SG_ HVP_bmbCrcFailedFrameRate m8 : 14|10@1+ (0.1,0) [0|0] "" Vector__XXX
 SG_ HVP_gpioFcContNegAux m0 : 14|1@1+ (1,0) [0|0] "" Vector__XXX
 SG_ HVP_passivePyroRefVoltageMin m5 : 14|10@1+ (0.001,0.7) [0|0] "" Vector__XXX
 SG_ HVP_gpioBmsEout m0 : 15|1@1+ (1,0) [0|0] "" Vector__XXX
 SG_ HVP_fcContVoltage m4 : 16|12@1+ (0.1,0) [0|0] "" Vector__XXX
 SG_ HVP_gpioCpFaultOut m0 : 16|1@1+ (1,0) [0|0] "" Vector__XXX
 SG_ HVP_packNegativeV m2 : 16|16@1- (0.1,0) [0|0] "" Vector__XXX
 SG_ HVP_gpioPyroPor m0 : 17|1@1+ (1,0) [0|0] "" Vector__XXX
 SG_ HVP_gpioShuntEn m0 : 18|1@1+ (1,0) [0|0] "" Vector__XXX
 SG_ HVP_gpioHvpVerEn m0 : 19|1@1+ (1,0) [0|0] "" Vector__XXX
 SG_ HVP_gpioFcContFlywheelEnable m0 : 20|1@1+ (1,0) [0|0] "" Vector__XXX
 SG_ HVP_shuntBarTempDbg m6 : 20|16@1- (0.01,0) [0|0] "" Vector__XXX
 SG_ HVP_gpioCpLatchEnable m0 : 21|1@1+ (1,0) [0|0] "" Vector__XXX
 SG_ HVP_gpioFcContPowerEnable m0 : 22|1@1+ (1,0) [0|0] "" Vector__XXX
 SG_ HVP_gpioHvilEnable m0 : 23|1@1+ (1,0) [0|0] "" Vector__XXX
 SG_ HVP_10HzTask_avgExecTime m10 : 24|16@1+ (10,0) [0|0] "" Vector__XXX
 SG_ HVP_1HzTask_avgExecTime m9 : 24|16@1+ (10,0) [0|0] "" Vector__XXX
 SG_ HVP_1kHzTask_cpuUsage m11 : 24|7@1+ (1,0) [0|0] "" Vector__XXX
 SG_ HVP_bmbCrcFailedFrameCount m12 : 24|16@1+ (1,0) [0|0] "" Vector__XXX
 SG_ HVP_bmbSnaFrameRate m8 : 24|10@1+ (0.1,0) [0|0] "" Vector__XXX
 SG_ HVP_dcLinkPositiveV m3 : 24|16@1- (0.1,0) [0|0] "" Vector__XXX
 SG_ HVP_gpioPortSelSpiRdy m0 : 24|1@1+ (1,0) [0|0] "" Vector__XXX
 SG_ HVP_packContCoilCurrent m5 : 24|12@1+ (0.1,0) [0|0] "" Vector__XXX
 SG_ HVP_packVoltage m1 : 24|16@1- (0.1,0) [0|0] "" Vector__XXX
 SG_ HVP_shuntCurrentDbg m7 : 24|16@1- (0.1,0) [0|0] "" Vector__XXX
 SG_ HVP_gpioPyroUnlock m0 : 25|1@1+ (1,0) [0|0] "" Vector__XXX
 SG_ HVP_hvp1v5Ref m0 : 26|12@1+ (0.1,0) [0|0] "" Vector__XXX
 SG_ HVP_hvilInVoltage m4 : 28|12@1+ (0.1,0) [0|0] "" Vector__XXX
 SG_ HVP_1kHzTask_maxExecTime m11 : 32|16@1+ (10,0) [0|0] "" Vector__XXX
 SG_ HVP_packPositiveV m2 : 32|16@1- (0.1,0) [0|0] "" Vector__XXX
 SG_ HVP_cpuLoad m8 : 34|7@1+ (1,0) [0|0] "" Vector__XXX
 SG_ HVP_battery12V m5 : 36|12@1+ (0.1,0) [0|0] "" Vector__XXX
 SG_ HVP_shuntAsicTempDbg m6 : 36|16@1- (0.01,0) [0|0] "" Vector__XXX
 SG_ HVP_packCurrentMia m0 : 38|1@1+ (1,0) [0|0] "" Vector__XXX
 SG_ HVP_auxCurrentMia m0 : 39|1@1+ (1,0) [0|0] "" Vector__XXX
 SG_ HVP_100HzTask_cpuUsage m10 : 40|7@1+ (1,0) [0|0] "" Vector__XXX
 SG_ HVP_10HzTask_cpuUsage m9 : 40|7@1+ (1,0) [0|0] "" Vector__XXX
 SG_ HVP_bmbSnaFrameCount m12 : 40|16@1+ (1,0) [0|0] "" Vector__XXX
 SG_ HVP_currentSenseMia m0 : 40|1@1+ (1,0) [0|0] "" Vector__XXX
 SG_ HVP_fcLinkNegativeV m3 : 40|16@1- (0.1,0) [0|0] "" Vector__XXX
 SG_ HVP_fcLinkVoltage m1 : 40|16@1- (0.1,0) [0|0] "" Vector__XXX
 SG_ HVP_hvilOutVoltage m4 : 40|12@1+ (0.1,0) [0|0] "" Vector__XXX
 SG_ HVP_shuntCurrentSampleDbg m7 : 40|16@1+ (1,0) [0|0] "" Vector__XXX
 SG_ HVP_1HzTask_cpuUsage m8 : 41|7@1+ (1,0) [0|0] "" Vector__XXX
 SG_ HVP_passivePyroRefVoltageIrrational m0 : 41|1@1+ (1,0) [0|0] "" Vector__XXX
 SG_ HVP_shuntThermistorMissing m0 : 42|1@1+ (1,0) [0|0] "" Vector__XXX
 SG_ HVP_shuntThermistorExpected m0 : 43|1@1+ (1,0) [0|0] "" Vector__XXX
 SG_ HVP_shuntThermistorMia m0 : 44|1@1+ (1,0) [0|0] "" Vector__XXX
 SG_ HVP_shuntUnexpectedThermistor m0 : 45|1@1+ (1,0) [0|0] "" Vector__XXX
 SG_ HVP_shuntHwMia m0 : 46|1@1+ (1,0) [0|0] "" Vector__XXX
 SG_ HVP_shuntCurrentIrrational m0 : 47|1@1+ (1,0) [0|0] "" Vector__XXX
 SG_ HVP_100HzTask_maxExecTime m10 : 48|16@1+ (10,0) [0|0] "" Vector__XXX
 SG_ HVP_1kHzTask_avgExecTime m11 : 48|16@1+ (10,0) [0|0] "" Vector__XXX
 SG_ HVP_bmbHighPrioTask_stackUsage m8 : 48|7@1+ (1,0) [0|0] "" Vector__XXX
 SG_ HVP_bmbTotalFrameCount m9 : 48|16@1+ (1,0) [0|0] "" Vector__XXX
 SG_ HVP_fcLinkPositiveV m5 : 48|16@1- (0.1,0) [0|0] "" Vector__XXX
 SG_ HVP_pyroAnalog m2 : 48|12@1+ (0.1,0) [0|0] "" Vector__XXX
 SG_ HVP_shuntAsicTCompActive m0 : 48|1@1+ (1,0) [0|0] "" Vector__XXX
 SG_ HVP_1kHzTask_stackUsage m0 : 49|7@1+ (1,0) [0|0] "" Vector__XXX
 SG_ HVP_shuntAuxCurrentStatus m6 : 52|2@1+ (1,0) [0|0] "" Vector__XXX
 SG_ HVP_shuntAsicTempStatus m6 : 54|2@1+ (1,0) [0|0] "" Vector__XXX
 SG_ HVP_bmbTask_stackUsage m8 : 55|7@1+ (1,0) [0|0] "" Vector__XXX
 SG_ HVP_100HzTask_stackUsage m0 : 56|7@1+ (1,0) [0|0] "" Vector__XXX
 SG_ HVP_10HzTask_stackUsage m1 : 56|7@1+ (1,0) [0|0] "" Vector__XXX
 SG_ HVP_1HzTask_stackUsage m3 : 56|7@1+ (1,0) [0|0] "" Vector__XXX
 SG_ HVP_shuntCurrentGainInvalidDbg m7 : 56|1@1+ (1,0) [0|0] "" Vector__XXX
 SG_ HVP_shuntGainInvalidCountDbg m4 : 56|8@1+ (1,0) [0|0] "" Vector__XXX
 SG_ HVP_shuntTask_stackUsage m12 : 56|7@1+ (1,0) [0|0] "" Vector__XXX
 SG_ HVP_udsTask_stackUsage m6 : 56|7@1+ (1,0) [0|0] "" Vector__XXX
 SG_ HVP_canTxRxTask_stackUsage m7 : 57|7@1+ (1,0) [0|0] "" Vector__XXX
 SG_ HVP_shuntSetTCRCoeffA m2 : 60|1@1+ (1,0) [0|0] "" Vector__XXX
 SG_ HVP_shuntSetTCRCoeffB m2 : 61|1@1+ (1,0) [0|0] "" Vector__XXX
 SG_ HVP_shuntSetTCRCoeffC m2 : 62|1@1+ (1,0) [0|0] "" Vector__XXX
 SG_ HVP_shuntSetTCRCoeffD m2 : 63|1@1+ (1,0) [0|0] "" Vector__XXX

BO_ 1970 DBG_bmsServiceReq: 8 Vector__XXX
 SG_ DBG_bmsDebugEnableAll : 0|1@1+ (1,0) [0|0] "" Vector__XXX

BO_ 1973 PM_itpmsDisplay: 8 Vector__XXX
 SG_ PM_itpmsDisplaySelector M : 0|2@1+ (1,0) [0|0] "" Vector__XXX
 SG_ PM_fusedPressureEstimateFrL m2 : 2|9@1+ (0.008,0) [0|0] "" Vector__XXX
 SG_ PM_fusedPressureEstimateReL m3 : 2|9@1+ (0.008,0) [0|0] "" Vector__XXX
 SG_ PM_indirectTPMSTellTale m0 : 2|2@1+ (1,0) [0|0] "" Vector__XXX
 SG_ PM_indirectTPMSDisplayState m0 : 4|2@1+ (1,0) [0|0] "" Vector__XXX
 SG_ PM_indirectTPMSDisplayProgress m0 : 8|5@1+ (0.05,0) [0|0] "" Vector__XXX
 SG_ PM_indirectTPMSRecommendedColdPressureFront m1 : 8|8@1+ (0.025,0) [0|0] "" Vector__XXX
 SG_ PM_fusedPressureEstimateFrR m2 : 11|9@1+ (0.008,0) [0|0] "" Vector__XXX
 SG_ PM_fusedPressureEstimateReR m3 : 11|9@1+ (0.008,0) [0|0] "" Vector__XXX
 SG_ PM_indirectTPMSDisplayWarningIndicatorFL m0 : 13|2@1+ (1,0) [0|0] "" Vector__XXX
 SG_ PM_indirectTPMSDisplayWarningIndicatorFR m0 : 16|2@1+ (1,0) [0|0] "" Vector__XXX
 SG_ PM_indirectTPMSRecommendedColdPressureRear m1 : 16|8@1+ (0.025,0) [0|0] "" Vector__XXX
 SG_ PM_indirectTPMSDisplayWarningIndicatorRL m0 : 18|2@1+ (1,0) [0|0] "" Vector__XXX
 SG_ PM_indirectTPMSDisplayWarningIndicatorRR m0 : 20|2@1+ (1,0) [0|0] "" Vector__XXX

BO_ 1976 EPBR_remoteADC: 8 Vector__XXX
 SG_ EPBR_remoteADCIndex M : 0|3@1+ (1,0) [0|0] "" Vector__XXX
 SG_ EPBR_BLEBPillarMonitor m4 : 3|10@1+ (0.017595307917888565,0) [0|0] "" Vector__XXX
 SG_ EPBR_efuseContinousMonitor m1 : 3|10@1+ (0.017595307917888565,0) [0|0] "" Vector__XXX
 SG_ EPBR_hvacRightVentDuctTemp m3 : 3|10@1+ (0.0009775171065493646,0) [0|0] "" Vector__XXX
 SG_ EPBR_mirrorDimMonitor m2 : 3|10@1+ (0.004887585532746823,0) [0|0] "" Vector__XXX
 SG_ EPBR_rearGlassHeaterCurrent m5 : 3|10@1+ (0.068359375,0) [0|0] "" Vector__XXX
 SG_ EPBR_windowLiftFrontDownMonitor m0 : 3|10@1+ (0.017595307917888565,0) [0|0] "" Vector__XXX
 SG_ EPBR_efuseNonContinuousMonitor m1 : 13|10@1+ (0.017595307917888565,0) [0|0] "" Vector__XXX
 SG_ EPBR_frontCushionTemp m5 : 13|10@1+ (0.0009775171065493646,0) [0|0] "" Vector__XXX
 SG_ EPBR_hvContactorsMonitor m4 : 13|10@1+ (0.017595307917888565,0) [0|0] "" Vector__XXX
 SG_ EPBR_hvacLeftVentDuctTemp m3 : 13|10@1+ (0.0009775171065493646,0) [0|0] "" Vector__XXX
 SG_ EPBR_seatFrontBackRestUpMonitor m2 : 13|10@1+ (0.017595307917888565,0) [0|0] "" Vector__XXX
 SG_ EPBR_windowLiftRearUpMonitor m0 : 13|10@1+ (0.017595307917888565,0) [0|0] "" Vector__XXX
 SG_ EPBR_2rSeatOutboardFloorSensor m5 : 24|10@1+ (0.004887585532746823,0) [0|0] "" Vector__XXX
 SG_ EPBR_ecallStandbyPowerMonitor m2 : 24|10@1+ (0.02932551319648094,0) [0|0] "" Vector__XXX
 SG_ EPBR_gloveBoxLatchUpstreamI m4 : 24|10@1+ (0.019550342130987292,0) [0|0] "" Vector__XXX
 SG_ EPBR_hvacRightLowerVentDuctTemp m3 : 24|10@1+ (0.0009775171065493646,0) [0|0] "" Vector__XXX
 SG_ EPBR_seatFrontLiftUpMonitor m0 : 24|10@1+ (0.017595307917888565,0) [0|0] "" Vector__XXX
 SG_ EPBR_seatFrontTrackForwardMonitor m1 : 24|10@1+ (0.017595307917888565,0) [0|0] "" Vector__XXX
 SG_ EPBR_2rSeatInboardFloorSensor m5 : 34|10@1+ (0.004887585532746823,0) [0|0] "" Vector__XXX
 SG_ EPBR_PCBATemp m2 : 34|10@1+ (0.0009775171065493646,0) [0|0] "" Vector__XXX
 SG_ EPBR_gloveBoxReleaseMonitor m1 : 34|10@1+ (0.017595307917888565,0) [0|0] "" Vector__XXX
 SG_ EPBR_hvacLeftLowerVentDuctTemp m3 : 34|10@1+ (0.0009775171065493646,0) [0|0] "" Vector__XXX
 SG_ EPBR_premiumAmpCurrent m4 : 34|10@1+ (0.029296875,0) [0|0] "" Vector__XXX
 SG_ EPBR_seatFrontTiltUpMonitor m0 : 34|10@1+ (0.017595307917888565,0) [0|0] "" Vector__XXX
 SG_ EPBR_remoteADCCounter : 52|4@1+ (1,0) [0|0] "" Vector__XXX
 SG_ EPBR_remoteADCChecksum : 56|8@1+ (1,0) [0|0] "" Vector__XXX

BO_ 1980 HCMR_info: 8 Vector__XXX
 SG_ VC_hcmrInfoIndex M : 0|4@1+ (1,0) [0|0] "" Vector__XXX
 SG_ VC_hcmrBoost_OV m7 : 4|1@1+ (1,0) [0|0] "" Vector__XXX
 SG_ VC_hcmrFault_DRL_THERMAL m4 : 4|1@1+ (1,0) [0|0] "" Vector__XXX
 SG_ VC_hcmrFault_HB_THERMAL m2 : 4|1@1+ (1,0) [0|0] "" Vector__XXX
 SG_ VC_hcmrFault_LB_THERMAL m3 : 4|1@1+ (1,0) [0|0] "" Vector__XXX
 SG_ VC_hcmrFault_SM_THERMAL m5 : 4|1@1+ (1,0) [0|0] "" Vector__XXX
 SG_ VC_hcmrVoltage_HB m6 : 4|10@1+ (0.1,0) [0|0] "" Vector__XXX
 SG_ VC_hcmrBoost_BOOTUV m7 : 5|1@1+ (1,0) [0|0] "" Vector__XXX
 SG_ VC_hcmrFault_DRL_VBCKUVLO m4 : 5|1@1+ (1,0) [0|0] "" Vector__XXX
 SG_ VC_hcmrFault_HB_VBCKUVLO m2 : 5|1@1+ (1,0) [0|0] "" Vector__XXX
 SG_ VC_hcmrFault_LB_VBCKUVLO m3 : 5|1@1+ (1,0) [0|0] "" Vector__XXX
 SG_ VC_hcmrFault_SM_VBCKUVLO m5 : 5|1@1+ (1,0) [0|0] "" Vector__XXX
 SG_ VC_hcmrBoost_ILIM m7 : 6|1@1+ (1,0) [0|0] "" Vector__XXX
 SG_ VC_hcmrFault_DRL_SHORT m4 : 6|1@1+ (1,0) [0|0] "" Vector__XXX
 SG_ VC_hcmrFault_HB_SHORT m2 : 6|1@1+ (1,0) [0|0] "" Vector__XXX
 SG_ VC_hcmrFault_LB_SHORT m3 : 6|1@1+ (1,0) [0|0] "" Vector__XXX
 SG_ VC_hcmrFault_SM_SHORT m5 : 6|1@1+ (1,0) [0|0] "" Vector__XXX
 SG_ VC_hcmrBoost_ISPUV m7 : 7|1@1+ (1,0) [0|0] "" Vector__XXX
 SG_ VC_hcmrFault_DRL_COMPOV m4 : 7|1@1+ (1,0) [0|0] "" Vector__XXX
 SG_ VC_hcmrFault_HB_COMPOV m2 : 7|1@1+ (1,0) [0|0] "" Vector__XXX
 SG_ VC_hcmrFault_LB_COMPOV m3 : 7|1@1+ (1,0) [0|0] "" Vector__XXX
 SG_ VC_hcmrFault_SM_COMPOV m5 : 7|1@1+ (1,0) [0|0] "" Vector__XXX
 SG_ VC_hcmrFault_DRL_HSILIM m4 : 8|1@1+ (1,0) [0|0] "" Vector__XXX
 SG_ VC_hcmrFault_HB_HSILIM m2 : 8|1@1+ (1,0) [0|0] "" Vector__XXX
 SG_ VC_hcmrFault_LB_HSILIM m3 : 8|1@1+ (1,0) [0|0] "" Vector__XXX
 SG_ VC_hcmrFault_SM_HSILIM m5 : 8|1@1+ (1,0) [0|0] "" Vector__XXX
 SG_ VC_hcmrLowBeamHighBeamDeratingFactor m8 : 8|8@1+ (0.5,0) [0|0] "" Vector__XXX
 SG_ VC_infoHCMRAssemblyId m1 : 8|16@1+ (1,0) [0|0] "" Vector__XXX
 SG_ VC_infoHCMRBuildConfigId m0 : 8|16@1+ (1,0) [0|0] "" Vector__XXX
 SG_ VC_hcmrFault_DRL_LSILIM m4 : 9|1@1+ (1,0) [0|0] "" Vector__XXX
 SG_ VC_hcmrFault_HB_LSILIM m2 : 9|1@1+ (1,0) [0|0] "" Vector__XXX
 SG_ VC_hcmrFault_LB_LSILIM m3 : 9|1@1+ (1,0) [0|0] "" Vector__XXX
 SG_ VC_hcmrFault_SM_LSILIM m5 : 9|1@1+ (1,0) [0|0] "" Vector__XXX
 SG_ VC_hcmrFault_DRL_BOOTUV m4 : 10|1@1+ (1,0) [0|0] "" Vector__XXX
 SG_ VC_hcmrFault_HB_BOOTUV m2 : 10|1@1+ (1,0) [0|0] "" Vector__XXX
 SG_ VC_hcmrFault_LB_BOOTUV m3 : 10|1@1+ (1,0) [0|0] "" Vector__XXX
 SG_ VC_hcmrFault_SM_BOOTUV m5 : 10|1@1+ (1,0) [0|0] "" Vector__XXX
 SG_ VC_hcmrFault_DRL_TOFFMIN m4 : 11|1@1+ (1,0) [0|0] "" Vector__XXX
 SG_ VC_hcmrFault_HB_TOFFMIN m2 : 11|1@1+ (1,0) [0|0] "" Vector__XXX
 SG_ VC_hcmrFault_LB_TOFFMIN m3 : 11|1@1+ (1,0) [0|0] "" Vector__XXX
 SG_ VC_hcmrFault_SM_TOFFMIN m5 : 11|1@1+ (1,0) [0|0] "" Vector__XXX
 SG_ VC_hcmrFault_DRL_LEDUV m4 : 12|1@1+ (1,0) [0|0] "" Vector__XXX
 SG_ VC_hcmrFault_HB_LEDUV m2 : 12|1@1+ (1,0) [0|0] "" Vector__XXX
 SG_ VC_hcmrFault_LB_LEDUV m3 : 12|1@1+ (1,0) [0|0] "" Vector__XXX
 SG_ VC_hcmrFault_SM_LEDUV m5 : 12|1@1+ (1,0) [0|0] "" Vector__XXX
 SG_ VC_hcmrFault_DRL_LEDOV m4 : 13|1@1+ (1,0) [0|0] "" Vector__XXX
 SG_ VC_hcmrFault_HB_LEDOV m2 : 13|1@1+ (1,0) [0|0] "" Vector__XXX
 SG_ VC_hcmrFault_LB_LEDOV m3 : 13|1@1+ (1,0) [0|0] "" Vector__XXX
 SG_ VC_hcmrFault_SM_LEDOV m5 : 13|1@1+ (1,0) [0|0] "" Vector__XXX
 SG_ VC_hcmrFault_TURN_THERMAL m4 : 14|1@1+ (1,0) [0|0] "" Vector__XXX
 SG_ VC_hcmrVoltage_LB m6 : 14|10@1+ (0.1,0) [0|0] "" Vector__XXX
 SG_ VC_hcmrFault_TURN_VBCKUVLO m4 : 15|1@1+ (1,0) [0|0] "" Vector__XXX
 SG_ VC_hcmrDRLSideMarkerTurnDeratingFactor m8 : 16|8@1+ (0.5,0) [0|0] "" Vector__XXX
 SG_ VC_hcmrFault_TURN_SHORT m4 : 16|1@1+ (1,0) [0|0] "" Vector__XXX
 SG_ VC_hcmr_ic400_EEPROMWriteCount m2 : 16|16@1+ (1,0) [0|0] "" Vector__XXX
 SG_ VC_hcmr_ic500_EEPROMWriteCount m3 : 16|16@1+ (1,0) [0|0] "" Vector__XXX
 SG_ VC_hcmr_ic700_EEPROMWriteCount m5 : 16|16@1+ (1,0) [0|0] "" Vector__XXX
 SG_ VC_hcmrFault_TURN_COMPOV m4 : 17|1@1+ (1,0) [0|0] "" Vector__XXX
 SG_ VC_hcmrFault_TURN_HSILIM m4 : 18|1@1+ (1,0) [0|0] "" Vector__XXX
 SG_ VC_hcmrFault_TURN_LSILIM m4 : 19|1@1+ (1,0) [0|0] "" Vector__XXX
 SG_ VC_hcmrFault_TURN_BOOTUV m4 : 20|1@1+ (1,0) [0|0] "" Vector__XXX
 SG_ VC_hcmrFault_TURN_TOFFMIN m4 : 21|1@1+ (1,0) [0|0] "" Vector__XXX
 SG_ VC_hcmrFault_TURN_LEDUV m4 : 22|1@1+ (1,0) [0|0] "" Vector__XXX
 SG_ VC_hcmrFault_TURN_LEDOV m4 : 23|1@1+ (1,0) [0|0] "" Vector__XXX
 SG_ VC_hcmrUartGroupsFullErrorCounter m8 : 24|8@1+ (1,0) [0|0] "" Vector__XXX
 SG_ VC_hcmrVoltage_DRL m6 : 24|10@1+ (0.1,0) [0|0] "" Vector__XXX
 SG_ VC_hcmr_ic600_EEPROMWriteCount m4 : 24|16@1+ (1,0) [0|0] "" Vector__XXX
 SG_ VC_infoHCMRPcbaId m1 : 24|16@1+ (1,0) [0|0] "" Vector__XXX
 SG_ VC_rightHeadlampLMMVariant m0 : 24|2@1+ (1,0) [0|0] "" Vector__XXX
 SG_ VC_hcmrUartValidatedGroupsFullErrorCounter m8 : 32|8@1+ (1,0) [0|0] "" Vector__XXX
 SG_ VC_hcmrVoltage_TURN m6 : 34|10@1+ (0.1,0) [0|0] "" Vector__XXX
 SG_ VC_hcmrUartDmaQueueFullErrorCounter m8 : 40|8@1+ (1,0) [0|0] "" Vector__XXX
 SG_ VC_infoHCMRUsageId m1 : 40|16@1+ (1,0) [0|0] "" Vector__XXX
 SG_ VC_hcmrVoltage_SM m6 : 44|10@1+ (0.1,0) [0|0] "" Vector__XXX
 SG_ VC_hcmrUartQueueResetCounter m8 : 48|8@1+ (1,0) [0|0] "" Vector__XXX
 SG_ VC_hcmrVoltage_boostRail m6 : 54|10@1+ (0.1,0) [0|0] "" Vector__XXX

BO_ 1981 V2G_vehLogData: 8 Vector__XXX
 SG_ V2G_vehLogDataSelect M : 0|5@1+ (1,0) [0|0] "" Vector__XXX
 SG_ V2G_cableCheckReq_sent m8 : 5|1@1+ (1,0) [0|0] "" Vector__XXX
 SG_ V2G_chargingStatusReq_sent m12 : 5|1@1+ (1,0) [0|0] "" Vector__XXX
 SG_ V2G_contractAuthReq_sent m6 : 5|1@1+ (1,0) [0|0] "" Vector__XXX
 SG_ V2G_currentDemReq_targetI m11 : 5|10@1+ (1.7578125,0) [0|0] "" Vector__XXX
 SG_ V2G_paymentDetailsReq_sent m5 : 5|1@1+ (1,0) [0|0] "" Vector__XXX
 SG_ V2G_powerDeliveryEndReq_sent m13 : 5|1@1+ (1,0) [0|0] "" Vector__XXX
 SG_ V2G_powerDeliveryStartReq_sent m10 : 5|1@1+ (1,0) [0|0] "" Vector__XXX
 SG_ V2G_serviceDetailReq_sent m3 : 5|1@1+ (1,0) [0|0] "" Vector__XXX
 SG_ V2G_serviceDiscoveryReq_sent m2 : 5|1@1+ (1,0) [0|0] "" Vector__XXX
 SG_ V2G_servicePaymentSelReq_sent m4 : 5|1@1+ (1,0) [0|0] "" Vector__XXX
 SG_ V2G_sessionSetupReq_sent m1 : 5|1@1+ (1,0) [0|0] "" Vector__XXX
 SG_ V2G_sessionStopReq_sent m14 : 5|1@1+ (1,0) [0|0] "" Vector__XXX
 SG_ V2G_suppAppProtocolReq_sent m0 : 5|1@1+ (1,0) [0|0] "" Vector__XXX
 SG_ V2G_powerDelEndReq_evStatusCode m13 : 6|1@1+ (1,0) [0|0] "" Vector__XXX
 SG_ V2G_chgParamReq_maxCurrentLim m7 : 8|13@1+ (0.2197265625,0) [0|0] "" Vector__XXX
 SG_ V2G_prechargeReq_targetV m9 : 8|13@1+ (0.146484375,0) [0|0] "" Vector__XXX
 SG_ V2G_currentDemReq_targetV m11 : 16|13@1+ (0.146484375,0) [0|0] "" Vector__XXX
 SG_ V2G_chgParamReq_maxVoltageLim m7 : 24|13@1+ (0.146484375,0) [0|0] "" Vector__XXX
 SG_ V2G_currentDemReq_maxCurrentLim m11 : 29|10@1+ (1.7578125,0) [0|0] "" Vector__XXX
 SG_ V2G_chgParamReq_maxPowerLim m7 : 40|13@1+ (0.1867675781,0) [0|0] "" Vector__XXX
 SG_ V2G_currentDemReq_maxVoltageLim m11 : 40|10@1+ (1.171875,0) [0|0] "" Vector__XXX
 SG_ V2G_currentDemReq_maxPowerLim m11 : 50|10@1+ (1.494138,0) [0|0] "" Vector__XXX
 SG_ V2G_chgParamReq_evStatusCode m7 : 56|4@1+ (1,0) [0|0] "" Vector__XXX
 SG_ V2G_chgParamReq_evReady m7 : 60|1@1+ (1,0) [0|0] "" Vector__XXX

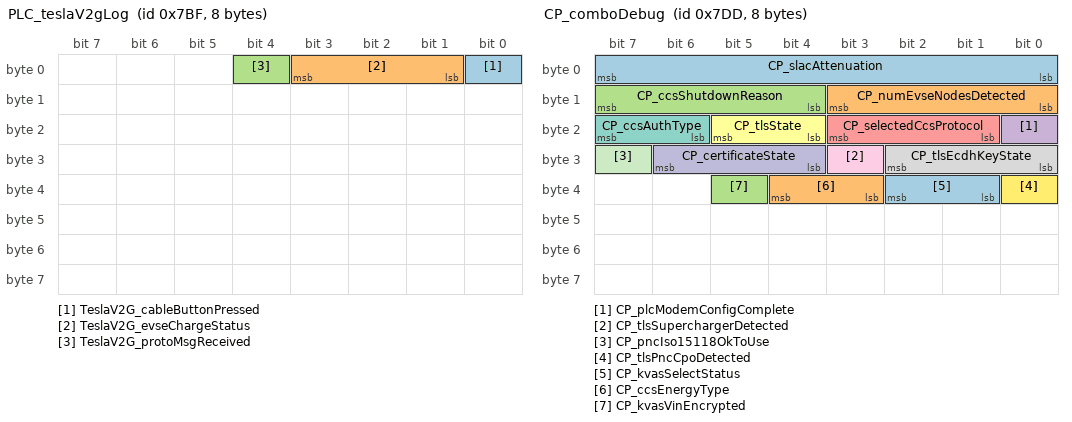
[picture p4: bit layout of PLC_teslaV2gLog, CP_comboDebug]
BO_ 1983 PLC_teslaV2gLog: 8 Vector__XXX
 SG_ TeslaV2G_cableButtonPressed : 0|1@1+ (1,0) [0|0] "" Vector__XXX
 SG_ TeslaV2G_evseChargeStatus : 1|3@1+ (1,0) [0|0] "" Vector__XXX
 SG_ TeslaV2G_protoMsgReceived : 4|1@1+ (1,0) [0|0] "" Vector__XXX

BO_ 1992 EPBL_info: 8 Vector__XXX
 SG_ EPBL_infoIndex M : 0|8@1+ (1,0) [0|0] "" Vector__XXX
 SG_ EPBL_infoAppCrc m13 : 8|32@1+ (1,0) [0|0] "" Vector__XXX
 SG_ EPBL_infoAppGitHash m17 : 8|56@1+ (1,0) [0|0] "" Vector__XXX
 SG_ EPBL_infoBootGitHash m18 : 8|56@1+ (1,0) [0|0] "" Vector__XXX
 SG_ EPBL_infoBootUdsProtoVersion m20 : 8|16@1+ (1,0) [0|0] "" Vector__XXX
 SG_ EPBL_infoBuildType m10 : 8|3@1+ (1,0) [0|0] "" Vector__XXX
 SG_ EPBL_infoPcbaId m11 : 8|8@1+ (1,0) [0|0] "" Vector__XXX
 SG_ EPBL_infoPlatformType m19 : 8|8@1+ (1,0) [0|0] "" Vector__XXX
 SG_ EPBL_infoAssemblyId m11 : 16|8@1+ (1,0) [0|0] "" Vector__XXX
 SG_ EPBL_infoBuildConfigId m10 : 16|16@1+ (1,0) [0|0] "" Vector__XXX
 SG_ EPBL_infoBootCrc m20 : 24|32@1+ (1,0) [0|0] "" Vector__XXX
 SG_ EPBL_infoUsageId m11 : 24|16@1+ (1,0) [0|0] "" Vector__XXX
 SG_ EPBL_infoHardwareId m10 : 32|16@1+ (1,0) [0|0] "" Vector__XXX
 SG_ EPBL_infoSubUsageId m11 : 40|16@1+ (1,0) [0|0] "" Vector__XXX
 SG_ EPBL_infoComponentId m10 : 48|16@1+ (1,0) [0|0] "" Vector__XXX

BO_ 1999 PM_debug: 8 Vector__XXX
 SG_ PM_debugSelector M : 0|8@1+ (1,0) [0|0] "" Vector__XXX
 SG_ PM_cpu100HzAvg m65 : 8|8@1+ (0.4,0) [0|0] "" Vector__XXX
 SG_ PM_cpu10kHzMin m66 : 8|8@1+ (0.4,0) [0|0] "" Vector__XXX
 SG_ PM_cpu1kHzMax m64 : 8|8@1+ (0.4,0) [0|0] "" Vector__XXX
 SG_ PM_gear m18 : 8|3@1+ (1,0) [0|0] "" Vector__XXX
 SG_ PM_idleStackSize m67 : 8|16@1+ (1,0) [0|0] "" Vector__XXX
 SG_ PM_pedalPos m5 : 8|8@1+ (0.4,0) [0|0] "" Vector__XXX
 SG_ PM_speedAverage m3 : 8|16@1- (0.1,0) [0|0] "" Vector__XXX
 SG_ PM_sysPedalMinTorque m16 : 8|15@1+ (0.5,-13000) [0|0] "" Vector__XXX
 SG_ PM_sysPostPedalMinTorque m17 : 8|15@1+ (0.5,-13000) [0|0] "" Vector__XXX
 SG_ PM_systemTorqueCommand m4 : 8|16@1- (0.5,0) [0|0] "" Vector__XXX
 SG_ PM_torqueDecelWindow m2 : 8|13@1- (2,0) [0|0] "" Vector__XXX
 SG_ PM_torqueSignError m1 : 8|13@1- (2,0) [0|0] "" Vector__XXX
 SG_ PM_udsStackSize m68 : 8|16@1+ (1,0) [0|0] "" Vector__XXX
 SG_ PM_xcpStackSize m69 : 8|16@1+ (1,0) [0|0] "" Vector__XXX
 SG_ PM_aebState m18 : 11|3@1+ (1,0) [0|0] "" Vector__XXX
 SG_ PM_cpu10HzMax m65 : 16|8@1+ (0.4,0) [0|0] "" Vector__XXX
 SG_ PM_cpu20kHzAvg m64 : 16|8@1+ (0.4,0) [0|0] "" Vector__XXX
 SG_ PM_pedalPosB m5 : 16|8@1+ (0.4,0) [0|0] "" Vector__XXX
 SG_ PM_vehicleHoldState m18 : 16|3@1+ (1,0) [0|0] "" Vector__XXX
 SG_ PM_sysPedalMaxTorque m16 : 23|15@1+ (0.5,0) [0|0] "" Vector__XXX
 SG_ PM_sysPostPedalMaxTorque m17 : 23|15@1+ (0.5,0) [0|0] "" Vector__XXX
 SG_ PM_cpu10HzAvg m65 : 24|8@1+ (0.4,0) [0|0] "" Vector__XXX
 SG_ PM_cpu1kHzMin m64 : 24|8@1+ (0.4,0) [0|0] "" Vector__XXX
 SG_ PM_idleStackMax m67 : 24|16@1+ (1,0) [0|0] "" Vector__XXX
 SG_ PM_pedalPosA m5 : 24|8@1+ (0.4,0) [0|0] "" Vector__XXX
 SG_ PM_shiftRequest m4 : 24|1@1+ (1,0) [0|0] "" Vector__XXX
 SG_ PM_speedMax m3 : 24|16@1- (0.1,0) [0|0] "" Vector__XXX
 SG_ PM_torqueAccelWindow m1 : 24|13@1- (2,0) [0|0] "" Vector__XXX
 SG_ PM_torqueDecelAvg m2 : 24|13@1- (2,0) [0|0] "" Vector__XXX
 SG_ PM_udsStackMax m68 : 24|16@1+ (1,0) [0|0] "" Vector__XXX
 SG_ PM_xcpStackMax m69 : 24|16@1+ (1,0) [0|0] "" Vector__XXX
 SG_ PM_allowedRegenBackfillBrakeTorque m4 : 32|16@1- (0.5,0) [0|0] "" Vector__XXX
 SG_ PM_cpu10HzMin m65 : 32|8@1+ (0.4,0) [0|0] "" Vector__XXX
 SG_ PM_cpu10kHzAvg m64 : 32|8@1+ (0.4,0) [0|0] "" Vector__XXX
 SG_ PM_pedalRailA m5 : 32|6@1+ (0.085,0) [0|0] "" Vector__XXX
 SG_ PM_cpu100HzMax m64 : 40|8@1+ (0.4,0) [0|0] "" Vector__XXX
 SG_ PM_cpu20kHzMax m65 : 40|8@1+ (0.4,0) [0|0] "" Vector__XXX
 SG_ PM_pedalRailB m5 : 40|6@1+ (0.085,0) [0|0] "" Vector__XXX
 SG_ PM_speedMin m3 : 40|16@1- (0.1,0) [0|0] "" Vector__XXX
 SG_ PM_torqueAccelAvg m1 : 40|13@1- (2,0) [0|0] "" Vector__XXX
 SG_ PM_torqueReversalWindow m2 : 40|13@1- (2,0) [0|0] "" Vector__XXX
 SG_ PM_cpu1kHzAvg m64 : 48|8@1+ (0.4,0) [0|0] "" Vector__XXX
 SG_ PM_cpu20kHzMin m65 : 48|8@1+ (0.4,0) [0|0] "" Vector__XXX
 SG_ PM_regenBackfillState m4 : 48|2@1+ (1,0) [0|0] "" Vector__XXX
 SG_ PM_cpu100HzMin m64 : 56|8@1+ (0.4,0) [0|0] "" Vector__XXX
 SG_ PM_cpu10kHzMax m65 : 56|8@1+ (0.4,0) [0|0] "" Vector__XXX

BO_ 2002 BMS_debugInfo_1Hz: 8 Vector__XXX
 SG_ BMS_1HzDebug_Id M : 0|4@1+ (1,0) [0|0] "" Vector__XXX
 SG_ BMS_dbgEpochTimeCorrectionCount m3 : 4|8@1+ (1,0) [0|0] "" Vector__XXX
 SG_ BMS_dbgMinBrickTempForFullWallPower m12 : 4|11@1+ (0.1,-50) [0|0] "" Vector__XXX
 SG_ BMS_dbgStackUse_Idle m11 : 4|10@1+ (2,0) [0|0] "" Vector__XXX
 SG_ BMS_dbgStackUse_Nvram m4 : 4|10@1+ (1,0) [0|0] "" Vector__XXX
 SG_ BMS_energyChgAhRemaining m2 : 4|12@1+ (0.1,0) [0|0] "" Vector__XXX
 SG_ BMS_brickBleedDbg1 m0 : 8|1@1+ (1,0) [0|0] "" Vector__XXX
 SG_ BMS_brickBleedDbg57 m1 : 8|1@1+ (1,0) [0|0] "" Vector__XXX
 SG_ BMS_dbgBirthDateModule1 m6 : 8|32@1+ (1,0) [0|0] "" Vector__XXX
 SG_ BMS_dbgBirthDateModule2 m7 : 8|32@1+ (1,0) [0|0] "" Vector__XXX
 SG_ BMS_dbgBirthDateModule3 m8 : 8|32@1+ (1,0) [0|0] "" Vector__XXX
 SG_ BMS_dbgBirthDateModule4 m9 : 8|32@1+ (1,0) [0|0] "" Vector__XXX
 SG_ BMS_dbgPackBirthDate m5 : 8|32@1+ (1,0) [0|0] "" Vector__XXX
 SG_ BMS_brickBleedDbg2 m0 : 9|1@1+ (1,0) [0|0] "" Vector__XXX
 SG_ BMS_brickBleedDbg58 m1 : 9|1@1+ (1,0) [0|0] "" Vector__XXX
 SG_ BMS_brickBleedDbg3 m0 : 10|1@1+ (1,0) [0|0] "" Vector__XXX
 SG_ BMS_brickBleedDbg59 m1 : 10|1@1+ (1,0) [0|0] "" Vector__XXX
 SG_ BMS_brickBleedDbg4 m0 : 11|1@1+ (1,0) [0|0] "" Vector__XXX
 SG_ BMS_brickBleedDbg60 m1 : 11|1@1+ (1,0) [0|0] "" Vector__XXX
 SG_ BMS_brickBleedDbg5 m0 : 12|1@1+ (1,0) [0|0] "" Vector__XXX
 SG_ BMS_brickBleedDbg61 m1 : 12|1@1+ (1,0) [0|0] "" Vector__XXX
 SG_ BMS_energyLatchedMinSoc m3 : 12|10@1+ (0.1,0) [0|0] "" Vector__XXX
 SG_ BMS_brickBleedDbg6 m0 : 13|1@1+ (1,0) [0|0] "" Vector__XXX
 SG_ BMS_brickBleedDbg62 m1 : 13|1@1+ (1,0) [0|0] "" Vector__XXX
 SG_ BMS_brickBleedDbg63 m1 : 14|1@1+ (1,0) [0|0] "" Vector__XXX
 SG_ BMS_brickBleedDbg7 m0 : 14|1@1+ (1,0) [0|0] "" Vector__XXX
 SG_ BMS_dbgStackUse_1Hz m4 : 14|10@1+ (2,0) [0|0] "" Vector__XXX
 SG_ BMS_brickBleedDbg64 m1 : 15|1@1+ (1,0) [0|0] "" Vector__XXX
 SG_ BMS_brickBleedDbg8 m0 : 15|1@1+ (1,0) [0|0] "" Vector__XXX
 SG_ BMS_brickBleedDbg65 m1 : 16|1@1+ (1,0) [0|0] "" Vector__XXX
 SG_ BMS_brickBleedDbg9 m0 : 16|1@1+ (1,0) [0|0] "" Vector__XXX
 SG_ BMS_dbgStoredEpochTime m12 : 16|32@1+ (1,0) [0|0] "" Vector__XXX
 SG_ BMS_energyDchAhRemaining m2 : 16|12@1+ (0.1,0) [0|0] "" Vector__XXX
 SG_ BMS_brickBleedDbg10 m0 : 17|1@1+ (1,0) [0|0] "" Vector__XXX
 SG_ BMS_brickBleedDbg66 m1 : 17|1@1+ (1,0) [0|0] "" Vector__XXX
 SG_ BMS_brickBleedDbg11 m0 : 18|1@1+ (1,0) [0|0] "" Vector__XXX
 SG_ BMS_brickBleedDbg67 m1 : 18|1@1+ (1,0) [0|0] "" Vector__XXX
 SG_ BMS_brickBleedDbg12 m0 : 19|1@1+ (1,0) [0|0] "" Vector__XXX
 SG_ BMS_brickBleedDbg68 m1 : 19|1@1+ (1,0) [0|0] "" Vector__XXX
 SG_ BMS_brickBleedDbg13 m0 : 20|1@1+ (1,0) [0|0] "" Vector__XXX
 SG_ BMS_brickBleedDbg69 m1 : 20|1@1+ (1,0) [0|0] "" Vector__XXX
 SG_ BMS_brickBleedDbg14 m0 : 21|1@1+ (1,0) [0|0] "" Vector__XXX
 SG_ BMS_brickBleedDbg70 m1 : 21|1@1+ (1,0) [0|0] "" Vector__XXX
 SG_ BMS_brickBleedDbg15 m0 : 22|1@1+ (1,0) [0|0] "" Vector__XXX
 SG_ BMS_brickBleedDbg71 m1 : 22|1@1+ (1,0) [0|0] "" Vector__XXX
 SG_ BMS_energyLatchedAveSoc m3 : 22|10@1+ (0.1,0) [0|0] "" Vector__XXX
 SG_ BMS_brickBleedDbg16 m0 : 23|1@1+ (1,0) [0|0] "" Vector__XXX
 SG_ BMS_brickBleedDbg72 m1 : 23|1@1+ (1,0) [0|0] "" Vector__XXX
 SG_ BMS_brickBleedDbg17 m0 : 24|1@1+ (1,0) [0|0] "" Vector__XXX
 SG_ BMS_brickBleedDbg73 m1 : 24|1@1+ (1,0) [0|0] "" Vector__XXX
 SG_ BMS_dbgStackUse_10Hz m4 : 24|10@1+ (1,0) [0|0] "" Vector__XXX
 SG_ BMS_brickBleedDbg18 m0 : 25|1@1+ (1,0) [0|0] "" Vector__XXX
 SG_ BMS_brickBleedDbg74 m1 : 25|1@1+ (1,0) [0|0] "" Vector__XXX
 SG_ BMS_brickBleedDbg19 m0 : 26|1@1+ (1,0) [0|0] "" Vector__XXX
 SG_ BMS_brickBleedDbg75 m1 : 26|1@1+ (1,0) [0|0] "" Vector__XXX
 SG_ BMS_brickBleedDbg20 m0 : 27|1@1+ (1,0) [0|0] "" Vector__XXX
 SG_ BMS_brickBleedDbg76 m1 : 27|1@1+ (1,0) [0|0] "" Vector__XXX
 SG_ BMS_brickBleedDbg21 m0 : 28|1@1+ (1,0) [0|0] "" Vector__XXX
 SG_ BMS_brickBleedDbg77 m1 : 28|1@1+ (1,0) [0|0] "" Vector__XXX
 SG_ BMS_chgAhLimitingBrickIndex m2 : 28|7@1+ (1,0) [0|0] "" Vector__XXX
 SG_ BMS_brickBleedDbg22 m0 : 29|1@1+ (1,0) [0|0] "" Vector__XXX
 SG_ BMS_brickBleedDbg78 m1 : 29|1@1+ (1,0) [0|0] "" Vector__XXX
 SG_ BMS_brickBleedDbg23 m0 : 30|1@1+ (1,0) [0|0] "" Vector__XXX
 SG_ BMS_brickBleedDbg79 m1 : 30|1@1+ (1,0) [0|0] "" Vector__XXX
 SG_ BMS_brickBleedDbg24 m0 : 31|1@1+ (1,0) [0|0] "" Vector__XXX
 SG_ BMS_brickBleedDbg80 m1 : 31|1@1+ (1,0) [0|0] "" Vector__XXX
 SG_ BMS_brickBleedDbg25 m0 : 32|1@1+ (1,0) [0|0] "" Vector__XXX
 SG_ BMS_brickBleedDbg81 m1 : 32|1@1+ (1,0) [0|0] "" Vector__XXX
 SG_ BMS_energyLatchedMinCac m3 : 32|12@1+ (0.1,0) [0|0] "" Vector__XXX
 SG_ BMS_brickBleedDbg26 m0 : 33|1@1+ (1,0) [0|0] "" Vector__XXX
 SG_ BMS_brickBleedDbg82 m1 : 33|1@1+ (1,0) [0|0] "" Vector__XXX
 SG_ BMS_brickBleedDbg27 m0 : 34|1@1+ (1,0) [0|0] "" Vector__XXX
 SG_ BMS_brickBleedDbg83 m1 : 34|1@1+ (1,0) [0|0] "" Vector__XXX
 SG_ BMS_dbgStackUse_100Hz m4 : 34|10@1+ (1,0) [0|0] "" Vector__XXX
 SG_ BMS_brickBleedDbg28 m0 : 35|1@1+ (1,0) [0|0] "" Vector__XXX
 SG_ BMS_brickBleedDbg84 m1 : 35|1@1+ (1,0) [0|0] "" Vector__XXX
 SG_ BMS_dchAhLimitingBrickIndex m2 : 35|7@1+ (1,0) [0|0] "" Vector__XXX
 SG_ BMS_brickBleedDbg29 m0 : 36|1@1+ (1,0) [0|0] "" Vector__XXX
 SG_ BMS_brickBleedDbg85 m1 : 36|1@1+ (1,0) [0|0] "" Vector__XXX
 SG_ BMS_brickBleedDbg30 m0 : 37|1@1+ (1,0) [0|0] "" Vector__XXX
 SG_ BMS_brickBleedDbg86 m1 : 37|1@1+ (1,0) [0|0] "" Vector__XXX
 SG_ BMS_brickBleedDbg31 m0 : 38|1@1+ (1,0) [0|0] "" Vector__XXX
 SG_ BMS_brickBleedDbg87 m1 : 38|1@1+ (1,0) [0|0] "" Vector__XXX
 SG_ BMS_brickBleedDbg32 m0 : 39|1@1+ (1,0) [0|0] "" Vector__XXX
 SG_ BMS_brickBleedDbg88 m1 : 39|1@1+ (1,0) [0|0] "" Vector__XXX
 SG_ BMS_brickBleedDbg33 m0 : 40|1@1+ (1,0) [0|0] "" Vector__XXX
 SG_ BMS_brickBleedDbg89 m1 : 40|1@1+ (1,0) [0|0] "" Vector__XXX
 SG_ BMS_brickBleedDbg34 m0 : 41|1@1+ (1,0) [0|0] "" Vector__XXX
 SG_ BMS_brickBleedDbg90 m1 : 41|1@1+ (1,0) [0|0] "" Vector__XXX
 SG_ BMS_brickBleedDbg35 m0 : 42|1@1+ (1,0) [0|0] "" Vector__XXX
 SG_ BMS_brickBleedDbg91 m1 : 42|1@1+ (1,0) [0|0] "" Vector__XXX
 SG_ BMS_energyChgTargetPackSoc m2 : 42|10@1+ (0.1,0) [0|0] "" Vector__XXX
 SG_ BMS_brickBleedDbg36 m0 : 43|1@1+ (1,0) [0|0] "" Vector__XXX
 SG_ BMS_brickBleedDbg92 m1 : 43|1@1+ (1,0) [0|0] "" Vector__XXX
 SG_ BMS_brickBleedDbg37 m0 : 44|1@1+ (1,0) [0|0] "" Vector__XXX
 SG_ BMS_brickBleedDbg93 m1 : 44|1@1+ (1,0) [0|0] "" Vector__XXX
 SG_ BMS_dbgStackUse_1KHz m4 : 44|10@1+ (1,0) [0|0] "" Vector__XXX
 SG_ BMS_energyLatchedAveCac m3 : 44|12@1+ (0.1,0) [0|0] "" Vector__XXX
 SG_ BMS_brickBleedDbg38 m0 : 45|1@1+ (1,0) [0|0] "" Vector__XXX
 SG_ BMS_brickBleedDbg94 m1 : 45|1@1+ (1,0) [0|0] "" Vector__XXX
 SG_ BMS_brickBleedDbg39 m0 : 46|1@1+ (1,0) [0|0] "" Vector__XXX
 SG_ BMS_brickBleedDbg95 m1 : 46|1@1+ (1,0) [0|0] "" Vector__XXX
 SG_ BMS_brickBleedDbg40 m0 : 47|1@1+ (1,0) [0|0] "" Vector__XXX
 SG_ BMS_brickBleedDbg96 m1 : 47|1@1+ (1,0) [0|0] "" Vector__XXX
 SG_ BMS_brickBleedDbg41 m0 : 48|1@1+ (1,0) [0|0] "" Vector__XXX
 SG_ BMS_brickBleedDbg97 m1 : 48|1@1+ (1,0) [0|0] "" Vector__XXX
 SG_ BMS_brickBleedDbg42 m0 : 49|1@1+ (1,0) [0|0] "" Vector__XXX
 SG_ BMS_brickBleedDbg98 m1 : 49|1@1+ (1,0) [0|0] "" Vector__XXX
 SG_ BMS_brickBleedDbg43 m0 : 50|1@1+ (1,0) [0|0] "" Vector__XXX
 SG_ BMS_brickBleedDbg99 m1 : 50|1@1+ (1,0) [0|0] "" Vector__XXX
 SG_ BMS_brickBleedDbg100 m1 : 51|1@1+ (1,0) [0|0] "" Vector__XXX
 SG_ BMS_brickBleedDbg44 m0 : 51|1@1+ (1,0) [0|0] "" Vector__XXX
 SG_ BMS_brickBleedDbg101 m1 : 52|1@1+ (1,0) [0|0] "" Vector__XXX
 SG_ BMS_brickBleedDbg45 m0 : 52|1@1+ (1,0) [0|0] "" Vector__XXX
 SG_ BMS_energyStopTarget m2 : 52|10@1+ (0.1,0) [0|0] "" Vector__XXX
 SG_ BMS_brickBleedDbg102 m1 : 53|1@1+ (1,0) [0|0] "" Vector__XXX
 SG_ BMS_brickBleedDbg46 m0 : 53|1@1+ (1,0) [0|0] "" Vector__XXX
 SG_ BMS_brickBleedDbg103 m1 : 54|1@1+ (1,0) [0|0] "" Vector__XXX
 SG_ BMS_brickBleedDbg47 m0 : 54|1@1+ (1,0) [0|0] "" Vector__XXX
 SG_ BMS_dbgStackUse_UDS m4 : 54|10@1+ (1,0) [0|0] "" Vector__XXX
 SG_ BMS_brickBleedDbg104 m1 : 55|1@1+ (1,0) [0|0] "" Vector__XXX
 SG_ BMS_brickBleedDbg48 m0 : 55|1@1+ (1,0) [0|0] "" Vector__XXX
 SG_ BMS_brickBleedDbg105 m1 : 56|1@1+ (1,0) [0|0] "" Vector__XXX
 SG_ BMS_brickBleedDbg49 m0 : 56|1@1+ (1,0) [0|0] "" Vector__XXX
 SG_ BMS_energyInitialPackTemp m3 : 56|8@1- (1,40) [0|0] "" Vector__XXX
 SG_ BMS_brickBleedDbg106 m1 : 57|1@1+ (1,0) [0|0] "" Vector__XXX
 SG_ BMS_brickBleedDbg50 m0 : 57|1@1+ (1,0) [0|0] "" Vector__XXX
 SG_ BMS_brickBleedDbg107 m1 : 58|1@1+ (1,0) [0|0] "" Vector__XXX
 SG_ BMS_brickBleedDbg51 m0 : 58|1@1+ (1,0) [0|0] "" Vector__XXX
 SG_ BMS_brickBleedDbg108 m1 : 59|1@1+ (1,0) [0|0] "" Vector__XXX
 SG_ BMS_brickBleedDbg52 m0 : 59|1@1+ (1,0) [0|0] "" Vector__XXX
 SG_ BMS_brickBleedDbg109 m1 : 60|1@1+ (1,0) [0|0] "" Vector__XXX
 SG_ BMS_brickBleedDbg53 m0 : 60|1@1+ (1,0) [0|0] "" Vector__XXX
 SG_ BMS_brickBleedDbg110 m1 : 61|1@1+ (1,0) [0|0] "" Vector__XXX
 SG_ BMS_brickBleedDbg54 m0 : 61|1@1+ (1,0) [0|0] "" Vector__XXX
 SG_ BMS_brickBleedDbg111 m1 : 62|1@1+ (1,0) [0|0] "" Vector__XXX
 SG_ BMS_brickBleedDbg55 m0 : 62|1@1+ (1,0) [0|0] "" Vector__XXX
 SG_ BMS_dbgEnergyVariableChgRequested m2 : 62|1@1+ (1,0) [0|0] "" Vector__XXX
 SG_ BMS_brickBleedDbg112 m1 : 63|1@1+ (1,0) [0|0] "" Vector__XXX
 SG_ BMS_brickBleedDbg56 m0 : 63|1@1+ (1,0) [0|0] "" Vector__XXX

BO_ 2004 PMR_debug: 8 Vector__XXX
 SG_ PMR_debugSelector M : 0|8@1+ (1,0) [0|0] "" Vector__XXX
 SG_ PMR_Ia m3 : 8|16@1- (0.0939,0) [0|0] "" Vector__XXX
 SG_ PMR_cpu100HzAvg m65 : 8|8@1+ (0.4,0) [0|0] "" Vector__XXX
 SG_ PMR_cpu10kHzMin m66 : 8|8@1+ (0.4,0) [0|0] "" Vector__XXX
 SG_ PMR_cpu1kHzMax m64 : 8|8@1+ (0.4,0) [0|0] "" Vector__XXX
 SG_ PMR_idleStackSize m67 : 8|16@1+ (1,0) [0|0] "" Vector__XXX
 SG_ PMR_offsetIa m5 : 8|12@1- (0.1,0) [0|0] "" Vector__XXX
 SG_ PMR_resolverPhaseAngle m17 : 8|9@1+ (0.001537,0) [0|0] "" Vector__XXX
 SG_ PMR_resolverSpeedError m16 : 8|16@1- (0.75,0) [0|0] "" Vector__XXX
 SG_ PMR_slipFrequency m4 : 8|16@1- (0.005,0) [0|0] "" Vector__XXX
 SG_ PMR_sysStackSize m70 : 8|16@1+ (1,0) [0|0] "" Vector__XXX
 SG_ PMR_torqueDecelWindow m2 : 8|13@1- (2,0) [0|0] "" Vector__XXX
 SG_ PMR_torqueSignError m1 : 8|13@1- (2,0) [0|0] "" Vector__XXX
 SG_ PMR_udsStackSize m68 : 8|16@1+ (1,0) [0|0] "" Vector__XXX
 SG_ PMR_xcpStackSize m69 : 8|16@1+ (1,0) [0|0] "" Vector__XXX
 SG_ PMR_cpu10HzMax m65 : 16|8@1+ (0.4,0) [0|0] "" Vector__XXX
 SG_ PMR_cpu20kHzAvg m64 : 16|8@1+ (0.4,0) [0|0] "" Vector__XXX
 SG_ PMR_resolverCommonGain m17 : 17|7@1+ (0.063,0) [0|0] "" Vector__XXX
 SG_ PMR_offsetIb m5 : 20|12@1- (0.1,0) [0|0] "" Vector__XXX
 SG_ PMR_Ib m3 : 24|16@1- (0.0939,0) [0|0] "" Vector__XXX
 SG_ PMR_cpu10HzAvg m65 : 24|8@1+ (0.4,0) [0|0] "" Vector__XXX
 SG_ PMR_cpu1kHzMin m64 : 24|8@1+ (0.4,0) [0|0] "" Vector__XXX
 SG_ PMR_idleStackMax m67 : 24|16@1+ (1,0) [0|0] "" Vector__XXX
 SG_ PMR_resolverExcitationGain m17 : 24|7@1+ (0.063,0) [0|0] "" Vector__XXX
 SG_ PMR_sysStackMax m70 : 24|16@1+ (1,0) [0|0] "" Vector__XXX
 SG_ PMR_torqueAccelWindow m1 : 24|13@1- (2,0) [0|0] "" Vector__XXX
 SG_ PMR_torqueDecelAvg m2 : 24|13@1- (2,0) [0|0] "" Vector__XXX
 SG_ PMR_udsStackMax m68 : 24|16@1+ (1,0) [0|0] "" Vector__XXX
 SG_ PMR_xcpStackMax m69 : 24|16@1+ (1,0) [0|0] "" Vector__XXX
 SG_ PMR_cpu10HzMin m65 : 32|8@1+ (0.4,0) [0|0] "" Vector__XXX
 SG_ PMR_cpu10kHzAvg m64 : 32|8@1+ (0.4,0) [0|0] "" Vector__XXX
 SG_ PMR_resolverOffsetCos m17 : 32|6@1+ (0.053,0) [0|0] "" Vector__XXX
 SG_ PMR_cpu100HzMax m64 : 40|8@1+ (0.4,0) [0|0] "" Vector__XXX
 SG_ PMR_cpu20kHzMax m65 : 40|8@1+ (0.4,0) [0|0] "" Vector__XXX
 SG_ PMR_iDQmagnitude m3 : 40|16@1- (0.0939,0) [0|0] "" Vector__XXX
 SG_ PMR_motorRPM m4 : 40|16@1- (1,0) [0|0] "" Vector__XXX
 SG_ PMR_resolverOffsetSin m17 : 40|6@1+ (0.053,0) [0|0] "" Vector__XXX
 SG_ PMR_torqueAccelAvg m1 : 40|13@1- (2,0) [0|0] "" Vector__XXX
 SG_ PMR_torqueReversalWindow m2 : 40|13@1- (2,0) [0|0] "" Vector__XXX
 SG_ PMR_switchingActive m5 : 46|1@1+ (1,0) [0|0] "" Vector__XXX
 SG_ PMR_torqueOutOfMap m5 : 47|1@1+ (1,0) [0|0] "" Vector__XXX
 SG_ PMR_cpu1kHzAvg m64 : 48|8@1+ (0.4,0) [0|0] "" Vector__XXX
 SG_ PMR_cpu20kHzMin m65 : 48|8@1+ (0.4,0) [0|0] "" Vector__XXX
 SG_ PMR_resolverOffsetExt m17 : 48|6@1+ (0.053,0) [0|0] "" Vector__XXX
 SG_ PMR_resolverNoCarrier m17 : 54|1@1+ (1,0) [0|0] "" Vector__XXX
 SG_ PMR_resolverPhaseOutOfSpec m17 : 55|1@1+ (1,0) [0|0] "" Vector__XXX
 SG_ PMR_cpu100HzMin m64 : 56|8@1+ (0.4,0) [0|0] "" Vector__XXX
 SG_ PMR_cpu10kHzMax m65 : 56|8@1+ (0.4,0) [0|0] "" Vector__XXX
 SG_ PMR_lmSatCoeff m3 : 56|8@1+ (0.00391,0) [0|0] "" Vector__XXX
 SG_ PMR_resolverClaMIA m17 : 56|1@1+ (1,0) [0|0] "" Vector__XXX
 SG_ PMR_statorT m4 : 56|8@1+ (1,-40) [0|0] "" Vector__XXX
 SG_ PMR_resolverDiMIA m17 : 57|1@1+ (1,0) [0|0] "" Vector__XXX

BO_ 2005 DIR_debug: 8 Vector__XXX
 SG_ DIR_debugSelector M : 0|8@1+ (1,0) [0|0] "" Vector__XXX
 SG_ DIR_cpu10HzMin m66 : 8|8@1+ (0.4,0) [0|0] "" Vector__XXX
 SG_ DIR_cpu1HzMin m128 : 8|8@1+ (0.4,0) [0|0] "" Vector__XXX
 SG_ DIR_cpu1kHzMin m67 : 8|8@1+ (0.4,0) [0|0] "" Vector__XXX
 SG_ DIR_dcCapTemp m64 : 8|8@1+ (1,-40) [0|0] "" Vector__XXX
 SG_ DIR_gainScale m37 : 8|8@1+ (0.01,0) [0|0] "" Vector__XXX
 SG_ DIR_hwFaultCount m69 : 8|4@1+ (1,0) [0|0] "" Vector__XXX
 SG_ DIR_latchFeedback m50 : 8|1@1+ (1,0) [0|0] "" Vector__XXX
 SG_ DIR_lmScale m36 : 8|8@1+ (0.004,0) [0|0] "" Vector__XXX
 SG_ DIR_motorIA m32 : 8|16@1+ (0.1,0) [0|0] "" Vector__XXX
 SG_ DIR_offsetA m44 : 8|6@1- (0.763,0) [0|0] "" Vector__XXX
 SG_ DIR_oilPumpMotorSpeed m46 : 8|8@1+ (40,0) [0|0] "" Vector__XXX
 SG_ DIR_phaseOutBusbarTemp m70 : 8|8@1+ (1,-40) [0|0] "" Vector__XXX
 SG_ DIR_resolverOffsetCos m48 : 8|8@1+ (0.015,0) [0|0] "" Vector__XXX
 SG_ DIR_rotorOffsetEst m43 : 8|12@1- (0.01,0) [0|0] "" Vector__XXX
 SG_ DIR_rsScale m34 : 8|8@1+ (0.01,0) [0|0] "" Vector__XXX
 SG_ DIR_soptTimeToTrip m49 : 8|8@1+ (0.05,0) [0|0] "" Vector__XXX
 SG_ DIR_statorEndWindingTemp m72 : 8|8@1+ (1,-40) [0|0] "" Vector__XXX
 SG_ DIR_statorIDref m33 : 8|16@1- (0.1,0) [0|0] "" Vector__XXX
 SG_ DIR_systemStack m68 : 8|8@1+ (0.4,0) [0|0] "" Vector__XXX
 SG_ DIR_tqSatThermal m39 : 8|8@1+ (0.4,0) [0|0] "" Vector__XXX
 SG_ DIR_tqScaleDifferential m35 : 8|8@1+ (0.4,0) [0|0] "" Vector__XXX
 SG_ DIR_mechssLatchesActive m50 : 9|1@1+ (1,0) [0|0] "" Vector__XXX
 SG_ DIR_usmState m38 : 12|3@1+ (1,0) [0|0] "" Vector__XXX
 SG_ DIR_busbarTemp m64 : 16|8@1+ (1,-40) [0|0] "" Vector__XXX
 SG_ DIR_cpu10HzAvg m66 : 16|8@1+ (0.4,0) [0|0] "" Vector__XXX
 SG_ DIR_cpu1HzAvg m128 : 16|8@1+ (0.4,0) [0|0] "" Vector__XXX
 SG_ DIR_cpu1kHzAvg m67 : 16|8@1+ (0.4,0) [0|0] "" Vector__XXX
 SG_ DIR_cpuIDWord0 m131 : 16|16@1+ (1,0) [0|0] "" Vector__XXX
 SG_ DIR_cpuIDWord1 m132 : 16|16@1+ (1,0) [0|0] "" Vector__XXX
 SG_ DIR_idleStack m68 : 16|8@1+ (0.4,0) [0|0] "" Vector__XXX
 SG_ DIR_lvBoostedRail m50 : 16|8@1+ (0.08,0) [0|0] "" Vector__XXX
 SG_ DIR_offsetB m44 : 16|6@1- (0.763,0) [0|0] "" Vector__XXX
 SG_ DIR_oilPumpPhaseVoltage m46 : 16|8@1+ (0.3,0) [0|0] "" Vector__XXX
 SG_ DIR_peakIQref m38 : 16|16@1+ (0.1,0) [0|0] "" Vector__XXX
 SG_ DIR_phaseOutBusbarWeldTemp m70 : 16|8@1+ (1,-40) [0|0] "" Vector__XXX
 SG_ DIR_resolverCosRmsSquared m52 : 16|8@1+ (0.005,0) [0|0] "" Vector__XXX
 SG_ DIR_resolverOffsetSin m48 : 16|8@1+ (0.015,0) [0|0] "" Vector__XXX
 SG_ DIR_rotorFlux m47 : 16|16@1+ (0.0001,0) [0|0] "" Vector__XXX
 SG_ DIR_rotorMaxMagnetTemp m72 : 16|8@1+ (1,-40) [0|0] "" Vector__XXX
 SG_ DIR_soptTripDelay m49 : 16|8@1+ (0.05,0) [0|0] "" Vector__XXX
 SG_ DIR_statorFluxRef m35 : 16|16@1+ (0.0001,0) [0|0] "" Vector__XXX
 SG_ DIR_statorIQref m34 : 16|16@1- (0.1,0) [0|0] "" Vector__XXX
 SG_ DIR_statorVDFiltered m63 : 16|16@1- (4e-05,0) [0|0] "" Vector__XXX
 SG_ DIR_statorVQ m36 : 16|16@1- (4e-05,0) [0|0] "" Vector__XXX
 SG_ DIR_tcMaxRequest m40 : 16|8@1+ (5,0) [0|0] "" Vector__XXX
 SG_ DIR_rotorOffsetMean m43 : 20|12@1- (0.01,0) [0|0] "" Vector__XXX
 SG_ DIR_activeDischargeRail m50 : 24|8@1+ (0.3,0) [0|0] "" Vector__XXX
 SG_ DIR_cpu100HzMin m66 : 24|8@1+ (0.4,0) [0|0] "" Vector__XXX
 SG_ DIR_cpu20kHzMin m67 : 24|8@1+ (0.4,0) [0|0] "" Vector__XXX
 SG_ DIR_decodeHardwareStack m68 : 24|8@1+ (0.4,0) [0|0] "" Vector__XXX
 SG_ DIR_lightSenseV m72 : 24|6@1+ (0.1,0) [0|0] "" Vector__XXX
 SG_ DIR_llsScale m42 : 24|8@1+ (0.004,0) [0|0] "" Vector__XXX
 SG_ DIR_motorIB m32 : 24|16@1+ (0.1,0) [0|0] "" Vector__XXX
 SG_ DIR_oilPumpPressureEstimateMax m46 : 24|8@1+ (2,0) [0|0] "" Vector__XXX
 SG_ DIR_pcsTemp m64 : 24|8@1+ (1,-40) [0|0] "" Vector__XXX
 SG_ DIR_phaseOutLugTemp m70 : 24|8@1+ (1,-40) [0|0] "" Vector__XXX
 SG_ DIR_resolverPhaseOffset m48 : 24|8@1+ (0.4,0) [0|0] "" Vector__XXX
 SG_ DIR_resolverSinRmsSquared m52 : 24|8@1+ (0.005,0) [0|0] "" Vector__XXX
 SG_ DIR_soptTimeToOff m49 : 24|11@1+ (0.05,0) [0|0] "" Vector__XXX
 SG_ DIR_statorIDfdb m33 : 24|16@1- (0.1,0) [0|0] "" Vector__XXX
 SG_ DIR_tcMinRequest m40 : 24|8@1+ (5,0) [0|0] "" Vector__XXX
 SG_ DIR_pyroSenseV m72 : 30|8@1+ (0.02,0) [0|0] "" Vector__XXX
 SG_ DIR_cpu100HzAvg m66 : 32|8@1+ (0.4,0) [0|0] "" Vector__XXX
 SG_ DIR_cpu20kHzAvg m67 : 32|8@1+ (0.4,0) [0|0] "" Vector__XXX
 SG_ DIR_cpuIDWord2 m132 : 32|16@1+ (1,0) [0|0] "" Vector__XXX
 SG_ DIR_crc m131 : 32|32@1+ (1,0) [0|0] "" Vector__XXX
 SG_ DIR_dcCableHeat m47 : 32|16@1+ (0.001,0) [0|0] "" Vector__XXX
 SG_ DIR_dcLinkCapTemp m70 : 32|8@1+ (1,-40) [0|0] "" Vector__XXX
 SG_ DIR_driveUnitOdometer m69 : 32|32@1+ (10,0) [0|0] "" Vector__XXX
 SG_ DIR_eepromStack m68 : 32|8@1+ (0.4,0) [0|0] "" Vector__XXX
 SG_ DIR_llrScale m42 : 32|8@1+ (0.015,0) [0|0] "" Vector__XXX
 SG_ DIR_loadAngleMargin m37 : 32|16@1- (0.0003,0) [0|0] "" Vector__XXX
 SG_ DIR_motorIAavg m38 : 32|16@1- (0.1,0) [0|0] "" Vector__XXX
 SG_ DIR_oilPumpPressureExpectedMin m46 : 32|8@1+ (2,0) [0|0] "" Vector__XXX
 SG_ DIR_preregulatorRail m50 : 32|8@1+ (0.15,0) [0|0] "" Vector__XXX
 SG_ DIR_resolverCommonGain m48 : 32|8@1+ (0.025,0) [0|0] "" Vector__XXX
 SG_ DIR_resolverCosFiltered m52 : 32|8@1- (0.01,0) [0|0] "" Vector__XXX
 SG_ DIR_statorFluxFdb m35 : 32|16@1+ (0.0001,0) [0|0] "" Vector__XXX
 SG_ DIR_statorIQfdb m34 : 32|16@1- (0.1,0) [0|0] "" Vector__XXX
 SG_ DIR_statorTemp1 m64 : 32|8@1+ (1,-40) [0|0] "" Vector__XXX
 SG_ DIR_statorVD m36 : 32|16@1- (4e-05,0) [0|0] "" Vector__XXX
 SG_ DIR_statorVQFiltered m63 : 32|16@1- (4e-05,0) [0|0] "" Vector__XXX
 SG_ DIR_tqSatMotorVoltage m39 : 32|8@1+ (0.4,0) [0|0] "" Vector__XXX
 SG_ DIR_wasteCurrentLimit m41 : 32|16@1+ (0.1,0) [0|0] "" Vector__XXX
 SG_ DIR_controlStack m67 : 40|8@1+ (0.4,0) [0|0] "" Vector__XXX
 SG_ DIR_cpu10msMin m66 : 40|8@1+ (0.4,0) [0|0] "" Vector__XXX
 SG_ DIR_hvDcCableTemp m70 : 40|8@1+ (1,-40) [0|0] "" Vector__XXX
 SG_ DIR_loadAngle m42 : 40|16@1- (0.0003,0) [0|0] "" Vector__XXX
 SG_ DIR_motorIC m32 : 40|16@1+ (0.1,0) [0|0] "" Vector__XXX
 SG_ DIR_resolverReady m48 : 40|1@1+ (1,0) [0|0] "" Vector__XXX
 SG_ DIR_resolverSinFiltered m52 : 40|8@1- (0.01,0) [0|0] "" Vector__XXX
 SG_ DIR_soptMaxCurrentMagSqrd m49 : 40|16@1+ (100,0) [0|0] "" Vector__XXX
 SG_ DIR_statorTemp2 m64 : 40|8@1+ (1,-40) [0|0] "" Vector__XXX
 SG_ DIR_torquePerAmp m33 : 40|16@1+ (0.0001,0) [0|0] "" Vector__XXX
 SG_ DIR_tqSatMotorCurrent m39 : 40|8@1+ (0.4,0) [0|0] "" Vector__XXX
 SG_ DIR_udsStack m68 : 40|8@1+ (0.4,0) [0|0] "" Vector__XXX
 SG_ DIR_resolverNoCarrier m48 : 41|1@1+ (1,0) [0|0] "" Vector__XXX
 SG_ DIR_resolverNoPhaseLock m48 : 42|1@1+ (1,0) [0|0] "" Vector__XXX
 SG_ DIR_resolverClaMIA m48 : 43|1@1+ (1,0) [0|0] "" Vector__XXX
 SG_ DIR_statorSlotWindingTemp m72 : 46|8@1+ (1,-40) [0|0] "" Vector__XXX
 SG_ DIR_cpuIDWord3 m132 : 48|16@1+ (1,0) [0|0] "" Vector__XXX
 SG_ DIR_internalAngleFilt m37 : 48|16@1+ (0.0003,0) [0|0] "" Vector__XXX
 SG_ DIR_magnetTempEst m47 : 48|8@1+ (1,-40) [0|0] "" Vector__XXX
 SG_ DIR_module10HzStack m66 : 48|8@1+ (0.4,0) [0|0] "" Vector__XXX
 SG_ DIR_motorIBavg m38 : 48|16@1- (0.1,0) [0|0] "" Vector__XXX
 SG_ DIR_motorV m34 : 48|16@1+ (2e-05,0) [0|0] "" Vector__XXX
 SG_ DIR_negDcBusbarTemp m70 : 48|8@1+ (1,-40) [0|0] "" Vector__XXX
 SG_ DIR_peakFlux m36 : 48|16@1+ (0.0001,0) [0|0] "" Vector__XXX
 SG_ DIR_phaseImbalanceFactor m35 : 48|16@1+ (0.0001,0) [0|0] "" Vector__XXX
 SG_ DIR_pwmState m63 : 48|2@1+ (1,0) [0|0] "" Vector__XXX
 SG_ DIR_resolverErrorRmsSquared m52 : 48|8@1+ (0.005,0) [0|0] "" Vector__XXX
 SG_ DIR_tqScaleMaxMotorSpeed m40 : 48|8@1+ (0.4,0) [0|0] "" Vector__XXX
 SG_ DIR_xcpStack m68 : 48|8@1+ (0.4,0) [0|0] "" Vector__XXX
 SG_ DIR_intervalMaxHvBusV m72 : 54|10@1+ (1,0) [0|0] "" Vector__XXX
 SG_ DIR_immobilizerStack m68 : 56|8@1+ (0.4,0) [0|0] "" Vector__XXX
 SG_ DIR_posDcBusbarTemp m70 : 56|8@1+ (1,-40) [0|0] "" Vector__XXX

BO_ 2007 DI_debug: 8 Vector__XXX
 SG_ DI_debugSelector M : 0|8@1+ (1,0) [0|0] "" Vector__XXX
 SG_ DI_ONE_onePedalCommandFwd m35 : 8|16@1- (0.5,0) [0|0] "" Vector__XXX
 SG_ DI_cpu10HzMin m66 : 8|8@1+ (0.4,0) [0|0] "" Vector__XXX
 SG_ DI_cpu1kHzMin m67 : 8|8@1+ (0.4,0) [0|0] "" Vector__XXX
 SG_ DI_muSurfHigh m2 : 8|8@1+ (0.005,0) [0|0] "" Vector__XXX
 SG_ DI_pwrSatMaxDischargePower m32 : 8|8@1+ (0.4,0) [0|0] "" Vector__XXX
 SG_ DI_regenBackfillCmd m39 : 8|13@1+ (2,0) [0|0] "" Vector__XXX
 SG_ DI_sysHeatPowerOptimal m50 : 8|8@1+ (0.08,0) [0|0] "" Vector__XXX
 SG_ DI_sysPedalMinTorque m34 : 8|15@1+ (0.5,-13000) [0|0] "" Vector__XXX
 SG_ DI_sysPostPedalMinTorque m53 : 8|15@1+ (0.5,-13000) [0|0] "" Vector__XXX
 SG_ DI_systemStack m68 : 8|8@1+ (0.4,0) [0|0] "" Vector__XXX
 SG_ DI_veMassInvRaw m33 : 8|12@1+ (1e-07,0.0001) [0|0] "" Vector__XXX
 SG_ DI_ONE_feedbackTorquePed m36 : 16|16@1- (0.5,0) [0|0] "" Vector__XXX
 SG_ DI_ONE_targetSpeedFilt m37 : 16|13@1+ (0.08,-40) [0|0] "" Vector__XXX
 SG_ DI_PED_pedalTorqueFwd m38 : 16|16@1- (0.5,0) [0|0] "" Vector__XXX
 SG_ DI_aebFaultReason m45 : 16|4@1+ (1,0) [0|0] "" Vector__XXX
 SG_ DI_brakeCommandScale m2 : 16|9@1+ (0.02,0) [0|0] "" Vector__XXX
 SG_ DI_cpu10HzAvg m66 : 16|8@1+ (0.4,0) [0|0] "" Vector__XXX
 SG_ DI_cpu1kHzAvg m67 : 16|8@1+ (0.4,0) [0|0] "" Vector__XXX
 SG_ DI_idleStack m68 : 16|8@1+ (0.4,0) [0|0] "" Vector__XXX
 SG_ DI_pwrSatMaxRegenPower m32 : 16|8@1+ (0.4,0) [0|0] "" Vector__XXX
 SG_ DI_veResForce m33 : 20|12@1- (0.0005,0) [0|0] "" Vector__XXX
 SG_ DI_regenBackfillUnavailableReason m39 : 21|5@1+ (1,0) [0|0] "" Vector__XXX
 SG_ DI_ONE_zeroPedalTorqueFwd m35 : 24|16@1- (0.5,0) [0|0] "" Vector__XXX
 SG_ DI_aebUnavailableReason m45 : 24|4@1+ (1,0) [0|0] "" Vector__XXX
 SG_ DI_cpu100HzMin m66 : 24|8@1+ (0.4,0) [0|0] "" Vector__XXX
 SG_ DI_cpu20kHzMin m67 : 24|8@1+ (0.4,0) [0|0] "" Vector__XXX
 SG_ DI_decodeHardwareStack m68 : 24|8@1+ (0.4,0) [0|0] "" Vector__XXX
 SG_ DI_pwrSatMaxBusVoltage m32 : 24|8@1+ (0.4,0) [0|0] "" Vector__XXX
 SG_ DI_sysPedalMaxTorque m34 : 24|15@1+ (0.5,0) [0|0] "" Vector__XXX
 SG_ DI_sysPostPedalMaxTorque m53 : 24|15@1+ (0.5,0) [0|0] "" Vector__XXX
 SG_ DI_regenBackfillAbsSatState m39 : 26|2@1+ (1,0) [0|0] "" Vector__XXX
 SG_ DI_ONE_feedbackSpeedFilt m37 : 32|13@1+ (0.08,-40) [0|0] "" Vector__XXX
 SG_ DI_ONE_up m36 : 32|16@1- (0.5,0) [0|0] "" Vector__XXX
 SG_ DI_PED_noCruiseCommandPed m38 : 32|16@1- (0.5,0) [0|0] "" Vector__XXX
 SG_ DI_aebCancelReason m45 : 32|8@1+ (1,0) [0|0] "" Vector__XXX
 SG_ DI_cpu100HzAvg m66 : 32|8@1+ (0.4,0) [0|0] "" Vector__XXX
 SG_ DI_cpu20kHzAvg m67 : 32|8@1+ (0.4,0) [0|0] "" Vector__XXX
 SG_ DI_eepromStack m68 : 32|8@1+ (0.4,0) [0|0] "" Vector__XXX
 SG_ DI_pedalPosFilt m2 : 32|8@1+ (0.4,0) [0|0] "" Vector__XXX
 SG_ DI_pwrSatMinBusVoltage m32 : 32|8@1+ (0.4,0) [0|0] "" Vector__XXX
 SG_ DI_tqSatUiDriveTorque m33 : 32|8@1+ (0.4,0) [0|0] "" Vector__XXX
 SG_ DI_ONE_zeroSpeedTorqueFwd m35 : 40|16@1- (0.5,0) [0|0] "" Vector__XXX
 SG_ DI_controlStack m67 : 40|8@1+ (0.4,0) [0|0] "" Vector__XXX
 SG_ DI_cpu10msMin m66 : 40|8@1+ (0.4,0) [0|0] "" Vector__XXX
 SG_ DI_opdUnavailableReason m45 : 40|5@1+ (1,0) [0|0] "" Vector__XXX
 SG_ DI_pwrSatDischargeCurrent m32 : 40|8@1+ (0.4,0) [0|0] "" Vector__XXX
 SG_ DI_sysStateExitCondition m34 : 40|5@1+ (1,0) [0|0] "" Vector__XXX
 SG_ DI_systemTorqueCommand m53 : 40|16@1- (0.5,0) [0|0] "" Vector__XXX
 SG_ DI_tqSatUiRegenTorque m33 : 40|8@1+ (0.4,0) [0|0] "" Vector__XXX
 SG_ DI_udsStack m68 : 40|8@1+ (0.4,0) [0|0] "" Vector__XXX
 SG_ DI_brkStState m45 : 45|3@1+ (1,0) [0|0] "" Vector__XXX
 SG_ DI_ONE_ui m36 : 48|16@1- (0.5,0) [0|0] "" Vector__XXX
 SG_ DI_PED_zeroPedalTorque m38 : 48|16@1- (0.5,0) [0|0] "" Vector__XXX
 SG_ DI_module10HzStack m66 : 48|8@1+ (0.4,0) [0|0] "" Vector__XXX
 SG_ DI_pwrSatChargeCurrent m32 : 48|8@1+ (0.4,0) [0|0] "" Vector__XXX
 SG_ DI_tqScaleShift m33 : 48|8@1+ (0.4,0) [0|0] "" Vector__XXX
 SG_ DI_xcpStack m68 : 48|8@1+ (0.4,0) [0|0] "" Vector__XXX
 SG_ DI_aebBlendOutActive m45 : 50|1@1+ (1,0) [0|0] "" Vector__XXX
 SG_ DI_locCheckSpeedRef m75 : 54|8@1+ (1,0) [0|0] "" Vector__XXX
 SG_ DI_ONE_vehicleHoldRequested m35 : 56|1@1+ (1,0) [0|0] "" Vector__XXX
 SG_ DI_immobilizerStack m68 : 56|8@1+ (0.4,0) [0|0] "" Vector__XXX
 SG_ DI_ssmState m32 : 56|4@1+ (1,0) [0|0] "" Vector__XXX
 SG_ DI_ONE_slowBrakeBlendRequested m35 : 57|1@1+ (1,0) [0|0] "" Vector__XXX
 SG_ DI_ONE_quickBrakeBlendRequested m35 : 58|1@1+ (1,0) [0|0] "" Vector__XXX
 SG_ DI_ONE_isRollingBackward m35 : 59|1@1+ (1,0) [0|0] "" Vector__XXX
 SG_ DI_brakeSwitchNO m32 : 62|1@1+ (1,0) [0|0] "" Vector__XXX
 SG_ DI_brakeSwitchNC m32 : 63|1@1+ (1,0) [0|0] "" Vector__XXX
 SG_ DI_immobilizerCondition m65 : 63|1@1+ (1,0) [0|0] "" Vector__XXX

BO_ 2013 CP_comboDebug: 8 Vector__XXX
 SG_ CP_slacAttenuation : 0|8@1+ (1,0) [0|0] "" Vector__XXX
 SG_ CP_numEvseNodesDetected : 8|4@1+ (1,0) [0|0] "" Vector__XXX
 SG_ CP_ccsShutdownReason : 12|4@1+ (1,0) [0|0] "" Vector__XXX
 SG_ CP_plcModemConfigComplete : 16|1@1+ (1,0) [0|0] "" Vector__XXX
 SG_ CP_selectedCcsProtocol : 17|3@1+ (1,0) [0|0] "" Vector__XXX
 SG_ CP_tlsState : 20|2@1+ (1,0) [0|0] "" Vector__XXX
 SG_ CP_ccsAuthType : 22|2@1+ (1,0) [0|0] "" Vector__XXX
 SG_ CP_tlsEcdhKeyState : 24|3@1+ (1,0) [0|0] "" Vector__XXX
 SG_ CP_tlsSuperchargerDetected : 27|1@1+ (1,0) [0|0] "" Vector__XXX
 SG_ CP_certificateState : 28|3@1+ (1,0) [0|0] "" Vector__XXX
 SG_ CP_pncIso15118OkToUse : 31|1@1+ (1,0) [0|0] "" Vector__XXX
 SG_ CP_tlsPncCpoDetected : 32|1@1+ (1,0) [0|0] "" Vector__XXX
 SG_ CP_kvasSelectStatus : 33|2@1+ (1,0) [0|0] "" Vector__XXX
 SG_ CP_ccsEnergyType : 35|2@1+ (1,0) [0|0] "" Vector__XXX
 SG_ CP_kvasVinEncrypted : 37|1@1+ (1,0) [0|0] "" Vector__XXX

BO_ 2014 UDS_functionalRequest_CH: 12 Vector__XXX
 SG_ UDS_functionalRequestDataCH : 7|64@0+ (1,0) [0|0] "" Vector__XXX

BO_ 2015 UDS_functionalRequest: 12 Vector__XXX
 SG_ UDS_functionalRequestData_0 : 7|8@0+ (1,0) [0|0] "" Vector__XXX
 SG_ UDS_functionalRequestData_1 : 15|8@0+ (1,0) [0|0] "" Vector__XXX
 SG_ UDS_functionalRequestData_2 : 23|8@0+ (1,0) [0|0] "" Vector__XXX
 SG_ UDS_functionalRequestData_3 : 31|8@0+ (1,0) [0|0] "" Vector__XXX
 SG_ UDS_functionalRequestData_4 : 39|8@0+ (1,0) [0|0] "" Vector__XXX
 SG_ UDS_functionalRequestData_5 : 47|8@0+ (1,0) [0|0] "" Vector__XXX
 SG_ UDS_functionalRequestData_6 : 55|8@0+ (1,0) [0|0] "" Vector__XXX
 SG_ UDS_functionalRequestData_7 : 63|8@0+ (1,0) [0|0] "" Vector__XXX

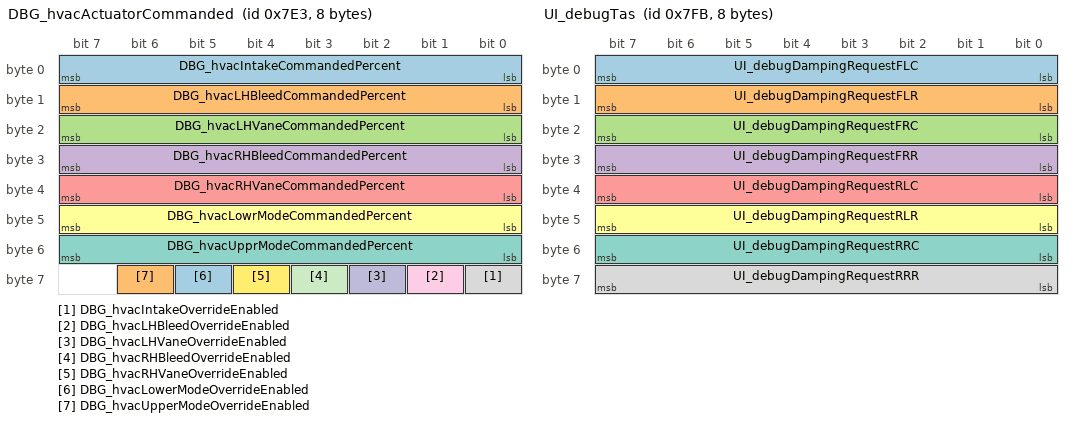
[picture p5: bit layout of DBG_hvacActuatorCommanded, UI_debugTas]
BO_ 2019 DBG_hvacActuatorCommanded: 8 Vector__XXX
 SG_ DBG_hvacIntakeCommandedPercent : 0|8@1+ (0.4,0) [0|0] "" Vector__XXX
 SG_ DBG_hvacLHBleedCommandedPercent : 8|8@1+ (0.4,0) [0|0] "" Vector__XXX
 SG_ DBG_hvacLHVaneCommandedPercent : 16|8@1+ (0.4,0) [0|0] "" Vector__XXX
 SG_ DBG_hvacRHBleedCommandedPercent : 24|8@1+ (0.4,0) [0|0] "" Vector__XXX
 SG_ DBG_hvacRHVaneCommandedPercent : 32|8@1+ (0.4,0) [0|0] "" Vector__XXX
 SG_ DBG_hvacLowrModeCommandedPercent : 40|8@1+ (0.4,0) [0|0] "" Vector__XXX
 SG_ DBG_hvacUpprModeCommandedPercent : 48|8@1+ (0.4,0) [0|0] "" Vector__XXX
 SG_ DBG_hvacIntakeOverrideEnabled : 56|1@1+ (1,0) [0|0] "" Vector__XXX
 SG_ DBG_hvacLHBleedOverrideEnabled : 57|1@1+ (1,0) [0|0] "" Vector__XXX
 SG_ DBG_hvacLHVaneOverrideEnabled : 58|1@1+ (1,0) [0|0] "" Vector__XXX
 SG_ DBG_hvacRHBleedOverrideEnabled : 59|1@1+ (1,0) [0|0] "" Vector__XXX
 SG_ DBG_hvacRHVaneOverrideEnabled : 60|1@1+ (1,0) [0|0] "" Vector__XXX
 SG_ DBG_hvacLowerModeOverrideEnabled : 61|1@1+ (1,0) [0|0] "" Vector__XXX
 SG_ DBG_hvacUpperModeOverrideEnabled : 62|1@1+ (1,0) [0|0] "" Vector__XXX

BO_ 2021 DIR_dlogData: 8 Vector__XXX
 SG_ DIR_dlogData : 0|64@1+ (1,0) [0|0] "" Vector__XXX

BO_ 2024 EPBR_info: 8 Vector__XXX
 SG_ EPBR_infoIndex M : 0|8@1+ (1,0) [0|0] "" Vector__XXX
 SG_ EPBR_infoAppCrc m13 : 8|32@1+ (1,0) [0|0] "" Vector__XXX
 SG_ EPBR_infoAppGitHash m17 : 8|56@1+ (1,0) [0|0] "" Vector__XXX
 SG_ EPBR_infoBootGitHash m18 : 8|56@1+ (1,0) [0|0] "" Vector__XXX
 SG_ EPBR_infoBootUdsProtoVersion m20 : 8|16@1+ (1,0) [0|0] "" Vector__XXX
 SG_ EPBR_infoBuildType m10 : 8|3@1+ (1,0) [0|0] "" Vector__XXX
 SG_ EPBR_infoPcbaId m11 : 8|8@1+ (1,0) [0|0] "" Vector__XXX
 SG_ EPBR_infoPlatformType m19 : 8|8@1+ (1,0) [0|0] "" Vector__XXX
 SG_ EPBR_infoAssemblyId m11 : 16|8@1+ (1,0) [0|0] "" Vector__XXX
 SG_ EPBR_infoBuildConfigId m10 : 16|16@1+ (1,0) [0|0] "" Vector__XXX
 SG_ EPBR_infoBootCrc m20 : 24|32@1+ (1,0) [0|0] "" Vector__XXX
 SG_ EPBR_infoUsageId m11 : 24|16@1+ (1,0) [0|0] "" Vector__XXX
 SG_ EPBR_infoHardwareId m10 : 32|16@1+ (1,0) [0|0] "" Vector__XXX
 SG_ EPBR_infoSubUsageId m11 : 40|16@1+ (1,0) [0|0] "" Vector__XXX
 SG_ EPBR_infoComponentId m10 : 48|16@1+ (1,0) [0|0] "" Vector__XXX

BO_ 2031 DBG_testMessage: 8 Vector__XXX
 SG_ DBG_testID : 0|16@1+ (1,0) [0|0] "" Vector__XXX

BO_ 2033 GTW_hrl: 8 Vector__XXX
 SG_ GTW_hrlIndex M : 0|2@1+ (1,0) [0|0] "" Vector__XXX
 SG_ GTW_hrlState m2 : 2|1@1+ (1,0) [0|0] "" Vector__XXX
 SG_ GTW_hrlPagesCount m1 : 15|32@0+ (1,0) [0|0] "" Vector__XXX
 SG_ GTW_hrlTriggerDuration m2 : 15|16@0+ (1,0) [0|0] "" Vector__XXX
 SG_ GTW_hrlTriggerType m2 : 24|4@1+ (1,0) [0|0] "" Vector__XXX
 SG_ GTW_hrlTriggerId m2 : 39|16@0+ (1,0) [0|0] "" Vector__XXX
 SG_ GTW_hrlTriggerBus m2 : 55|3@0+ (1,0) [0|0] "" Vector__XXX

BO_ 2034 BMS_debugInfo_10Hz: 8 Vector__XXX
 SG_ BMS_10HzDebug_Id M : 0|6@1+ (1,0) [0|0] "" Vector__XXX
 SG_ BMS_allBricksRestingForCac m17 : 6|1@1+ (1,0) [0|0] "" Vector__XXX
 SG_ BMS_dbgPcsReportedOn m0 : 6|1@1+ (1,0) [0|0] "" Vector__XXX
 SG_ BMS_dbgSocByOcvMax m16 : 6|10@1+ (0.1,0) [0|0] "" Vector__XXX
 SG_ BMS_thmMdlDBG1 m12 : 6|10@1+ (0.1,-30) [0|0] "" Vector__XXX
 SG_ BMS_thmMdlDBG11 m14 : 6|10@1+ (0.1,-30) [0|0] "" Vector__XXX
 SG_ BMS_thmMdlDBG6 m13 : 6|10@1+ (0.1,-30) [0|0] "" Vector__XXX
 SG_ BMS_vshTestNeededTimer m20 : 6|18@1+ (1,0) [0|0] "" Vector__XXX
 SG_ BMS_dbgPcsIsActiveOnHvs m0 : 7|1@1+ (1,0) [0|0] "" Vector__XXX
 SG_ BMS_agedChargePolarization m33 : 8|12@1+ (0.002,0) [0|0] "" Vector__XXX
 SG_ BMS_ahCharge m1 : 8|24@1+ (0.1,0) [0|0] "" Vector__XXX
 SG_ BMS_avgCacError m19 : 8|9@1+ (0.2,0) [0|0] "" Vector__XXX
 SG_ BMS_brickRestingForCac m17 : 8|1@1+ (1,0) [0|0] "" Vector__XXX
 SG_ BMS_cacNetAhCounter m18 : 8|11@1- (1,0) [0|0] "" Vector__XXX
 SG_ BMS_dbg3v0ReferenceBms m21 : 8|16@1+ (0.001,0) [0|0] "" Vector__XXX
 SG_ BMS_dbgCpPositiveV m22 : 8|16@1- (0.02,0) [0|0] "" Vector__XXX
 SG_ BMS_dbgDcLinkPositiveV m23 : 8|16@1- (0.02,0) [0|0] "" Vector__XXX
 SG_ BMS_dbgFloodPortV1 m25 : 8|16@1+ (0.001,0) [0|0] "" Vector__XXX
 SG_ BMS_dbgMaxLoadedVoltageDischarge m26 : 8|16@1+ (0.0001,0) [0|0] "" Vector__XXX
 SG_ BMS_dbgPolarizationVoltageV1 m27 : 8|16@1- (0.0001,0) [0|0] "" Vector__XXX
 SG_ BMS_dbgResistanceR2 m28 : 8|16@1+ (0.001,0) [0|0] "" Vector__XXX
 SG_ BMS_dbgStandbySupplyOutV m30 : 8|16@1+ (0.001,0) [0|0] "" Vector__XXX
 SG_ BMS_dbgVerSenseV m24 : 8|16@1+ (0.001,0) [0|0] "" Vector__XXX
 SG_ BMS_driveBrickVoltageTarget m31 : 8|10@1+ (0.01,0) [0|0] "" Vector__XXX
 SG_ BMS_faultRetryCount m0 : 8|3@1+ (1,0) [0|0] "" Vector__XXX
 SG_ BMS_hviBusResourceState m29 : 8|3@1+ (1,0) [0|0] "" Vector__XXX
 SG_ BMS_isolationMode m2 : 8|3@1+ (1,0) [0|0] "" Vector__XXX
 SG_ BMS_maxSocByAhRaw m32 : 8|11@1+ (0.1,0) [0|0] "" Vector__XXX
 SG_ BMS_minBrickOcvMax m3 : 8|12@1+ (0.002,0) [0|0] "" Vector__XXX
 SG_ BMS_sumBrickVoltages m15 : 8|15@1+ (0.02,0) [0|0] "" Vector__XXX
 SG_ BMS_cacActivePoint m17 : 9|2@1+ (1,0) [0|0] "" Vector__XXX
 SG_ BMS_hvsBusResourceState m29 : 11|3@1+ (1,0) [0|0] "" Vector__XXX
 SG_ BMS_impedanceDevState m0 : 11|2@1+ (1,0) [0|0] "" Vector__XXX
 SG_ BMS_initialCacPointValid m17 : 11|1@1+ (1,0) [0|0] "" Vector__XXX
 SG_ BMS_negativeRIsoState m2 : 11|3@1+ (1,0) [0|0] "" Vector__XXX
 SG_ BMS_candidate1CacPointValid m17 : 12|1@1+ (1,0) [0|0] "" Vector__XXX
 SG_ BMS_candidate2CacPointValid m17 : 13|1@1+ (1,0) [0|0] "" Vector__XXX
 SG_ BMS_refPointDeltaSoc m17 : 14|10@1+ (0.1,0) [0|0] "" Vector__XXX
 SG_ BMS_dbgSocByOcvMin m16 : 16|10@1+ (0.1,0) [0|0] "" Vector__XXX
 SG_ BMS_positiveRIsoState m2 : 16|3@1+ (1,0) [0|0] "" Vector__XXX
 SG_ BMS_thmMdlDBG12 m14 : 16|10@1+ (0.1,-30) [0|0] "" Vector__XXX
 SG_ BMS_thmMdlDBG2 m12 : 16|10@1+ (0.1,-30) [0|0] "" Vector__XXX
 SG_ BMS_thmMdlDBG7 m13 : 16|10@1+ (0.1,-30) [0|0] "" Vector__XXX
 SG_ BMS_vehBusResourceState m29 : 16|3@1+ (1,0) [0|0] "" Vector__XXX
 SG_ BMS_cacNetAhError m18 : 19|8@1+ (0.1,0) [0|0] "" Vector__XXX
 SG_ BMS_cpResourceState m29 : 19|3@1+ (1,0) [0|0] "" Vector__XXX
 SG_ BMS_maxSocByAhRawBrickId m32 : 19|7@1+ (1,1) [0|0] "" Vector__XXX
 SG_ BMS_negIsolationSensorState m2 : 19|1@1+ (1,0) [0|0] "" Vector__XXX
 SG_ BMS_agedDischargePolarization m33 : 20|12@1+ (0.002,0) [0|0] "" Vector__XXX
 SG_ BMS_minBrickOcvMin m3 : 20|12@1+ (0.002,0) [0|0] "" Vector__XXX
 SG_ BMS_posIsolationSensorState m2 : 20|1@1+ (1,0) [0|0] "" Vector__XXX
 SG_ BMS_dbg3v0ReferenceHvp m21 : 24|16@1+ (0.001,0) [0|0] "" Vector__XXX
 SG_ BMS_dbgCapacitanceC1 m28 : 24|16@1+ (0.1,0) [0|0] "" Vector__XXX
 SG_ BMS_dbgCpNegativeV m22 : 24|16@1- (0.02,0) [0|0] "" Vector__XXX
 SG_ BMS_dbgDcLinkNegativeV m23 : 24|16@1- (0.02,0) [0|0] "" Vector__XXX
 SG_ BMS_dbgFloodPortV2 m25 : 24|16@1+ (0.001,0) [0|0] "" Vector__XXX
 SG_ BMS_dbgInternalHvilSenseV m24 : 24|16@1+ (0.001,0) [0|0] "" Vector__XXX
 SG_ BMS_dbgMinLoadedVoltageDischarge m26 : 24|16@1+ (0.0001,0) [0|0] "" Vector__XXX
 SG_ BMS_dbgPolarizationVoltageV2 m27 : 24|16@1- (0.0001,0) [0|0] "" Vector__XXX
 SG_ BMS_dbgStandbySupplyEnabled m30 : 24|1@1+ (1,0) [0|0] "" Vector__XXX
 SG_ BMS_hvpResourceState m29 : 24|3@1+ (1,0) [0|0] "" Vector__XXX
 SG_ BMS_packNegativeV m15 : 24|16@1- (0.02,0) [0|0] "" Vector__XXX
 SG_ BMS_refPointDeltaAh m17 : 24|11@1- (0.5,0) [0|0] "" Vector__XXX
 SG_ BMS_stdCacError m19 : 24|8@1+ (0.2,0) [0|0] "" Vector__XXX
 SG_ BMS_stopSecondsElapsed m20 : 24|16@1+ (1,0) [0|0] "" Vector__XXX
 SG_ BMS_dbgStandbySupplyGood m30 : 25|1@1+ (1,0) [0|0] "" Vector__XXX
 SG_ BMS_dbgSocByOcvEst m16 : 26|10@1+ (0.1,0) [0|0] "" Vector__XXX
 SG_ BMS_ocvMinBrick1 m32 : 26|12@1+ (0.002,0) [0|0] "" Vector__XXX
 SG_ BMS_thmMdlDBG13 m14 : 26|10@1+ (0.1,-30) [0|0] "" Vector__XXX
 SG_ BMS_thmMdlDBG3 m12 : 26|10@1+ (0.1,-30) [0|0] "" Vector__XXX
 SG_ BMS_thmMdlDBG8 m13 : 26|10@1+ (0.1,-30) [0|0] "" Vector__XXX
 SG_ BMS_cacEstimateBrick1 m18 : 27|10@1+ (0.5,75) [0|0] "" Vector__XXX
 SG_ BMS_pcsResourceState m29 : 27|3@1+ (1,0) [0|0] "" Vector__XXX
 SG_ BMS_ahDischarge m1 : 32|24@1+ (0.1,0) [0|0] "" Vector__XXX
 SG_ BMS_bmsResourceState m29 : 32|3@1+ (1,0) [0|0] "" Vector__XXX
 SG_ BMS_dbgBrick1OcvAccuracyBuffer m33 : 32|13@1+ (0.01,0) [0|0] "" Vector__XXX
 SG_ BMS_minBrickOcvIndex m3 : 32|7@1+ (1,0) [0|0] "" Vector__XXX
 SG_ BMS_refPointDeltaAhError m17 : 35|9@1- (0.05,0) [0|0] "" Vector__XXX
 SG_ BMS_verResourceState m29 : 35|3@1+ (1,0) [0|0] "" Vector__XXX
 SG_ BMS_thmMdlDBG4 m12 : 36|10@1+ (0.1,-30) [0|0] "" Vector__XXX
 SG_ BMS_thmMdlDBG9 m13 : 36|10@1+ (0.1,-30) [0|0] "" Vector__XXX
 SG_ BMS_cacInitialPtSocByOcv m18 : 37|10@1+ (0.1,0) [0|0] "" Vector__XXX
 SG_ BMS_ocvMaxBrick1 m32 : 38|12@1+ (0.002,0) [0|0] "" Vector__XXX
 SG_ BMS_isResting m3 : 39|1@1+ (1,0) [0|0] "" Vector__XXX
 SG_ BMS_dbg1v5ReferenceHvp m21 : 40|16@1+ (0.001,0) [0|0] "" Vector__XXX
 SG_ BMS_dbgCapacitanceC2 m28 : 40|16@1+ (0.1,0) [0|0] "" Vector__XXX
 SG_ BMS_dbgCpFaultInputV m22 : 40|16@1+ (0.001,0) [0|0] "" Vector__XXX
 SG_ BMS_dbgCpLatchEnableV m25 : 40|16@1+ (0.001,0) [0|0] "" Vector__XXX
 SG_ BMS_dbgDcLinkCtrSenseCurrent m23 : 40|16@1+ (0.01,0) [0|0] "" Vector__XXX
 SG_ BMS_dbgHvilCoverVSense m24 : 40|16@1+ (0.001,0) [0|0] "" Vector__XXX
 SG_ BMS_dbgMaxCurrentDischarge m26 : 40|14@1+ (0.15,0) [0|0] "" Vector__XXX
 SG_ BMS_dbgResistanceR1 m27 : 40|16@1+ (0.001,0) [0|0] "" Vector__XXX
 SG_ BMS_packPositiveV m15 : 40|16@1- (0.02,0) [0|0] "" Vector__XXX
 SG_ BMS_restTime1 m20 : 40|15@1+ (0.1,0) [0|0] "" Vector__XXX
 SG_ BMS_sleepState m29 : 40|3@1+ (1,0) [0|0] "" Vector__XXX
 SG_ BMS_socRestingCurrentThreshold m3 : 40|12@1+ (0.001,0) [0|0] "" Vector__XXX
 SG_ BMS_sleepRequest m29 : 43|3@1+ (1,0) [0|0] "" Vector__XXX
 SG_ BMS_refPointCacError1 m17 : 44|9@1+ (0.2,0) [0|0] "" Vector__XXX
 SG_ BMS_hviBusResourceRequest m29 : 46|2@1+ (1,0) [0|0] "" Vector__XXX
 SG_ BMS_thmMdlDBG10 m13 : 46|10@1+ (0.1,-30) [0|0] "" Vector__XXX
 SG_ BMS_thmMdlDBG5 m12 : 46|10@1+ (0.1,-30) [0|0] "" Vector__XXX
 SG_ BMS_cacUpdateCounter m18 : 47|3@1+ (1,0) [0|0] "" Vector__XXX
 SG_ BMS_hvsBusResourceRequest m29 : 48|2@1+ (1,0) [0|0] "" Vector__XXX
 SG_ BMS_cacUpdateStartPoint m18 : 50|2@1+ (1,0) [0|0] "" Vector__XXX
 SG_ BMS_ocvEstBrick1 m32 : 50|12@1+ (0.002,0) [0|0] "" Vector__XXX
 SG_ BMS_vehBusResourceRequest m29 : 50|2@1+ (1,0) [0|0] "" Vector__XXX
 SG_ BMS_cacUpdateEndPoint m18 : 52|2@1+ (1,0) [0|0] "" Vector__XXX
 SG_ BMS_cpResourceRequest m29 : 52|2@1+ (1,0) [0|0] "" Vector__XXX
 SG_ BMS_refPointCacError2 m17 : 53|9@1+ (0.2,0) [0|0] "" Vector__XXX
 SG_ BMS_cacUpdateError m18 : 54|9@1+ (0.2,0) [0|0] "" Vector__XXX
 SG_ BMS_hvpResourceRequest m29 : 54|2@1+ (1,0) [0|0] "" Vector__XXX
 SG_ BMS_bmsResourceRequest m29 : 56|2@1+ (1,0) [0|0] "" Vector__XXX
 SG_ BMS_dbgResistanceScaleChg m28 : 56|8@1+ (0.02,0) [0|0] "" Vector__XXX
 SG_ BMS_dbgResistanceScaleDch m27 : 56|8@1+ (0.02,0) [0|0] "" Vector__XXX
 SG_ BMS_verResourceRequest m29 : 58|2@1+ (1,0) [0|0] "" Vector__XXX

BO_ 2036 GTW_canLogAvailability: 8 Vector__XXX
 SG_ GTW_canLogServiceAvailability : 0|2@1+ (1,0) [0|0] "" Vector__XXX

BO_ 2043 UI_debugTas: 8 Vector__XXX
 SG_ UI_debugDampingRequestFLC : 0|8@1+ (0.01,0) [0|0] "" Vector__XXX
 SG_ UI_debugDampingRequestFLR : 8|8@1+ (0.01,0) [0|0] "" Vector__XXX
 SG_ UI_debugDampingRequestFRC : 16|8@1+ (0.01,0) [0|0] "" Vector__XXX
 SG_ UI_debugDampingRequestFRR : 24|8@1+ (0.01,0) [0|0] "" Vector__XXX
 SG_ UI_debugDampingRequestRLC : 32|8@1+ (0.01,0) [0|0] "" Vector__XXX
 SG_ UI_debugDampingRequestRLR : 40|8@1+ (0.01,0) [0|0] "" Vector__XXX
 SG_ UI_debugDampingRequestRRC : 48|8@1+ (0.01,0) [0|0] "" Vector__XXX
 SG_ UI_debugDampingRequestRRR : 56|8@1+ (0.01,0) [0|0] "" Vector__XXX

BO_ 2046 PCS2_DRLog: 8 Vector__XXX
 SG_ PCS2_DRLogIndex M : 0|8@1+ (1,0) [0|0] "" Vector__XXX
 SG_ PCS2_DRLog_CPU0_DlogClientConnected m3 : 8|1@1+ (1,0) [0|0] "" Vector__XXX
 SG_ PCS2_DRLog_CPU0_Postamble m4 : 8|56@1+ (1,0) [0|0] "" Vector__XXX
 SG_ PCS2_DRLog_CPU0_Preamble m0 : 8|56@1+ (1,0) [0|0] "" Vector__XXX
 SG_ PCS2_DRLog_CPU0_SampleRate m2 : 8|8@1+ (1,0) [0|0] "" Vector__XXX
 SG_ PCS2_DRLog_CPU0_SampleRate_10V0_rail_vsense m170 : 8|8@1+ (1,0) [0|0] "" Vector__XXX
 SG_ PCS2_DRLog_CPU0_SampleRate_18V0_LLC_Freq m118 : 8|8@1+ (1,0) [0|0] "" Vector__XXX
 SG_ PCS2_DRLog_CPU0_SampleRate_18V0_Voltage m117 : 8|8@1+ (1,0) [0|0] "" Vector__XXX
 SG_ PCS2_DRLog_CPU0_SampleRate_18V0_boost_duty m160 : 8|8@1+ (1,0) [0|0] "" Vector__XXX
 SG_ PCS2_DRLog_CPU0_SampleRate_18V0_buck_duty m169 : 8|8@1+ (1,0) [0|0] "" Vector__XXX
 SG_ PCS2_DRLog_CPU0_SampleRate_1V6_ref_vsense m172 : 8|8@1+ (1,0) [0|0] "" Vector__XXX
 SG_ PCS2_DRLog_CPU0_SampleRate_4V5_rail_vsense m171 : 8|8@1+ (1,0) [0|0] "" Vector__XXX
 SG_ PCS2_DRLog_CPU0_SampleRate_boost_isense_peak m173 : 8|8@1+ (1,0) [0|0] "" Vector__XXX
 SG_ PCS2_DRLog_CPU0_SampleRate_boost_isense_valley m175 : 8|8@1+ (1,0) [0|0] "" Vector__XXX
 SG_ PCS2_DRLog_CPU0_SampleRate_buck_boost_lv_vsense m174 : 8|8@1+ (1,0) [0|0] "" Vector__XXX
 SG_ PCS2_DRLog_CPU0_SampleRate_burst_mode m158 : 8|8@1+ (1,0) [0|0] "" Vector__XXX
 SG_ PCS2_DRLog_CPU0_SampleRate_channel8 m119 : 8|8@1+ (1,0) [0|0] "" Vector__XXX
 SG_ PCS2_DRLog_CPU0_SampleRate_dcdc_vHv m163 : 8|8@1+ (1,0) [0|0] "" Vector__XXX
 SG_ PCS2_DRLog_CPU0_SampleRate_dcdc_vHv_bot m116 : 8|8@1+ (1,0) [0|0] "" Vector__XXX
 SG_ PCS2_DRLog_CPU0_SampleRate_dcdc_vHv_top m102 : 8|8@1+ (1,0) [0|0] "" Vector__XXX
 SG_ PCS2_DRLog_CPU0_SampleRate_dcdc_vLv m103 : 8|8@1+ (1,0) [0|0] "" Vector__XXX
 SG_ PCS2_DRLog_CPU0_SampleRate_freq m112 : 8|8@1+ (1,0) [0|0] "" Vector__XXX
 SG_ PCS2_DRLog_CPU0_SampleRate_half_bus_comp m113 : 8|8@1+ (1,0) [0|0] "" Vector__XXX
 SG_ PCS2_DRLog_CPU0_SampleRate_half_period_pu m100 : 8|8@1+ (1,0) [0|0] "" Vector__XXX
 SG_ PCS2_DRLog_CPU0_SampleRate_i_HV_cl_sinking m115 : 8|8@1+ (1,0) [0|0] "" Vector__XXX
 SG_ PCS2_DRLog_CPU0_SampleRate_i_HV_cl_sourcing m114 : 8|8@1+ (1,0) [0|0] "" Vector__XXX
 SG_ PCS2_DRLog_CPU0_SampleRate_i_HV_cmd m101 : 8|8@1+ (1,0) [0|0] "" Vector__XXX
 SG_ PCS2_DRLog_CPU0_SampleRate_itank m104 : 8|8@1+ (1,0) [0|0] "" Vector__XXX
 SG_ PCS2_DRLog_CPU0_SampleRate_itank_margin_fb m109 : 8|8@1+ (1,0) [0|0] "" Vector__XXX
 SG_ PCS2_DRLog_CPU0_SampleRate_shrt_margin_fb m108 : 8|8@1+ (1,0) [0|0] "" Vector__XXX
 SG_ PCS2_DRLog_CPU0_SampleRate_shrt_margin_ref m107 : 8|8@1+ (1,0) [0|0] "" Vector__XXX
 SG_ PCS2_DRLog_CPU0_SampleRate_theta_HV m110 : 8|8@1+ (1,0) [0|0] "" Vector__XXX
 SG_ PCS2_DRLog_CPU0_SampleRate_theta_LV m111 : 8|8@1+ (1,0) [0|0] "" Vector__XXX
 SG_ PCS2_DRLog_CPU0_SampleRate_zcd_flt_cnt m105 : 8|8@1+ (1,0) [0|0] "" Vector__XXX
 SG_ PCS2_DRLog_CPU0_SampleRate_zcd_fltd m106 : 8|8@1+ (1,0) [0|0] "" Vector__XXX
 SG_ PCS2_DRLog_CPU0_SampleRate_zcd_rising_pu m165 : 8|8@1+ (1,0) [0|0] "" Vector__XXX
 SG_ PCS2_DRLog_CPU0_Version m1 : 8|8@1+ (1,0) [0|0] "" Vector__XXX
 SG_ PCS2_DRLog_CPU1_DlogClientConnected m13 : 8|1@1+ (1,0) [0|0] "" Vector__XXX
 SG_ PCS2_DRLog_CPU1_Postamble m14 : 8|56@1+ (1,0) [0|0] "" Vector__XXX
 SG_ PCS2_DRLog_CPU1_Preamble m10 : 8|56@1+ (1,0) [0|0] "" Vector__XXX
 SG_ PCS2_DRLog_CPU1_SampleRate m12 : 8|8@1+ (1,0) [0|0] "" Vector__XXX
 SG_ PCS2_DRLog_CPU1_SampleRate_18V0_LLC_Freq m138 : 8|8@1+ (1,0) [0|0] "" Vector__XXX
 SG_ PCS2_DRLog_CPU1_SampleRate_18V0_Voltage m137 : 8|8@1+ (1,0) [0|0] "" Vector__XXX
 SG_ PCS2_DRLog_CPU1_SampleRate_18V0_boost_duty m161 : 8|8@1+ (1,0) [0|0] "" Vector__XXX
 SG_ PCS2_DRLog_CPU1_SampleRate_burst_mode m159 : 8|8@1+ (1,0) [0|0] "" Vector__XXX
 SG_ PCS2_DRLog_CPU1_SampleRate_dcdc_iHv m139 : 8|8@1+ (1,0) [0|0] "" Vector__XXX
 SG_ PCS2_DRLog_CPU1_SampleRate_dcdc_vHv m164 : 8|8@1+ (1,0) [0|0] "" Vector__XXX
 SG_ PCS2_DRLog_CPU1_SampleRate_dcdc_vHv_bot m123 : 8|8@1+ (1,0) [0|0] "" Vector__XXX
 SG_ PCS2_DRLog_CPU1_SampleRate_dcdc_vHv_top m126 : 8|8@1+ (1,0) [0|0] "" Vector__XXX
 SG_ PCS2_DRLog_CPU1_SampleRate_dcdc_vLv m127 : 8|8@1+ (1,0) [0|0] "" Vector__XXX
 SG_ PCS2_DRLog_CPU1_SampleRate_freq m136 : 8|8@1+ (1,0) [0|0] "" Vector__XXX
 SG_ PCS2_DRLog_CPU1_SampleRate_half_bus_comp m120 : 8|8@1+ (1,0) [0|0] "" Vector__XXX
 SG_ PCS2_DRLog_CPU1_SampleRate_half_period_pu m124 : 8|8@1+ (1,0) [0|0] "" Vector__XXX
 SG_ PCS2_DRLog_CPU1_SampleRate_i_HV_cl_sinking m122 : 8|8@1+ (1,0) [0|0] "" Vector__XXX
 SG_ PCS2_DRLog_CPU1_SampleRate_i_HV_cl_sourcing m121 : 8|8@1+ (1,0) [0|0] "" Vector__XXX
 SG_ PCS2_DRLog_CPU1_SampleRate_i_HV_cmd m125 : 8|8@1+ (1,0) [0|0] "" Vector__XXX
 SG_ PCS2_DRLog_CPU1_SampleRate_itank m128 : 8|8@1+ (1,0) [0|0] "" Vector__XXX
 SG_ PCS2_DRLog_CPU1_SampleRate_itank_margin_fb m133 : 8|8@1+ (1,0) [0|0] "" Vector__XXX
 SG_ PCS2_DRLog_CPU1_SampleRate_shrt_margin_fb m132 : 8|8@1+ (1,0) [0|0] "" Vector__XXX
 SG_ PCS2_DRLog_CPU1_SampleRate_shrt_margin_ref m131 : 8|8@1+ (1,0) [0|0] "" Vector__XXX
 SG_ PCS2_DRLog_CPU1_SampleRate_theta_HV m134 : 8|8@1+ (1,0) [0|0] "" Vector__XXX
 SG_ PCS2_DRLog_CPU1_SampleRate_theta_LV m135 : 8|8@1+ (1,0) [0|0] "" Vector__XXX
 SG_ PCS2_DRLog_CPU1_SampleRate_zcd_flt_cnt m129 : 8|8@1+ (1,0) [0|0] "" Vector__XXX
 SG_ PCS2_DRLog_CPU1_SampleRate_zcd_fltd m130 : 8|8@1+ (1,0) [0|0] "" Vector__XXX
 SG_ PCS2_DRLog_CPU1_SampleRate_zcd_rising_pu m166 : 8|8@1+ (1,0) [0|0] "" Vector__XXX
 SG_ PCS2_DRLog_CPU1_Version m11 : 8|8@1+ (1,0) [0|0] "" Vector__XXX
 SG_ PCS2_DRLog_CPU2_DlogClientConnected m23 : 8|1@1+ (1,0) [0|0] "" Vector__XXX
 SG_ PCS2_DRLog_CPU2_Postamble m24 : 8|56@1+ (1,0) [0|0] "" Vector__XXX
 SG_ PCS2_DRLog_CPU2_Preamble m20 : 8|56@1+ (1,0) [0|0] "" Vector__XXX
 SG_ PCS2_DRLog_CPU2_SampleRate m22 : 8|8@1+ (1,0) [0|0] "" Vector__XXX
 SG_ PCS2_DRLog_CPU2_Version m21 : 8|8@1+ (1,0) [0|0] "" Vector__XXX
 SG_ PCS2_DRLog_CPU3_DlogClientConnected m33 : 8|1@1+ (1,0) [0|0] "" Vector__XXX
 SG_ PCS2_DRLog_CPU3_Postamble m34 : 8|56@1+ (1,0) [0|0] "" Vector__XXX
 SG_ PCS2_DRLog_CPU3_Preamble m30 : 8|56@1+ (1,0) [0|0] "" Vector__XXX
 SG_ PCS2_DRLog_CPU3_SampleRate m32 : 8|8@1+ (1,0) [0|0] "" Vector__XXX
 SG_ PCS2_DRLog_CPU3_SampleRate_18V0_LLC_Freq m157 : 8|8@1+ (1,0) [0|0] "" Vector__XXX
 SG_ PCS2_DRLog_CPU3_SampleRate_18V0_Voltage m156 : 8|8@1+ (1,0) [0|0] "" Vector__XXX
 SG_ PCS2_DRLog_CPU3_SampleRate_18V0_boost_duty m162 : 8|8@1+ (1,0) [0|0] "" Vector__XXX
 SG_ PCS2_DRLog_CPU3_SampleRate_Itank_margin m144 : 8|8@1+ (1,0) [0|0] "" Vector__XXX
 SG_ PCS2_DRLog_CPU3_SampleRate_freq m151 : 8|8@1+ (1,0) [0|0] "" Vector__XXX
 SG_ PCS2_DRLog_CPU3_SampleRate_hvdc_current m155 : 8|8@1+ (1,0) [0|0] "" Vector__XXX
 SG_ PCS2_DRLog_CPU3_SampleRate_i_ac_cmd_l1 m148 : 8|8@1+ (1,0) [0|0] "" Vector__XXX
 SG_ PCS2_DRLog_CPU3_SampleRate_i_ac_cmd_l2 m149 : 8|8@1+ (1,0) [0|0] "" Vector__XXX
 SG_ PCS2_DRLog_CPU3_SampleRate_i_ac_cmd_l3 m153 : 8|8@1+ (1,0) [0|0] "" Vector__XXX
 SG_ PCS2_DRLog_CPU3_SampleRate_i_ac_ref_l1 m147 : 8|8@1+ (1,0) [0|0] "" Vector__XXX
 SG_ PCS2_DRLog_CPU3_SampleRate_i_ln_l1 m142 : 8|8@1+ (1,0) [0|0] "" Vector__XXX
 SG_ PCS2_DRLog_CPU3_SampleRate_i_ln_l2 m143 : 8|8@1+ (1,0) [0|0] "" Vector__XXX
 SG_ PCS2_DRLog_CPU3_SampleRate_i_ln_l3 m154 : 8|8@1+ (1,0) [0|0] "" Vector__XXX
 SG_ PCS2_DRLog_CPU3_SampleRate_itank_peak m150 : 8|8@1+ (1,0) [0|0] "" Vector__XXX
 SG_ PCS2_DRLog_CPU3_SampleRate_pwm_enabled m145 : 8|8@1+ (1,0) [0|0] "" Vector__XXX
 SG_ PCS2_DRLog_CPU3_SampleRate_v_dc m152 : 8|8@1+ (1,0) [0|0] "" Vector__XXX
 SG_ PCS2_DRLog_CPU3_SampleRate_v_ln_l1 m140 : 8|8@1+ (1,0) [0|0] "" Vector__XXX
 SG_ PCS2_DRLog_CPU3_SampleRate_v_ln_l2 m141 : 8|8@1+ (1,0) [0|0] "" Vector__XXX
 SG_ PCS2_DRLog_CPU3_SampleRate_v_ln_l3 m146 : 8|8@1+ (1,0) [0|0] "" Vector__XXX
 SG_ PCS2_DRLog_CPU3_SampleRate_v_ln_pre_relay_l2 m167 : 8|8@1+ (1,0) [0|0] "" Vector__XXX
 SG_ PCS2_DRLog_CPU3_SampleRate_v_ln_pre_relay_l3 m168 : 8|8@1+ (1,0) [0|0] "" Vector__XXX
 SG_ PCS2_DRLog_CPU3_Version m31 : 8|8@1+ (1,0) [0|0] "" Vector__XXX
 SG_ PCS2_DRLog_CPU0_Triggered m3 : 9|1@1+ (1,0) [0|0] "" Vector__XXX
 SG_ PCS2_DRLog_CPU1_Triggered m13 : 9|1@1+ (1,0) [0|0] "" Vector__XXX
 SG_ PCS2_DRLog_CPU2_Triggered m23 : 9|1@1+ (1,0) [0|0] "" Vector__XXX
 SG_ PCS2_DRLog_CPU3_Triggered m33 : 9|1@1+ (1,0) [0|0] "" Vector__XXX
 SG_ PCS2_DRLog_CPU0_ServiceState m3 : 10|4@1+ (1,0) [0|0] "" Vector__XXX
 SG_ PCS2_DRLog_CPU1_ServiceState m13 : 10|4@1+ (1,0) [0|0] "" Vector__XXX
 SG_ PCS2_DRLog_CPU2_ServiceState m23 : 10|4@1+ (1,0) [0|0] "" Vector__XXX
 SG_ PCS2_DRLog_CPU3_ServiceState m33 : 10|4@1+ (1,0) [0|0] "" Vector__XXX
 SG_ PCS2_DRLog_CPU0_Index m2 : 16|16@1+ (1,0) [0|0] "" Vector__XXX
 SG_ PCS2_DRLog_CPU0_Index_10V0_rail_vsense m170 : 16|16@1+ (1,0) [0|0] "" Vector__XXX
 SG_ PCS2_DRLog_CPU0_Index_18V0_LLC_Freq m118 : 16|16@1+ (1,0) [0|0] "" Vector__XXX
 SG_ PCS2_DRLog_CPU0_Index_18V0_Voltage m117 : 16|16@1+ (1,0) [0|0] "" Vector__XXX
 SG_ PCS2_DRLog_CPU0_Index_18V0_boost_duty m160 : 16|16@1+ (1,0) [0|0] "" Vector__XXX
 SG_ PCS2_DRLog_CPU0_Index_18V0_buck_duty m169 : 16|16@1+ (1,0) [0|0] "" Vector__XXX
 SG_ PCS2_DRLog_CPU0_Index_1V6_ref_vsense m172 : 16|16@1+ (1,0) [0|0] "" Vector__XXX
 SG_ PCS2_DRLog_CPU0_Index_4V5_rail_vsense m171 : 16|16@1+ (1,0) [0|0] "" Vector__XXX
 SG_ PCS2_DRLog_CPU0_Index_boost_buck_boost_lv_vsense m174 : 16|16@1+ (1,0) [0|0] "" Vector__XXX
 SG_ PCS2_DRLog_CPU0_Index_boost_isense_peak m173 : 16|16@1+ (1,0) [0|0] "" Vector__XXX
 SG_ PCS2_DRLog_CPU0_Index_boost_isense_valley m175 : 16|16@1+ (1,0) [0|0] "" Vector__XXX
 SG_ PCS2_DRLog_CPU0_Index_burst_mode m158 : 16|16@1+ (1,0) [0|0] "" Vector__XXX
 SG_ PCS2_DRLog_CPU0_Index_channel8 m119 : 16|16@1+ (1,0) [0|0] "" Vector__XXX
 SG_ PCS2_DRLog_CPU0_Index_dcdc_vHv m163 : 16|16@1+ (1,0) [0|0] "" Vector__XXX
 SG_ PCS2_DRLog_CPU0_Index_dcdc_vHv_bot m116 : 16|16@1+ (1,0) [0|0] "" Vector__XXX
 SG_ PCS2_DRLog_CPU0_Index_dcdc_vHv_top m102 : 16|16@1+ (1,0) [0|0] "" Vector__XXX
 SG_ PCS2_DRLog_CPU0_Index_dcdc_vLv m103 : 16|16@1+ (1,0) [0|0] "" Vector__XXX
 SG_ PCS2_DRLog_CPU0_Index_freq m112 : 16|16@1+ (1,0) [0|0] "" Vector__XXX
 SG_ PCS2_DRLog_CPU0_Index_half_bus_comp m113 : 16|16@1+ (1,0) [0|0] "" Vector__XXX
 SG_ PCS2_DRLog_CPU0_Index_half_period_pu m100 : 16|16@1+ (1,0) [0|0] "" Vector__XXX
 SG_ PCS2_DRLog_CPU0_Index_i_HV_cl_sinking m115 : 16|16@1+ (1,0) [0|0] "" Vector__XXX
 SG_ PCS2_DRLog_CPU0_Index_i_HV_cl_sourcing m114 : 16|16@1+ (1,0) [0|0] "" Vector__XXX
 SG_ PCS2_DRLog_CPU0_Index_i_HV_cmd m101 : 16|16@1+ (1,0) [0|0] "" Vector__XXX
 SG_ PCS2_DRLog_CPU0_Index_itank m104 : 16|16@1+ (1,0) [0|0] "" Vector__XXX
 SG_ PCS2_DRLog_CPU0_Index_itank_margin_fb m109 : 16|16@1+ (1,0) [0|0] "" Vector__XXX
 SG_ PCS2_DRLog_CPU0_Index_shrt_margin_fb m108 : 16|16@1+ (1,0) [0|0] "" Vector__XXX
 SG_ PCS2_DRLog_CPU0_Index_shrt_margin_ref m107 : 16|16@1+ (1,0) [0|0] "" Vector__XXX
 SG_ PCS2_DRLog_CPU0_Index_theta_HV m110 : 16|16@1+ (1,0) [0|0] "" Vector__XXX
 SG_ PCS2_DRLog_CPU0_Index_theta_LV m111 : 16|16@1+ (1,0) [0|0] "" Vector__XXX
 SG_ PCS2_DRLog_CPU0_Index_zcd_flt_cnt m105 : 16|16@1+ (1,0) [0|0] "" Vector__XXX
 SG_ PCS2_DRLog_CPU0_Index_zcd_fltd m106 : 16|16@1+ (1,0) [0|0] "" Vector__XXX
 SG_ PCS2_DRLog_CPU0_Index_zcd_rising_pu m165 : 16|16@1+ (1,0) [0|0] "" Vector__XXX
 SG_ PCS2_DRLog_CPU0_InstanceIndex m3 : 16|4@1+ (1,0) [0|0] "" Vector__XXX
 SG_ PCS2_DRLog_CPU0_SampleFrequency m1 : 16|32@1+ (1,0) [0|0] "" Vector__XXX
 SG_ PCS2_DRLog_CPU1_Index m12 : 16|16@1+ (1,0) [0|0] "" Vector__XXX
 SG_ PCS2_DRLog_CPU1_Index_18V0_LLC_Freq m138 : 16|16@1+ (1,0) [0|0] "" Vector__XXX
 SG_ PCS2_DRLog_CPU1_Index_18V0_Voltage m137 : 16|16@1+ (1,0) [0|0] "" Vector__XXX
 SG_ PCS2_DRLog_CPU1_Index_18V0_boost_duty m161 : 16|16@1+ (1,0) [0|0] "" Vector__XXX
 SG_ PCS2_DRLog_CPU1_Index_burst_mode m159 : 16|16@1+ (1,0) [0|0] "" Vector__XXX
 SG_ PCS2_DRLog_CPU1_Index_dcdc_iHv m139 : 16|16@1+ (1,0) [0|0] "" Vector__XXX
 SG_ PCS2_DRLog_CPU1_Index_dcdc_vHv m164 : 16|16@1+ (1,0) [0|0] "" Vector__XXX
 SG_ PCS2_DRLog_CPU1_Index_dcdc_vHv_bot m123 : 16|16@1+ (1,0) [0|0] "" Vector__XXX
 SG_ PCS2_DRLog_CPU1_Index_dcdc_vHv_top m126 : 16|16@1+ (1,0) [0|0] "" Vector__XXX
 SG_ PCS2_DRLog_CPU1_Index_dcdc_vLv m127 : 16|16@1+ (1,0) [0|0] "" Vector__XXX
 SG_ PCS2_DRLog_CPU1_Index_freq m136 : 16|16@1+ (1,0) [0|0] "" Vector__XXX
 SG_ PCS2_DRLog_CPU1_Index_half_bus_comp m120 : 16|16@1+ (1,0) [0|0] "" Vector__XXX
 SG_ PCS2_DRLog_CPU1_Index_half_period_pu m124 : 16|16@1+ (1,0) [0|0] "" Vector__XXX
 SG_ PCS2_DRLog_CPU1_Index_i_HV_cl_sinking m122 : 16|16@1+ (1,0) [0|0] "" Vector__XXX
 SG_ PCS2_DRLog_CPU1_Index_i_HV_cl_sourcing m121 : 16|16@1+ (1,0) [0|0] "" Vector__XXX
 SG_ PCS2_DRLog_CPU1_Index_i_HV_cmd m125 : 16|16@1+ (1,0) [0|0] "" Vector__XXX
 SG_ PCS2_DRLog_CPU1_Index_itank m128 : 16|16@1+ (1,0) [0|0] "" Vector__XXX
 SG_ PCS2_DRLog_CPU1_Index_itank_margin_fb m133 : 16|16@1+ (1,0) [0|0] "" Vector__XXX
 SG_ PCS2_DRLog_CPU1_Index_shrt_margin_fb m132 : 16|16@1+ (1,0) [0|0] "" Vector__XXX
 SG_ PCS2_DRLog_CPU1_Index_shrt_margin_ref m131 : 16|16@1+ (1,0) [0|0] "" Vector__XXX
 SG_ PCS2_DRLog_CPU1_Index_theta_HV m134 : 16|16@1+ (1,0) [0|0] "" Vector__XXX
 SG_ PCS2_DRLog_CPU1_Index_theta_LV m135 : 16|16@1+ (1,0) [0|0] "" Vector__XXX
 SG_ PCS2_DRLog_CPU1_Index_zcd_flt_cnt m129 : 16|16@1+ (1,0) [0|0] "" Vector__XXX
 SG_ PCS2_DRLog_CPU1_Index_zcd_fltd m130 : 16|16@1+ (1,0) [0|0] "" Vector__XXX
 SG_ PCS2_DRLog_CPU1_Index_zcd_rising_pu m166 : 16|16@1+ (1,0) [0|0] "" Vector__XXX
 SG_ PCS2_DRLog_CPU1_InstanceIndex m13 : 16|4@1+ (1,0) [0|0] "" Vector__XXX
 SG_ PCS2_DRLog_CPU1_SampleFrequency m11 : 16|32@1+ (1,0) [0|0] "" Vector__XXX
 SG_ PCS2_DRLog_CPU2_Index m22 : 16|16@1+ (1,0) [0|0] "" Vector__XXX
 SG_ PCS2_DRLog_CPU2_InstanceIndex m23 : 16|4@1+ (1,0) [0|0] "" Vector__XXX
 SG_ PCS2_DRLog_CPU2_SampleFrequency m21 : 16|32@1+ (1,0) [0|0] "" Vector__XXX
 SG_ PCS2_DRLog_CPU3_Index m32 : 16|16@1+ (1,0) [0|0] "" Vector__XXX
 SG_ PCS2_DRLog_CPU3_Index_18V0_LLC_Freq m157 : 16|16@1+ (1,0) [0|0] "" Vector__XXX
 SG_ PCS2_DRLog_CPU3_Index_18V0_Voltage m156 : 16|16@1+ (1,0) [0|0] "" Vector__XXX
 SG_ PCS2_DRLog_CPU3_Index_18V0_boost_duty m162 : 16|16@1+ (1,0) [0|0] "" Vector__XXX
 SG_ PCS2_DRLog_CPU3_Index_Itank_margin m144 : 16|16@1+ (1,0) [0|0] "" Vector__XXX
 SG_ PCS2_DRLog_CPU3_Index_freq m151 : 16|16@1+ (1,0) [0|0] "" Vector__XXX
 SG_ PCS2_DRLog_CPU3_Index_hvdc_current m155 : 16|16@1+ (1,0) [0|0] "" Vector__XXX
 SG_ PCS2_DRLog_CPU3_Index_i_ac_cmd_l1 m148 : 16|16@1+ (1,0) [0|0] "" Vector__XXX
 SG_ PCS2_DRLog_CPU3_Index_i_ac_cmd_l2 m149 : 16|16@1+ (1,0) [0|0] "" Vector__XXX
 SG_ PCS2_DRLog_CPU3_Index_i_ac_cmd_l3 m153 : 16|16@1+ (1,0) [0|0] "" Vector__XXX
 SG_ PCS2_DRLog_CPU3_Index_i_ac_ref_l1 m147 : 16|16@1+ (1,0) [0|0] "" Vector__XXX
 SG_ PCS2_DRLog_CPU3_Index_i_ln_l1 m142 : 16|16@1+ (1,0) [0|0] "" Vector__XXX
 SG_ PCS2_DRLog_CPU3_Index_i_ln_l2 m143 : 16|16@1+ (1,0) [0|0] "" Vector__XXX
 SG_ PCS2_DRLog_CPU3_Index_i_ln_l3 m154 : 16|16@1+ (1,0) [0|0] "" Vector__XXX
 SG_ PCS2_DRLog_CPU3_Index_itank_peak m150 : 16|16@1+ (1,0) [0|0] "" Vector__XXX
 SG_ PCS2_DRLog_CPU3_Index_pwm_enabled m145 : 16|16@1+ (1,0) [0|0] "" Vector__XXX
 SG_ PCS2_DRLog_CPU3_Index_v_dc m152 : 16|16@1+ (1,0) [0|0] "" Vector__XXX
 SG_ PCS2_DRLog_CPU3_Index_v_ln_l1 m140 : 16|16@1+ (1,0) [0|0] "" Vector__XXX
 SG_ PCS2_DRLog_CPU3_Index_v_ln_l2 m141 : 16|16@1+ (1,0) [0|0] "" Vector__XXX
 SG_ PCS2_DRLog_CPU3_Index_v_ln_l3 m146 : 16|16@1+ (1,0) [0|0] "" Vector__XXX
 SG_ PCS2_DRLog_CPU3_Index_v_ln_pre_relay_l2 m167 : 16|16@1+ (1,0) [0|0] "" Vector__XXX
 SG_ PCS2_DRLog_CPU3_Index_v_ln_pre_relay_l3 m168 : 16|16@1+ (1,0) [0|0] "" Vector__XXX
 SG_ PCS2_DRLog_CPU3_InstanceIndex m33 : 16|4@1+ (1,0) [0|0] "" Vector__XXX
 SG_ PCS2_DRLog_CPU3_SampleFrequency m31 : 16|32@1+ (1,0) [0|0] "" Vector__XXX
 SG_ PCS2_DRLog_CPU0_InstanceBufferPos m3 : 24|16@1+ (1,0) [0|0] "" Vector__XXX
 SG_ PCS2_DRLog_CPU1_InstanceBufferPos m13 : 24|16@1+ (1,0) [0|0] "" Vector__XXX
 SG_ PCS2_DRLog_CPU2_InstanceBufferPos m23 : 24|16@1+ (1,0) [0|0] "" Vector__XXX
 SG_ PCS2_DRLog_CPU3_InstanceBufferPos m33 : 24|16@1+ (1,0) [0|0] "" Vector__XXX
 SG_ PCS2_DRLog_CPU0_Sample m2 : 32|32@1- (0.001,0) [0|0] "" Vector__XXX
 SG_ PCS2_DRLog_CPU0_Sample_10V0_rail_vsense m170 : 32|32@1- (0.001,0) [0|0] "" Vector__XXX
 SG_ PCS2_DRLog_CPU0_Sample_18V0_LLC_Freq m118 : 32|32@1- (0.001,0) [0|0] "" Vector__XXX
 SG_ PCS2_DRLog_CPU0_Sample_18V0_Voltage m117 : 32|32@1- (0.001,0) [0|0] "" Vector__XXX
 SG_ PCS2_DRLog_CPU0_Sample_18V0_boost_duty m160 : 32|32@1- (0.001,0) [0|0] "" Vector__XXX
 SG_ PCS2_DRLog_CPU0_Sample_18V0_buck_duty m169 : 32|32@1- (0.001,0) [0|0] "" Vector__XXX
 SG_ PCS2_DRLog_CPU0_Sample_1V6_ref_vsense m172 : 32|32@1- (0.001,0) [0|0] "" Vector__XXX
 SG_ PCS2_DRLog_CPU0_Sample_4V5_rail_vsense m171 : 32|32@1- (0.001,0) [0|0] "" Vector__XXX
 SG_ PCS2_DRLog_CPU0_Sample_boost_buck_boost_lv_vsense m174 : 32|32@1- (0.001,0) [0|0] "" Vector__XXX
 SG_ PCS2_DRLog_CPU0_Sample_boost_isense_peak m173 : 32|32@1- (0.001,0) [0|0] "" Vector__XXX
 SG_ PCS2_DRLog_CPU0_Sample_boost_isense_valley m175 : 32|32@1- (0.001,0) [0|0] "" Vector__XXX
 SG_ PCS2_DRLog_CPU0_Sample_burst_mode m158 : 32|32@1- (0.001,0) [0|0] "" Vector__XXX
 SG_ PCS2_DRLog_CPU0_Sample_channel8 m119 : 32|32@1- (0.001,0) [0|0] "" Vector__XXX
 SG_ PCS2_DRLog_CPU0_Sample_dcdc_vHv m163 : 32|32@1- (0.001,0) [0|0] "" Vector__XXX
 SG_ PCS2_DRLog_CPU0_Sample_dcdc_vHv_bot m116 : 32|32@1- (0.001,0) [0|0] "" Vector__XXX
 SG_ PCS2_DRLog_CPU0_Sample_dcdc_vHv_top m102 : 32|32@1- (0.001,0) [0|0] "" Vector__XXX
 SG_ PCS2_DRLog_CPU0_Sample_dcdc_vLv m103 : 32|32@1- (0.001,0) [0|0] "" Vector__XXX
 SG_ PCS2_DRLog_CPU0_Sample_freq m112 : 32|32@1- (0.001,0) [0|0] "" Vector__XXX
 SG_ PCS2_DRLog_CPU0_Sample_half_bus_comp m113 : 32|32@1- (0.001,0) [0|0] "" Vector__XXX
 SG_ PCS2_DRLog_CPU0_Sample_half_period_pu m100 : 32|32@1- (0.001,0) [0|0] "" Vector__XXX
 SG_ PCS2_DRLog_CPU0_Sample_i_HV_cl_sinking m115 : 32|32@1- (0.001,0) [0|0] "" Vector__XXX
 SG_ PCS2_DRLog_CPU0_Sample_i_HV_cl_sourcing m114 : 32|32@1- (0.001,0) [0|0] "" Vector__XXX
 SG_ PCS2_DRLog_CPU0_Sample_i_HV_cmd m101 : 32|32@1- (0.001,0) [0|0] "" Vector__XXX
 SG_ PCS2_DRLog_CPU0_Sample_itank m104 : 32|32@1- (0.001,0) [0|0] "" Vector__XXX
 SG_ PCS2_DRLog_CPU0_Sample_itank_margin_fb m109 : 32|32@1- (0.001,0) [0|0] "" Vector__XXX
 SG_ PCS2_DRLog_CPU0_Sample_shrt_margin_fb m108 : 32|32@1- (0.001,0) [0|0] "" Vector__XXX
 SG_ PCS2_DRLog_CPU0_Sample_shrt_margin_ref m107 : 32|32@1- (0.001,0) [0|0] "" Vector__XXX
 SG_ PCS2_DRLog_CPU0_Sample_theta_HV m110 : 32|32@1- (0.001,0) [0|0] "" Vector__XXX
 SG_ PCS2_DRLog_CPU0_Sample_theta_LV m111 : 32|32@1- (0.001,0) [0|0] "" Vector__XXX
 SG_ PCS2_DRLog_CPU0_Sample_zcd_flt_cnt m105 : 32|32@1- (0.001,0) [0|0] "" Vector__XXX
 SG_ PCS2_DRLog_CPU0_Sample_zcd_fltd m106 : 32|32@1- (0.001,0) [0|0] "" Vector__XXX
 SG_ PCS2_DRLog_CPU0_Sample_zcd_rising_pu m165 : 32|32@1- (0.001,0) [0|0] "" Vector__XXX
 SG_ PCS2_DRLog_CPU1_Sample m12 : 32|32@1- (0.001,0) [0|0] "" Vector__XXX
 SG_ PCS2_DRLog_CPU1_Sample_18V0_LLC_Freq m138 : 32|32@1- (0.001,0) [0|0] "" Vector__XXX
 SG_ PCS2_DRLog_CPU1_Sample_18V0_Voltage m137 : 32|32@1- (0.001,0) [0|0] "" Vector__XXX
 SG_ PCS2_DRLog_CPU1_Sample_18V0_boost_duty m161 : 32|32@1- (0.001,0) [0|0] "" Vector__XXX
 SG_ PCS2_DRLog_CPU1_Sample_burst_mode m159 : 32|32@1- (0.001,0) [0|0] "" Vector__XXX
 SG_ PCS2_DRLog_CPU1_Sample_dcdc_iHv m139 : 32|32@1- (0.001,0) [0|0] "" Vector__XXX
 SG_ PCS2_DRLog_CPU1_Sample_dcdc_vHv m164 : 32|32@1- (0.001,0) [0|0] "" Vector__XXX
 SG_ PCS2_DRLog_CPU1_Sample_dcdc_vHv_bot m123 : 32|32@1- (0.001,0) [0|0] "" Vector__XXX
 SG_ PCS2_DRLog_CPU1_Sample_dcdc_vHv_top m126 : 32|32@1- (0.001,0) [0|0] "" Vector__XXX
 SG_ PCS2_DRLog_CPU1_Sample_dcdc_vLv m127 : 32|32@1- (0.001,0) [0|0] "" Vector__XXX
 SG_ PCS2_DRLog_CPU1_Sample_freq m136 : 32|32@1- (0.001,0) [0|0] "" Vector__XXX
 SG_ PCS2_DRLog_CPU1_Sample_half_bus_comp m120 : 32|32@1- (0.001,0) [0|0] "" Vector__XXX
 SG_ PCS2_DRLog_CPU1_Sample_half_period_pu m124 : 32|32@1- (0.001,0) [0|0] "" Vector__XXX
 SG_ PCS2_DRLog_CPU1_Sample_i_HV_cl_sinking m122 : 32|32@1- (0.001,0) [0|0] "" Vector__XXX
 SG_ PCS2_DRLog_CPU1_Sample_i_HV_cl_sourcing m121 : 32|32@1- (0.001,0) [0|0] "" Vector__XXX
 SG_ PCS2_DRLog_CPU1_Sample_i_HV_cmd m125 : 32|32@1- (0.001,0) [0|0] "" Vector__XXX
 SG_ PCS2_DRLog_CPU1_Sample_itank m128 : 32|32@1- (0.001,0) [0|0] "" Vector__XXX
 SG_ PCS2_DRLog_CPU1_Sample_itank_margin_fb m133 : 32|32@1- (0.001,0) [0|0] "" Vector__XXX
 SG_ PCS2_DRLog_CPU1_Sample_shrt_margin_fb m132 : 32|32@1- (0.001,0) [0|0] "" Vector__XXX
 SG_ PCS2_DRLog_CPU1_Sample_shrt_margin_ref m131 : 32|32@1- (0.001,0) [0|0] "" Vector__XXX
 SG_ PCS2_DRLog_CPU1_Sample_theta_HV m134 : 32|32@1- (0.001,0) [0|0] "" Vector__XXX
 SG_ PCS2_DRLog_CPU1_Sample_theta_LV m135 : 32|32@1- (0.001,0) [0|0] "" Vector__XXX
 SG_ PCS2_DRLog_CPU1_Sample_zcd_flt_cnt m129 : 32|32@1- (0.001,0) [0|0] "" Vector__XXX
 SG_ PCS2_DRLog_CPU1_Sample_zcd_fltd m130 : 32|32@1- (0.001,0) [0|0] "" Vector__XXX
 SG_ PCS2_DRLog_CPU1_Sample_zcd_rising_pu m166 : 32|32@1- (0.001,0) [0|0] "" Vector__XXX
 SG_ PCS2_DRLog_CPU2_Sample m22 : 32|32@1- (0.001,0) [0|0] "" Vector__XXX
 SG_ PCS2_DRLog_CPU3_Sample m32 : 32|32@1- (0.001,0) [0|0] "" Vector__XXX
 SG_ PCS2_DRLog_CPU3_Sample_18V0_LLC_Freq m157 : 32|32@1- (0.001,0) [0|0] "" Vector__XXX
 SG_ PCS2_DRLog_CPU3_Sample_18V0_Voltage m156 : 32|32@1- (0.001,0) [0|0] "" Vector__XXX
 SG_ PCS2_DRLog_CPU3_Sample_18V0_boost_duty m162 : 32|32@1- (0.001,0) [0|0] "" Vector__XXX
 SG_ PCS2_DRLog_CPU3_Sample_Itank_margin m144 : 32|32@1- (0.001,0) [0|0] "" Vector__XXX
 SG_ PCS2_DRLog_CPU3_Sample_freq m151 : 32|32@1- (0.001,0) [0|0] "" Vector__XXX
 SG_ PCS2_DRLog_CPU3_Sample_hvdc_current m155 : 32|32@1- (0.001,0) [0|0] "" Vector__XXX
 SG_ PCS2_DRLog_CPU3_Sample_i_ac_cmd_l1 m148 : 32|32@1- (0.001,0) [0|0] "" Vector__XXX
 SG_ PCS2_DRLog_CPU3_Sample_i_ac_cmd_l2 m149 : 32|32@1- (0.001,0) [0|0] "" Vector__XXX
 SG_ PCS2_DRLog_CPU3_Sample_i_ac_cmd_l3 m153 : 32|32@1- (0.001,0) [0|0] "" Vector__XXX
 SG_ PCS2_DRLog_CPU3_Sample_i_ac_ref_l1 m147 : 32|32@1- (0.001,0) [0|0] "" Vector__XXX
 SG_ PCS2_DRLog_CPU3_Sample_i_ln_l1 m142 : 32|32@1- (0.001,0) [0|0] "" Vector__XXX
 SG_ PCS2_DRLog_CPU3_Sample_i_ln_l2 m143 : 32|32@1- (0.001,0) [0|0] "" Vector__XXX
 SG_ PCS2_DRLog_CPU3_Sample_i_ln_l3 m154 : 32|32@1- (0.001,0) [0|0] "" Vector__XXX
 SG_ PCS2_DRLog_CPU3_Sample_itank_peak m150 : 32|32@1- (0.001,0) [0|0] "" Vector__XXX
 SG_ PCS2_DRLog_CPU3_Sample_pwm_enabled m145 : 32|32@1- (0.001,0) [0|0] "" Vector__XXX
 SG_ PCS2_DRLog_CPU3_Sample_v_dc m152 : 32|32@1- (0.001,0) [0|0] "" Vector__XXX
 SG_ PCS2_DRLog_CPU3_Sample_v_ln_l1 m140 : 32|32@1- (0.001,0) [0|0] "" Vector__XXX
 SG_ PCS2_DRLog_CPU3_Sample_v_ln_l2 m141 : 32|32@1- (0.001,0) [0|0] "" Vector__XXX
 SG_ PCS2_DRLog_CPU3_Sample_v_ln_l3 m146 : 32|32@1- (0.001,0) [0|0] "" Vector__XXX
 SG_ PCS2_DRLog_CPU3_Sample_v_ln_pre_relay_l2 m167 : 32|32@1- (0.001,0) [0|0] "" Vector__XXX
 SG_ PCS2_DRLog_CPU3_Sample_v_ln_pre_relay_l3 m168 : 32|32@1- (0.001,0) [0|0] "" Vector__XXX
 SG_ PCS2_DRLog_CPU0_InstanceTriggerAcq m3 : 40|16@1+ (1,0) [0|0] "" Vector__XXX
 SG_ PCS2_DRLog_CPU1_InstanceTriggerAcq m13 : 40|16@1+ (1,0) [0|0] "" Vector__XXX
 SG_ PCS2_DRLog_CPU2_InstanceTriggerAcq m23 : 40|16@1+ (1,0) [0|0] "" Vector__XXX
 SG_ PCS2_DRLog_CPU3_InstanceTriggerAcq m33 : 40|16@1+ (1,0) [0|0] "" Vector__XXX
 SG_ PCS2_DRLog_CPU0_PlotId m1 : 48|8@1+ (1,0) [0|0] "" Vector__XXX
 SG_ PCS2_DRLog_CPU1_PlotId m11 : 48|8@1+ (1,0) [0|0] "" Vector__XXX
 SG_ PCS2_DRLog_CPU2_PlotId m21 : 48|8@1+ (1,0) [0|0] "" Vector__XXX
 SG_ PCS2_DRLog_CPU3_PlotId m31 : 48|8@1+ (1,0) [0|0] "" Vector__XXX

VAL_ 1828 VCFRONT_loadShedStsBatteryPump_duty 127 "SNA" ;
VAL_ 1828 VCFRONT_loadShedStsCondenserFan_duty 127 "SNA" ;
VAL_ 1828 VCFRONT_loadShedStsPTPump_duty 127 "SNA" ;
VAL_ 1829 VCBATT2_loadShedStsBatteryPump_duty 127 "SNA" ;
VAL_ 1829 VCBATT2_loadShedStsCondenserFan_duty 127 "SNA" ;
VAL_ 1829 VCBATT2_loadShedStsPTPump_duty 127 "SNA" ;
VAL_ 1830 VCLEFT_loadShedStsHVACBlower_duty 127 "SNA" ;
VAL_ 1847 VCFRONT_LVBMS_InfoIndex 0 "PCBAID_ASSYID" 1 "APP_USAGEID_CRC" 2 "GITHASH" 3 "BUILDTYPE" 4 "SERIAL_NUMBER" 5 "INVALID" ;
VAL_ 1847 VCFRONT_LVBMS_FWBuildType 0 "UNKNOWN_BUILD" 1 "PLATFORM_BUILD" 2 "LOCAL_BUILD" 3 "TRACEABLE_CI_BUILD" 4 "MFG_BUILD" ;
VAL_ 1854 VEH_GB_Chg_Stop_Rsn_SOC 127 "SNA" ;
VAL_ 1854 VEH_GB_Final_SOC 127 "SNA" ;
VAL_ 1854 VEH_GB_Protocol_Ver_log 0 "NO_CHARGER_PRESENT" 1 "DC_CHARGER_PRESENT" 2 "AC_CHARGER_PRESENT" ;
VAL_ 1854 VEH_GB_Status 0 "IDLE" 1 "RX" ;
VAL_ 1854 VEH_currentDemand_value_log 0 "NO_CHARGER_PRESENT" 1 "DC_CHARGER_PRESENT" 2 "AC_CHARGER_PRESENT" ;
VAL_ 1854 VEH_teslaGbProtocolVersion_log 0 "NO_CHARGER_PRESENT" 1 "DC_CHARGER_PRESENT" 2 "AC_CHARGER_PRESENT" ;
VAL_ 1854 VEH_GB_BAT_SOC 127 "SNA" ;
VAL_ 1854 VEH_chargeCurrent_value_log 0 "NO_CHARGER_PRESENT" 1 "DC_CHARGER_PRESENT" 2 "AC_CHARGER_PRESENT" ;
VAL_ 1854 VEH_GB_SOC 127 "SNA" ;
VAL_ 1854 VEH_currentDemand_exp_log 0 "NO_CHARGER_PRESENT" 1 "DC_CHARGER_PRESENT" 2 "AC_CHARGER_PRESENT" ;
VAL_ 1854 VEH_chargeCurrent_exp_log 0 "NO_CHARGER_PRESENT" 1 "DC_CHARGER_PRESENT" 2 "AC_CHARGER_PRESENT" ;
VAL_ 1858 VCBATT1_lvbmsStatusHighIndex 0 "PACK_VITALS_1" 1 "CELL_VITALS_1" 2 "CELL_VITALS_2" 3 "TARGETS" 4 "STATE_AND_COMMANDS" 5 "PCS_INTERFACE" 6 "INVALID" ;
VAL_ 1858 VCBATT1_LVBMS_packCurrent 4294934528 "SNA" ;
VAL_ 1858 VCBATT1_LVBMS_voltageTarget 32767 "SNA" ;
VAL_ 1858 VCBATT1_LVBMS_ECPAState 0 "OPEN" 1 "CLOSED" 2 "INVALID" 3 "SNA" ;
VAL_ 1858 VCBATT1_LVBMS_sumCellVoltage 65534 "INVALID" 65535 "SNA" ;
VAL_ 1858 VCBATT1_LVBMS_MOSState 0 "OPEN" 1 "CLOSED" 2 "INVALID" 3 "SNA" ;
VAL_ 1858 VCBATT1_LVBMS_VehicleState 0 "DRIVE" 1 "ACCESSORY" 2 "CONDITIONING" 3 "OFF" ;
VAL_ 1858 VCBATT1_LVBMS_LINWakeDisabled 0 "ENABLED" 1 "DISABLED" ;
VAL_ 1858 VCBATT1_LVBMS_chargeType 0 "UNDEFINED" 1 "CONSTANT_CURRENT" 2 "CONSTANT_VOLTAGE" 3 "COMPLETE" 4 "SNA" ;
VAL_ 1858 VCBATT1_LVBMS_currentTarget 32767 "SNA" ;
VAL_ 1858 VCBATT1_LVBMS_packVoltage 65535 "SNA" ;
VAL_ 1858 VCBATT1_LVBMS_maxAllowedChargeCurrent 8191 "SNA" ;
VAL_ 1858 VCBATT1_LVBMS_packTemperature 511 "SNA" ;
VAL_ 1858 VCBATT1_LVBMS_MOSTemperature 4095 "SNA" ;
VAL_ 1858 VCBATT1_LVBMS_maxAllowedDischargeCurrent 8191 "SNA" ;
VAL_ 1859 VCRIGHT_systemRecallStatus 0 "SNA" 1 "IN_PROGRESS" 2 "COMPLETE" 3 "INTERRUPTED" ;
VAL_ 1859 VCRIGHT_seatRecallStatus 0 "SNA" 1 "IN_PROGRESS" 2 "COMPLETE" 3 "INTERRUPTED" ;
VAL_ 1859 VCRIGHT_mirrorRecallStatus 0 "SNA" 1 "IN_PROGRESS" 2 "COMPLETE" 3 "INTERRUPTED" ;
VAL_ 1860 VCLEFT_systemRecallStatus 0 "SNA" 1 "IN_PROGRESS" 2 "COMPLETE" 3 "INTERRUPTED" ;
VAL_ 1860 VCLEFT_seatRecallStatus 0 "SNA" 1 "IN_PROGRESS" 2 "COMPLETE" 3 "INTERRUPTED" ;
VAL_ 1860 VCLEFT_columnRecallStatus 0 "SNA" 1 "IN_PROGRESS" 2 "COMPLETE" 3 "INTERRUPTED" ;
VAL_ 1860 VCLEFT_mirrorRecallStatus 0 "SNA" 1 "IN_PROGRESS" 2 "COMPLETE" 3 "INTERRUPTED" ;
VAL_ 1874 BMS_100HzDebug_Id 0 "MUX0" 1 "MUX1" 2 "MUX2" 3 "MUX3" 4 "MUX4" 5 "MUX5" 6 "MUX6" 7 "MUX7" 8 "MUX8" 9 "MUX9" 10 "MUX10" 11 "MUX11" 12 "MUX12" 13 "MUX13" 14 "END" ;
VAL_ 1879 DIF_debugSelector 64 "Mux64" 128 "Mux128" 66 "Mux66" 67 "Mux67" 131 "Mux131" 68 "Mux68" 132 "Mux132" 69 "Mux69" 70 "Mux70" 72 "Mux72" 32 "Mux32" 33 "Mux33" 34 "Mux34" 35 "Mux35" 36 "Mux36" 37 "Mux37" 38 "Mux38" 39 "Mux39" 40 "Mux40" 41 "Mux41" 42 "Mux42" 43 "Mux43" 46 "Mux46" 47 "Mux47" 48 "Mux48" 49 "Mux49" 50 "Mux50" 52 "Mux52" 63 "Mux63" ;
VAL_ 1885 CP_loggingFastSelect 0 "0" 1 "1" 2 "2" 3 "3" ;
VAL_ 1885 CP_UHF_controlState 0 "INIT" 1 "CONFIG" 2 "IDLE" 3 "CALIBRATE" 4 "PREPARE_RX" 5 "RX" 6 "CHECK_RX" 7 "READ_RXFIFO" 8 "HANDLE_FOUND" 9 "SLEEP" 10 "FAULT" ;
VAL_ 1885 CP_doorOpenRequest 0 "NONE" 1 "UI" 2 "SEC" 3 "UHF" 4 "PUSH_TO_OPEN" 5 "CLOSING_FAILED" 6 "VCFRONT" 7 "CABLE_RECONNECTED" 8 "NUM" ;
VAL_ 1885 CP_doorOpenEndOfDriveReason 0 "NONE" 1 "LOW_SPEED" 2 "STOPPED_MOVING_TIMEOUT" 3 "REACHED_STOP" 4 "MAX_TARGET_V" 5 "ABSOLUTE_TIMEOUT" 6 "CLOSE_REQ_OVERRIDE" ;
VAL_ 1885 CP_doorCloseEndOfDriveReason 0 "NONE" 1 "LOW_SPEED" 2 "STOPPED_MOVING_TIMEOUT" 3 "REACHED_STOP" 4 "MAX_TARGET_V" 5 "ABSOLUTE_TIMEOUT" 6 "CLOSE_REQ_OVERRIDE" ;
VAL_ 1885 CP_doorCloseRequest 0 "NONE" 1 "CABLE_UNPLUGGED" 2 "DOOR_OPEN_TIMEOUT" 3 "UI" 4 "SEC" 5 "PUSH_TO_CLOSE" 6 "VEH_LOCK" 7 "CAR_WASH" 8 "FAULT_LINE" 9 "ENTER_DRIVE" 10 "OPENED_IN_DRIVE_STATE" 11 "INITIAL_CINCH" 12 "SENSOR_MISMATCH" 13 "SENSOR_COMMS_RECOVERED" 14 "OPEN_ON_WAKE" 15 "VCFRONT" 16 "NUM" ;
VAL_ 1885 CP_chargeCablePresent 0 "NOT_PRESENT" 1 "PRESENT" ;
VAL_ 1886 CA_VEH_BAT_SOC 127 "SNA" ;
VAL_ 1889 PMF_debugSelector 64 "Mux64" 128 "Mux128" 66 "Mux66" 67 "Mux67" 131 "Mux131" 68 "Mux68" 132 "Mux132" 69 "Mux69" 70 "Mux70" 72 "Mux72" 32 "Mux32" 33 "Mux33" 34 "Mux34" 35 "Mux35" 36 "Mux36" 37 "Mux37" 38 "Mux38" 39 "Mux39" 40 "Mux40" 41 "Mux41" 42 "Mux42" 43 "Mux43" 46 "Mux46" 47 "Mux47" 48 "Mux48" 49 "Mux49" 50 "Mux50" 52 "Mux52" 63 "Mux63" ;
VAL_ 1926 DBG_vehicleSpeed 8191 "SNA" ;
VAL_ 1928 EPBL_pid_duty 127 "SNA" ;
VAL_ 1928 EPBL_esmCaliperRequest 0 "INVALID" 1 "NONE" 2 "APPLY" 3 "RELEASE" 4 "ENDSTOP" ;
VAL_ 1929 EPBL_rcmLVState 0 "OFF" 1 "ON" 2 "GOING_DOWN" 3 "FAULT" ;
VAL_ 1929 EPBL_lumbarLVState 0 "OFF" 1 "ON" 2 "GOING_DOWN" 3 "FAULT" ;
VAL_ 1929 EPBL_vehiclePowerStateDBG 0 "INIT" 1 "LOW_POWER_AWAKE" 2 "CONDITIONING" 3 "ACCESSORY" 4 "ACCESSORY_PLUS" 5 "DRIVE" 6 "OTA" 7 "WAIT_FOR_HIGH_POWER" 8 "TURN_ON_LV" 9 "SYSTEM_CHECKS" 10 "LV_ON" 11 "JUMP_START" 12 "LV_SHUTDOWN" 13 "GO_QUIET" 14 "SLEEP_SHUTDOWN" 15 "LOW_POWER_STANDBY" 16 "RESET" ;
VAL_ 1943 EPBR_rcmLVState 0 "OFF" 1 "ON" 2 "GOING_DOWN" 3 "FAULT" ;
VAL_ 1943 EPBR_tunerLVState 0 "OFF" 1 "ON" 2 "GOING_DOWN" 3 "FAULT" ;
VAL_ 1943 EPBR_parkLVState 0 "OFF" 1 "ON" 2 "GOING_DOWN" 3 "FAULT" ;
VAL_ 1943 EPBR_premAudioLVState 0 "OFF" 1 "ON" 2 "GOING_DOWN" 3 "FAULT" ;
VAL_ 1943 EPBR_ptcLVState 0 "OFF" 1 "ON" 2 "GOING_DOWN" 3 "FAULT" ;
VAL_ 1943 EPBR_vehiclePowerStateDBG 0 "INIT" 1 "LOW_POWER_AWAKE" 2 "CONDITIONING" 3 "ACCESSORY" 4 "ACCESSORY_PLUS" 5 "DRIVE" 6 "OTA" 7 "WAIT_FOR_HIGH_POWER" 8 "TURN_ON_LV" 9 "SYSTEM_CHECKS" 10 "LV_ON" 11 "JUMP_START" 12 "LV_SHUTDOWN" 13 "GO_QUIET" 14 "SLEEP_SHUTDOWN" 15 "LOW_POWER_STANDBY" 16 "RESET" ;
VAL_ 1944 EPBL_remoteADCIndex 0 "0" 1 "1" 2 "2" 3 "3" 4 "4" 5 "5" ;
VAL_ 1960 EPBR_pid_duty 127 "SNA" ;
VAL_ 1960 EPBR_esmCaliperRequest 0 "INVALID" 1 "NONE" 2 "APPLY" 3 "RELEASE" 4 "ENDSTOP" ;
VAL_ 1962 HVP_debugMessageMultiplexer 0 "Mux0" 1 "Mux1" 2 "Mux2" 3 "Mux3" 4 "Mux4" 5 "Mux5" 6 "Mux6" 7 "Mux7" 8 "Mux8" 9 "Mux9" 10 "Mux10" 11 "Mux11" 12 "Mux12" ;
VAL_ 1962 HVP_ecuLogUploadRequest 0 "NONE" 1 "1" 2 "2" 3 "3" ;
VAL_ 1962 HVP_packVoltage 65535 "SNA" ;
VAL_ 1976 EPBR_remoteADCIndex 0 "0" 1 "1" 2 "2" 3 "3" 4 "4" 5 "5" ;
VAL_ 1992 EPBL_infoIndex 0 "DEPRECATED_0" 1 "DEPRECATED_1" 2 "DEPRECATED_2" 3 "DEPRECATED_3" 4 "DEPRECATED_4" 5 "DEPRECATED_5" 6 "DEPRECATED_6" 7 "DEPRECATED_7" 8 "DEPRECATED_8" 9 "DEPRECATED_9" 10 "BUILD_HWID_COMPONENTID" 11 "PCBAID_ASSYID_USAGEID" 13 "APP_CRC" 14 "BOOTLOADER_SVN" 15 "BOOTLOADER_CRC" 16 "SUBCOMPONENT1" 17 "APP_GITHASH" 18 "BOOTLOADER_GITHASH" 19 "VERSION_DEPRECATED" 20 "UDS_PROTOCOL_BOOTCRC" 23 "SUBCOMPONENT2" 24 "SUBCOMPONENT3" 31 "SUBCOMPONENT4" 32 "SUBCOMPONENT5" 33 "SUBCOMPONENT6" 34 "SUBCOMPONENT7" 35 "SUBCOMPONENT8" 36 "SUBCOMPONENT9" 37 "SUBCOMPONENT10" 38 "SUBCOMPONENT11" 39 "SUBCOMPONENT12" 40 "SUBCOMPONENT13" 41 "SUBCOMPONENT14" 255 "END" ;
VAL_ 1992 EPBL_infoBuildType 0 "UNKNOWN_BUILD" 1 "PLATFORM_BUILD" 2 "LOCAL_BUILD" 3 "TRACEABLE_CI_BUILD" 4 "MFG_BUILD" ;
VAL_ 1992 EPBL_infoAssemblyId 1 "ASSEMBLY1" 255 "ASSEMBLY_SNA" ;
VAL_ 1999 PM_debugSelector 64 "Mux64" 128 "Mux128" 66 "Mux66" 67 "Mux67" 131 "Mux131" 68 "Mux68" 132 "Mux132" 69 "Mux69" 70 "Mux70" 72 "Mux72" 32 "Mux32" 33 "Mux33" 34 "Mux34" 35 "Mux35" 36 "Mux36" 37 "Mux37" 38 "Mux38" 39 "Mux39" 40 "Mux40" 41 "Mux41" 42 "Mux42" 43 "Mux43" 46 "Mux46" 47 "Mux47" 48 "Mux48" 49 "Mux49" 50 "Mux50" 52 "Mux52" 63 "Mux63" ;
VAL_ 1999 PM_gear 0 "INVALID" 1 "P" 2 "R" 3 "N" 4 "D" 7 "SNA" ;
VAL_ 1999 PM_aebState 0 "UNAVAILABLE" 1 "STANDBY" 2 "ENABLED" 3 "STANDSTILL" 4 "FAULT" 7 "SNA" ;
VAL_ 1999 PM_vehicleHoldState 0 "UNAVAILABLE" 1 "STANDBY" 2 "BLEND_IN" 3 "STANDSTILL" 4 "BLEND_OUT" 5 "PARK" 6 "FAULT" 7 "INIT" ;
VAL_ 1999 PM_regenBackfillState 0 "UNAVAILABLE" 1 "STANDBY" 2 "ACTIVE" ;
VAL_ 2002 BMS_1HzDebug_Id 0 "MUX0" 1 "MUX1" 2 "MUX2" 3 "MUX3" 4 "MUX4" 5 "MUX5" 6 "MUX6" 7 "MUX7" 8 "MUX8" 9 "MUX9" 10 "MUX10" 11 "MUX11" 12 "MUX12" 13 "MUX13" 14 "END" ;
VAL_ 2004 PMR_debugSelector 64 "Mux64" 128 "Mux128" 66 "Mux66" 67 "Mux67" 131 "Mux131" 68 "Mux68" 132 "Mux132" 69 "Mux69" 70 "Mux70" 72 "Mux72" 32 "Mux32" 33 "Mux33" 34 "Mux34" 35 "Mux35" 36 "Mux36" 37 "Mux37" 38 "Mux38" 39 "Mux39" 40 "Mux40" 41 "Mux41" 42 "Mux42" 43 "Mux43" 46 "Mux46" 47 "Mux47" 48 "Mux48" 49 "Mux49" 50 "Mux50" 52 "Mux52" 63 "Mux63" ;
VAL_ 2005 DIR_debugSelector 64 "Mux64" 128 "Mux128" 66 "Mux66" 67 "Mux67" 131 "Mux131" 68 "Mux68" 132 "Mux132" 69 "Mux69" 70 "Mux70" 72 "Mux72" 32 "Mux32" 33 "Mux33" 34 "Mux34" 35 "Mux35" 36 "Mux36" 37 "Mux37" 38 "Mux38" 39 "Mux39" 40 "Mux40" 41 "Mux41" 42 "Mux42" 43 "Mux43" 46 "Mux46" 47 "Mux47" 48 "Mux48" 49 "Mux49" 50 "Mux50" 52 "Mux52" 63 "Mux63" ;
VAL_ 2007 DI_debugSelector 2 "Mux2" 32 "pwrSat" 33 "Mux33" 34 "sysPedal" 35 "onePedalDriving1" 36 "onePedalDriving2" 37 "onePedalDriving3" 38 "pedalTorque1" 39 "regenBackfill" 45 "Mux45" 50 "sysHeat" 53 "Mux53" 65 "Mux65" 66 "Mux66" 67 "Mux67" 68 "Mux68" 69 "Mux69" 75 "longControl" ;
VAL_ 2007 DI_regenBackfillUnavailableReason 0 "NONE" 1 "GTW_DISABLE" 2 "UI_DISABLE" 3 "EBR_UNAVAILABLE" 4 "CRUISE_ACTIVE" 5 "NON_DRIVE_GEAR" 6 "SYSTEM_STATE" 7 "UI_COASTDOWN_MODE" 8 "ACTIVE_DAMPING_UNAVAILABLE" 9 "TRACTION_CONTROL_UNAVAILABLE" 10 "VELOCITY_ESTIMATOR_UNAVAILABLE" 11 "TRACK_MODE_ACTIVE" 12 "PM_DISABLE_REQUEST" ;
VAL_ 2007 DI_regenBackfillAbsSatState 0 "IDLE" 1 "RAMP_OUT" 2 "RAMP_IN" ;
VAL_ 2015 UDS_functionalRequestData_0 0 "0" 1 "1" 2 "2" 3 "3" 4 "4" 5 "5" 6 "6" 7 "7" 8 "8" 9 "9" 10 "10" 11 "11" 12 "12" 13 "13" 14 "14" 15 "15" 16 "16" 17 "17" 18 "18" 19 "19" 20 "20" 21 "21" 22 "22" 23 "23" 24 "24" 25 "25" 26 "26" 27 "27" 28 "28" 29 "29" 30 "30" 31 "31" ;
VAL_ 2024 EPBR_infoIndex 0 "DEPRECATED_0" 1 "DEPRECATED_1" 2 "DEPRECATED_2" 3 "DEPRECATED_3" 4 "DEPRECATED_4" 5 "DEPRECATED_5" 6 "DEPRECATED_6" 7 "DEPRECATED_7" 8 "DEPRECATED_8" 9 "DEPRECATED_9" 10 "BUILD_HWID_COMPONENTID" 11 "PCBAID_ASSYID_USAGEID" 13 "APP_CRC" 14 "BOOTLOADER_SVN" 15 "BOOTLOADER_CRC" 16 "SUBCOMPONENT1" 17 "APP_GITHASH" 18 "BOOTLOADER_GITHASH" 19 "VERSION_DEPRECATED" 20 "UDS_PROTOCOL_BOOTCRC" 23 "SUBCOMPONENT2" 24 "SUBCOMPONENT3" 31 "SUBCOMPONENT4" 32 "SUBCOMPONENT5" 33 "SUBCOMPONENT6" 34 "SUBCOMPONENT7" 35 "SUBCOMPONENT8" 36 "SUBCOMPONENT9" 37 "SUBCOMPONENT10" 38 "SUBCOMPONENT11" 39 "SUBCOMPONENT12" 40 "SUBCOMPONENT13" 41 "SUBCOMPONENT14" 255 "END" ;
VAL_ 2024 EPBR_infoBuildType 0 "UNKNOWN_BUILD" 1 "PLATFORM_BUILD" 2 "LOCAL_BUILD" 3 "TRACEABLE_CI_BUILD" 4 "MFG_BUILD" ;
VAL_ 2024 EPBR_infoAssemblyId 1 "ASSEMBLY1" 255 "ASSEMBLY_SNA" ;
VAL_ 2033 GTW_hrlIndex 1 "Mux1" 2 "Mux2" ;
VAL_ 2033 GTW_hrlState 0 "DISABLED" 1 "ENABLED" ;
VAL_ 2033 GTW_hrlTriggerType 0 "UDPAPI" 1 "EVENT" 2 "GAME_MODE" 3 "CONTINUOUS" 15 "NONE" ;
VAL_ 2034 BMS_10HzDebug_Id 0 "STATE" 1 "AHR_COUNTER" 2 "ISOLATION" 3 "SOC_RESTING" 12 "THM_MODEL_DATA_9" 13 "THM_MODEL_DATA_10" 14 "THM_MODEL_DATA_11" 15 "PACK_VOLTAGES" 16 "HYST" 17 "CAC_1" 18 "CAC_2" 19 "CAC_3" 20 "WAKE_TIMERS" 21 "ADC_VREF" 22 "ADC_CP" 23 "ADC_DCLINK" 24 "ADC_MISC" 25 "ADC_FLOOD" 26 "POWER_PREDICTION_1" 27 "POWER_PREDICTION_2" 28 "POWER_PREDICTION_3" 29 "SLEEP_WAKE" 30 "STANDBY_SUPPLY" 31 "DRIVE_LIMITS" 32 "SOC_BY_AH" 33 "THM_TARGETS" ;
VAL_ 2034 BMS_sleepState 0 "IDLE" 1 "WAIT_FOR_BUS_SILENCE" 2 "READY" 3 "GOING_TO_SLEEP" 4 "SLEEPING" 5 "ABORT" 6 "FAULT" 7 "MIA" 8 "UNKNOWN" 9 "COUNT" ;
VAL_ 2043 UI_debugDampingRequestFLC 255 "SNA" ;
VAL_ 2043 UI_debugDampingRequestFLR 255 "SNA" ;
VAL_ 2043 UI_debugDampingRequestFRC 255 "SNA" ;
VAL_ 2043 UI_debugDampingRequestFRR 255 "SNA" ;
VAL_ 2043 UI_debugDampingRequestRLC 255 "SNA" ;
VAL_ 2043 UI_debugDampingRequestRLR 255 "SNA" ;
VAL_ 2043 UI_debugDampingRequestRRC 255 "SNA" ;
VAL_ 2043 UI_debugDampingRequestRRR 255 "SNA" ;
VAL_ 2046 PCS2_DRLog_CPU0_SampleRate_18V0_boost_duty 127 "SNA" ;
VAL_ 2046 PCS2_DRLog_CPU0_SampleRate_18V0_buck_duty 127 "SNA" ;
VAL_ 2046 PCS2_DRLog_CPU1_SampleRate_18V0_boost_duty 127 "SNA" ;
VAL_ 2046 PCS2_DRLog_CPU3_SampleRate_18V0_boost_duty 127 "SNA" ;
VAL_ 2046 PCS2_DRLog_CPU0_Index_18V0_boost_duty 127 "SNA" ;
VAL_ 2046 PCS2_DRLog_CPU0_Index_18V0_buck_duty 127 "SNA" ;
VAL_ 2046 PCS2_DRLog_CPU1_Index_18V0_boost_duty 127 "SNA" ;
VAL_ 2046 PCS2_DRLog_CPU3_Index_18V0_boost_duty 127 "SNA" ;
VAL_ 2046 PCS2_DRLog_CPU0_Sample_18V0_boost_duty 127 "SNA" ;
VAL_ 2046 PCS2_DRLog_CPU0_Sample_18V0_buck_duty 127 "SNA" ;
VAL_ 2046 PCS2_DRLog_CPU1_Sample_18V0_boost_duty 127 "SNA" ;
VAL_ 2046 PCS2_DRLog_CPU3_Sample_18V0_boost_duty 127 "SNA" ;
